[part 1 of 3: package /STELLANTIS/EPT/ASWCs]
AUTOSAR XML (schema 4-2-2)
package /STELLANTIS/EPT/ASWCs
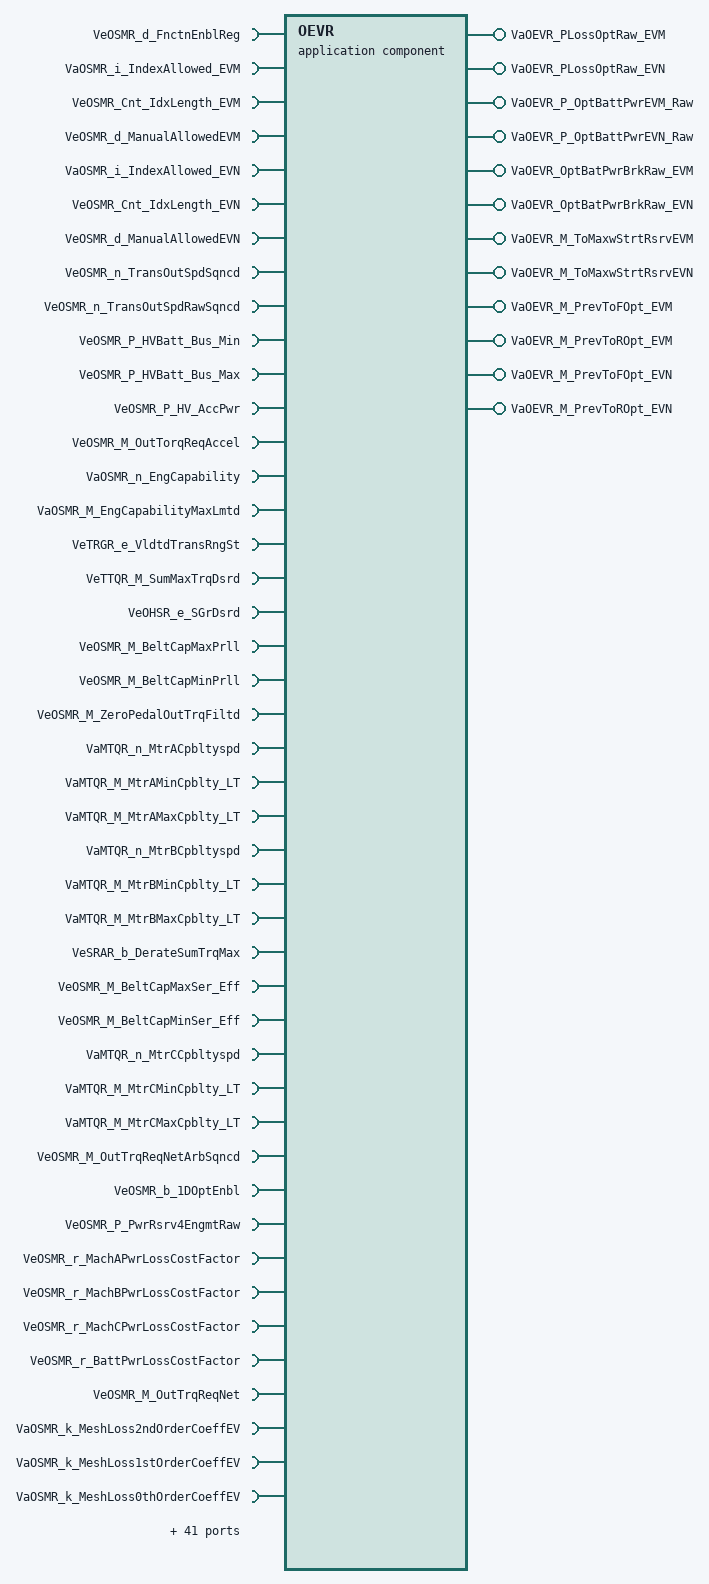
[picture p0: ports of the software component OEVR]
  application sw component type OEVR
    57 x require port:
      VeOSMR_d_FnctnEnblReg: variation-point={short-label=vpVeOSMR_d_FnctnEnblReg, sw-syscond=1}, nonqueued-receiver-com-spec{data-element=Value, init-value=0}, required-interface=VeOSMR_d_FnctnEnblReg
      VaOSMR_i_IndexAllowed_EVM: variation-point={short-label=vpVaOSMR_i_IndexAllowed_EVM, sw-syscond=1}, nonqueued-receiver-com-spec{data-element=Value, init-value=9 x 0}, required-interface=VaOSMR_i_IndexAllowed_EVM
      VeOSMR_Cnt_IdxLength_EVM: variation-point={short-label=vpVeOSMR_Cnt_IdxLength_EVM, sw-syscond=1}, nonqueued-receiver-com-spec{data-element=Value, init-value=0}, required-interface=VeOSMR_Cnt_IdxLength_EVM
      VeOSMR_d_ManualAllowedEVM: variation-point={short-label=vpVeOSMR_d_ManualAllowedEVM, sw-syscond=1}, nonqueued-receiver-com-spec{data-element=Value, init-value=0}, required-interface=VeOSMR_d_ManualAllowedEVM
      VaOSMR_i_IndexAllowed_EVN: variation-point={short-label=vpVaOSMR_i_IndexAllowed_EVN, sw-syscond=1}, nonqueued-receiver-com-spec{data-element=Value, init-value=9 x 0}, required-interface=VaOSMR_i_IndexAllowed_EVN
      VeOSMR_Cnt_IdxLength_EVN: variation-point={short-label=vpVeOSMR_Cnt_IdxLength_EVN, sw-syscond=1}, nonqueued-receiver-com-spec{data-element=Value, init-value=0}, required-interface=VeOSMR_Cnt_IdxLength_EVN
      VeOSMR_d_ManualAllowedEVN: variation-point={short-label=vpVeOSMR_d_ManualAllowedEVN, sw-syscond=1}, nonqueued-receiver-com-spec{data-element=Value, init-value=0}, required-interface=VeOSMR_d_ManualAllowedEVN
      VeOSMR_n_TransOutSpdSqncd: variation-point={short-label=vpVeOSMR_n_TransOutSpdSqncd, sw-syscond=1}, nonqueued-receiver-com-spec{data-element=Value, init-value=0}, required-interface=VeOSMR_n_TransOutSpdSqncd
      VeOSMR_n_TransOutSpdRawSqncd: nonqueued-receiver-com-spec{data-element=Value, init-value=0}, required-interface=VeOSMR_n_TransOutSpdRawSqncd
      VeOSMR_P_HVBatt_Bus_Min: variation-point={short-label=vpVeOSMR_P_HVBatt_Bus_Min, sw-syscond=1}, nonqueued-receiver-com-spec{data-element=Value, init-value=0}, required-interface=VeOSMR_P_HVBatt_Bus_Min
      VeOSMR_P_HVBatt_Bus_Max: variation-point={short-label=vpVeOSMR_P_HVBatt_Bus_Max, sw-syscond=1}, nonqueued-receiver-com-spec{data-element=Value, init-value=0}, required-interface=VeOSMR_P_HVBatt_Bus_Max
      VeOSMR_P_HV_AccPwr: variation-point={short-label=vpVeOSMR_P_HV_AccPwr, sw-syscond=1}, nonqueued-receiver-com-spec{data-element=Value, init-value=0}, required-interface=VeOSMR_P_HV_AccPwr
      VeOSMR_M_OutTorqReqAccel: variation-point={short-label=vpVeOSMR_M_OutTorqReqAccel, sw-syscond=1}, nonqueued-receiver-com-spec{data-element=Value, init-value=0}, required-interface=VeOSMR_M_OutTorqReqAccel
      VaOSMR_n_EngCapability: nonqueued-receiver-com-spec{data-element=Value, init-value=16 x 0}, required-interface=VaOSMR_n_EngCapability
      VaOSMR_M_EngCapabilityMaxLmtd: nonqueued-receiver-com-spec{data-element=Value, init-value=16 x 0}, required-interface=VaOSMR_M_EngCapabilityMaxLmtd
      VeTRGR_e_VldtdTransRngSt: variation-point={short-label=vpVeTRGR_e_VldtdTransRngSt, sw-syscond=1}, nonqueued-receiver-com-spec{data-element=Value, init-value=CeTRGR_e_NoSelectionAvailable}, required-interface=VeTRGR_e_VldtdTransRngSt
      VeTTQR_M_SumMaxTrqDsrd: variation-point={short-label=vpVeTTQR_M_SumMaxTrqDsrd, sw-syscond=1}, nonqueued-receiver-com-spec{data-element=Value, init-value=0}, required-interface=VeTTQR_M_SumMaxTrqDsrd
      VeOHSR_e_SGrDsrd: nonqueued-receiver-com-spec{data-element=Value, init-value=CeOHSR_e_SG_Reverse}, required-interface=VeOHSR_e_SGrDsrd
      VeOSMR_M_BeltCapMaxPrll: variation-point={short-label=vpVeOSMR_M_BeltCapMaxPrll, sw-syscond=1}, nonqueued-receiver-com-spec{data-element=Value, init-value=0}, required-interface=VeOSMR_M_BeltCapMaxPrll
      VeOSMR_M_BeltCapMinPrll: variation-point={short-label=vpVeOSMR_M_BeltCapMinPrll, sw-syscond=1}, nonqueued-receiver-com-spec{data-element=Value, init-value=0}, required-interface=VeOSMR_M_BeltCapMinPrll
      VeOSMR_M_ZeroPedalOutTrqFiltd: variation-point={short-label=vpVeOSMR_M_ZeroPedalOutTrqFiltd, sw-syscond=1}, nonqueued-receiver-com-spec{data-element=Value, init-value=0}, required-interface=VeOSMR_M_ZeroPedalOutTrqFiltd
      VaMTQR_n_MtrACpbltyspd: variation-point={short-label=vpVaMTQR_n_MtrACpbltyspd, sw-syscond=1}, nonqueued-receiver-com-spec{data-element=Value, init-value=16 x 0}, required-interface=VaMTQR_n_MtrACpbltyspd
      VaMTQR_M_MtrAMinCpblty_LT: variation-point={short-label=vpVaMTQR_M_MtrAMinCpblty_LT, sw-syscond=1}, nonqueued-receiver-com-spec{data-element=Value, init-value=16 x 0}, required-interface=VaMTQR_M_MtrAMinCpblty_LT
      VaMTQR_M_MtrAMaxCpblty_LT: variation-point={short-label=vpVaMTQR_M_MtrAMaxCpblty_LT, sw-syscond=1}, nonqueued-receiver-com-spec{data-element=Value, init-value=16 x 0}, required-interface=VaMTQR_M_MtrAMaxCpblty_LT
      VaMTQR_n_MtrBCpbltyspd: variation-point={short-label=vpVaMTQR_n_MtrBCpbltyspd, sw-syscond=1}, nonqueued-receiver-com-spec{data-element=Value, init-value=16 x 0}, required-interface=VaMTQR_n_MtrBCpbltyspd
      VaMTQR_M_MtrBMinCpblty_LT: variation-point={short-label=vpVaMTQR_M_MtrBMinCpblty_LT, sw-syscond=1}, nonqueued-receiver-com-spec{data-element=Value, init-value=16 x 0}, required-interface=VaMTQR_M_MtrBMinCpblty_LT
      VaMTQR_M_MtrBMaxCpblty_LT: variation-point={short-label=vpVaMTQR_M_MtrBMaxCpblty_LT, sw-syscond=1}, nonqueued-receiver-com-spec{data-element=Value, init-value=16 x 0}, required-interface=VaMTQR_M_MtrBMaxCpblty_LT
      VeSRAR_b_DerateSumTrqMax: variation-point={short-label=vpVeSRAR_b_DerateSumTrqMax, sw-syscond=1}, nonqueued-receiver-com-spec{data-element=Value, init-value=0}, required-interface=VeSRAR_b_DerateSumTrqMax
      VeOSMR_M_BeltCapMaxSer_Eff: variation-point={short-label=vpVeOSMR_M_BeltCapMaxSer_Eff, sw-syscond=1}, nonqueued-receiver-com-spec{data-element=Value, init-value=0}, required-interface=VeOSMR_M_BeltCapMaxSer_Eff
      VeOSMR_M_BeltCapMinSer_Eff: variation-point={short-label=vpVeOSMR_M_BeltCapMinSer_Eff, sw-syscond=1}, nonqueued-receiver-com-spec{data-element=Value, init-value=0}, required-interface=VeOSMR_M_BeltCapMinSer_Eff
      VaMTQR_n_MtrCCpbltyspd: variation-point={short-label=vpVaMTQR_n_MtrCCpbltyspd, sw-syscond=1}, nonqueued-receiver-com-spec{data-element=Value, init-value=16 x 0}, required-interface=VaMTQR_n_MtrCCpbltyspd
      VaMTQR_M_MtrCMinCpblty_LT: variation-point={short-label=vpVaMTQR_M_MtrCMinCpblty_LT, sw-syscond=1}, nonqueued-receiver-com-spec{data-element=Value, init-value=16 x 0}, required-interface=VaMTQR_M_MtrCMinCpblty_LT
      VaMTQR_M_MtrCMaxCpblty_LT: variation-point={short-label=vpVaMTQR_M_MtrCMaxCpblty_LT, sw-syscond=1}, nonqueued-receiver-com-spec{data-element=Value, init-value=16 x 0}, required-interface=VaMTQR_M_MtrCMaxCpblty_LT
      VeOSMR_M_OutTrqReqNetArbSqncd: variation-point={short-label=vpVeOSMR_M_OutTrqReqNetArbSqncd, sw-syscond=1}, nonqueued-receiver-com-spec{data-element=Value, init-value=0}, required-interface=VeOSMR_M_OutTrqReqNetArbSqncd
      VeOSMR_b_1DOptEnbl: variation-point={short-label=vpVeOSMR_b_1DOptEnbl, sw-syscond=1}, nonqueued-receiver-com-spec{data-element=Value, init-value=0}, required-interface=VeOSMR_b_1DOptEnbl
      VeOSMR_P_PwrRsrv4EngmtRaw: variation-point={short-label=vpVeOSMR_P_PwrRsrv4EngmtRaw, sw-syscond=1}, nonqueued-receiver-com-spec{data-element=Value, init-value=0}, required-interface=VeOSMR_P_PwrRsrv4EngmtRaw
      VeOSMR_r_MachAPwrLossCostFactor: variation-point={short-label=vpVeOSMR_r_MachAPwrLossCostFactor, sw-syscond=1}, nonqueued-receiver-com-spec{data-element=Value, init-value=0}, required-interface=VeOSMR_r_MachAPwrLossCostFactor
      VeOSMR_r_MachBPwrLossCostFactor: variation-point={short-label=vpVeOSMR_r_MachBPwrLossCostFactor, sw-syscond=1}, nonqueued-receiver-com-spec{data-element=Value, init-value=0}, required-interface=VeOSMR_r_MachBPwrLossCostFactor
      VeOSMR_r_MachCPwrLossCostFactor: variation-point={short-label=vpVeOSMR_r_MachCPwrLossCostFactor, sw-syscond=1}, nonqueued-receiver-com-spec{data-element=Value, init-value=0}, required-interface=VeOSMR_r_MachCPwrLossCostFactor
      VeOSMR_r_BattPwrLossCostFactor: variation-point={short-label=vpVeOSMR_r_BattPwrLossCostFactor, sw-syscond=1}, nonqueued-receiver-com-spec{data-element=Value, init-value=0}, required-interface=VeOSMR_r_BattPwrLossCostFactor
      VeOSMR_M_OutTrqReqNet: variation-point={short-label=vpVeOSMR_M_OutTrqReqNet, sw-syscond=1}, nonqueued-receiver-com-spec{data-element=Value, init-value=0}, required-interface=VeOSMR_M_OutTrqReqNet
      VaOSMR_k_MeshLoss2ndOrderCoeffEV: variation-point={short-label=vpVaOSMR_k_MeshLoss2ndOrderCoeffEV, sw-syscond=1}, nonqueued-receiver-com-spec{data-element=Value, init-value=9 x 0}, required-interface=VaOSMR_k_MeshLoss2ndOrderCoeffEV
      VaOSMR_k_MeshLoss1stOrderCoeffEV: variation-point={short-label=vpVaOSMR_k_MeshLoss1stOrderCoeffEV, sw-syscond=1}, nonqueued-receiver-com-spec{data-element=Value, init-value=9 x 0}, required-interface=VaOSMR_k_MeshLoss1stOrderCoeffEV
      VaOSMR_k_MeshLoss0thOrderCoeffEV: variation-point={short-label=vpVaOSMR_k_MeshLoss0thOrderCoeffEV, sw-syscond=1}, nonqueued-receiver-com-spec{data-element=Value, init-value=9 x 0}, required-interface=VaOSMR_k_MeshLoss0thOrderCoeffEV
      VeOSMR_M_ToFront4x4_Max: variation-point={short-label=vpVeOSMR_M_ToFront4x4_Max, sw-syscond=1}, nonqueued-receiver-com-spec{data-element=Value, init-value=0}, required-interface=VeOSMR_M_ToFront4x4_Max
      VeOSMR_M_ToFront4x4_Min: variation-point={short-label=vpVeOSMR_M_ToFront4x4_Min, sw-syscond=1}, nonqueued-receiver-com-spec{data-element=Value, init-value=0}, required-interface=VeOSMR_M_ToFront4x4_Min
      VeOSMR_M_ToRear4x4_Max: variation-point={short-label=vpVeOSMR_M_ToRear4x4_Max, sw-syscond=1}, nonqueued-receiver-com-spec{data-element=Value, init-value=0}, required-interface=VeOSMR_M_ToRear4x4_Max
      VeOSMR_M_ToRear4x4_Min: variation-point={short-label=vpVeOSMR_M_ToRear4x4_Min, sw-syscond=1}, nonqueued-receiver-com-spec{data-element=Value, init-value=0}, required-interface=VeOSMR_M_ToRear4x4_Min
      VeOSMR_b_StgcRIPEnblOutTorqAccel: variation-point={short-label=vpVeOSMR_b_StgcRIPEnblOutTorqAccel, sw-syscond=1}, nonqueued-receiver-com-spec{data-element=Value, init-value=0}, required-interface=VeOSMR_b_StgcRIPEnblOutTorqAccel
      VeOSMR_b_StgcRIPEnblOutTorqNet: variation-point={short-label=vpVeOSMR_b_StgcRIPEnblOutTorqNet, sw-syscond=1}, nonqueued-receiver-com-spec{data-element=Value, init-value=0}, required-interface=VeOSMR_b_StgcRIPEnblOutTorqNet
      VeOSMR_r_StgcRIPratioOutTorqAccel: variation-point={short-label=vpVeOSMR_r_StgcRIPratioOutTorqAccel, sw-syscond=1}, nonqueued-receiver-com-spec{data-element=Value, init-value=0}, required-interface=VeOSMR_r_StgcRIPratioOutTorqAccel
      VeOSMR_r_StgcRIPratioOutTorqNet: variation-point={short-label=vpVeOSMR_r_StgcRIPratioOutTorqNet, sw-syscond=1}, nonqueued-receiver-com-spec{data-element=Value, init-value=0}, required-interface=VeOSMR_r_StgcRIPratioOutTorqNet
      VaOSMR_M_ToFToRLimOL: variation-point={short-label=vpVaOSMR_M_ToFToRLimOL, sw-syscond=1}, nonqueued-receiver-com-spec{data-element=Value, init-value=[0, 0, 0, 0]}, required-interface=VaOSMR_M_ToFToRLimOL
      VaOSMR_n_NC1Max_EVN: variation-point={short-label=vpVaOSMR_n_NC1Max_EVN, sw-syscond=1}, nonqueued-receiver-com-spec{data-element=Value, init-value=9 x 0}, required-interface=VaOSMR_n_NC1Max_EVN
      VaOSMR_n_NC1Min_EVN: variation-point={short-label=vpVaOSMR_n_NC1Min_EVN, sw-syscond=1}, nonqueued-receiver-com-spec{data-element=Value, init-value=9 x 0}, required-interface=VaOSMR_n_NC1Min_EVN
      VaOSMR_n_NC2Max_EVN: variation-point={short-label=vpVaOSMR_n_NC2Max_EVN, sw-syscond=1}, nonqueued-receiver-com-spec{data-element=Value, init-value=9 x 0}, required-interface=VaOSMR_n_NC2Max_EVN
      VaOSMR_n_NC2Min_EVN: variation-point={short-label=vpVaOSMR_n_NC2Min_EVN, sw-syscond=1}, nonqueued-receiver-com-spec{data-element=Value, init-value=9 x 0}, required-interface=VaOSMR_n_NC2Min_EVN
    12 x provide port, all with nonqueued-sender-com-spec{data-element=Value, init-value=9 x 0}:
      VaOEVR_PLossOptRaw_EVM: provided-interface=VaOEVR_PLossOptRaw_EVM
      VaOEVR_PLossOptRaw_EVN: provided-interface=VaOEVR_PLossOptRaw_EVN
      VaOEVR_P_OptBattPwrEVM_Raw: provided-interface=VaOEVR_P_OptBattPwrEVM_Raw
      VaOEVR_P_OptBattPwrEVN_Raw: provided-interface=VaOEVR_P_OptBattPwrEVN_Raw
      VaOEVR_OptBatPwrBrkRaw_EVM: provided-interface=VaOEVR_OptBatPwrBrkRaw_EVM
      VaOEVR_OptBatPwrBrkRaw_EVN: provided-interface=VaOEVR_OptBatPwrBrkRaw_EVN
      VaOEVR_M_ToMaxwStrtRsrvEVM: provided-interface=VaOEVR_M_ToMaxwStrtRsrvEVM
      VaOEVR_M_ToMaxwStrtRsrvEVN: provided-interface=VaOEVR_M_ToMaxwStrtRsrvEVN
      VaOEVR_M_PrevToFOpt_EVM: provided-interface=VaOEVR_M_PrevToFOpt_EVM
      VaOEVR_M_PrevToROpt_EVM: provided-interface=VaOEVR_M_PrevToROpt_EVM
      VaOEVR_M_PrevToFOpt_EVN: provided-interface=VaOEVR_M_PrevToFOpt_EVN
      VaOEVR_M_PrevToROpt_EVN: provided-interface=VaOEVR_M_PrevToROpt_EVN
    129 x require port:
      CaOPTR_r_TimpMaxArray: parameter-require-com-spec{init-value=CaOPTR_r_TimpMaxArray_CaOPTR_r_TimpMaxArray:[CaOPTR_r_TimpMaxArray_CaOPTR_r_TimpMaxArray_rt_Array_Float_16_1:100000, CaOPTR_r_TimpMaxArray_CaOPTR_r_TimpMaxArray_rt_Array_Float_16_2:100000, CaOPTR_r_TimpMaxArray_CaOPTR_r_TimpMaxArray_rt_Array_Float_16_3:100000, CaOPTR_r_TimpMaxArray_CaOPTR_r_TimpMaxArray_rt_Array_Float_16_4:100000, CaOPTR_r_TimpMaxArray_CaOPTR_r_TimpMaxArray_rt_Array_Float_16_5:100000, CaOPTR_r_TimpMaxArray_CaOPTR_r_TimpMaxArray_rt_Array_Float_16_6:100000, CaOPTR_r_TimpMaxArray_CaOPTR_r_TimpMaxArray_rt_Array_Float_16_7:100000, CaOPTR_r_TimpMaxArray_CaOPTR_r_TimpMaxArray_rt_Array_Float_16_8:100000, CaOPTR_r_TimpMaxArray_CaOPTR_r_TimpMaxArray_rt_Array_Float_16_9:100000, CaOPTR_r_TimpMaxArray_CaOPTR_r_TimpMaxArray_rt_Array_Float_16_10:100000, CaOPTR_r_TimpMaxArray_CaOPTR_r_TimpMaxArray_rt_Array_Float_16_11:100000, CaOPTR_r_TimpMaxArray_CaOPTR_r_TimpMaxArray_rt_Array_Float_16_12:100000, CaOPTR_r_TimpMaxArray_CaOPTR_r_TimpMaxArray_rt_Array_Float_16_13:100000, CaOPTR_r_TimpMaxArray_CaOPTR_r_TimpMaxArray_rt_Array_Float_16_14:100000, CaOPTR_r_TimpMaxArray_CaOPTR_r_TimpMaxArray_rt_Array_Float_16_15:100000, CaOPTR_r_TimpMaxArray_CaOPTR_r_TimpMaxArray_rt_Array_Float_16_16:100000], parameter=CaOPTR_r_TimpMaxArray}, required-interface=CaOPTR_r_TimpMaxArray
      CaOPTR_r_ZeroArray: parameter-require-com-spec{init-value=CaOPTR_r_ZeroArray_CaOPTR_r_ZeroArray:[CaOPTR_r_ZeroArray_CaOPTR_r_ZeroArray_rt_Array_Float_9_1:0, CaOPTR_r_ZeroArray_CaOPTR_r_ZeroArray_rt_Array_Float_9_2:0, CaOPTR_r_ZeroArray_CaOPTR_r_ZeroArray_rt_Array_Float_9_3:0, CaOPTR_r_ZeroArray_CaOPTR_r_ZeroArray_rt_Array_Float_9_4:0, CaOPTR_r_ZeroArray_CaOPTR_r_ZeroArray_rt_Array_Float_9_5:0, CaOPTR_r_ZeroArray_CaOPTR_r_ZeroArray_rt_Array_Float_9_6:0, CaOPTR_r_ZeroArray_CaOPTR_r_ZeroArray_rt_Array_Float_9_7:0, CaOPTR_r_ZeroArray_CaOPTR_r_ZeroArray_rt_Array_Float_9_8:0, CaOPTR_r_ZeroArray_CaOPTR_r_ZeroArray_rt_Array_Float_9_9:0], parameter=CaOPTR_r_ZeroArray}, required-interface=CaOPTR_r_ZeroArray
      HaOPTR_r_NimpCalcEqnMtrx: parameter-require-com-spec{init-value=HaOPTR_r_NimpCalcEqnMtrx_HaOPTR_r_NimpCalcEqnMtrx:[HaOPTR_r_NimpCalcEqnMtrx_HaOPTR_r_NimpCalcEqnMtrx_rt_Array_Float_3_1:0, HaOPTR_r_NimpCalcEqnMtrx_HaOPTR_r_NimpCalcEqnMtrx_rt_Array_Float_3_2:0, HaOPTR_r_NimpCalcEqnMtrx_HaOPTR_r_NimpCalcEqnMtrx_rt_Array_Float_3_3:0], parameter=HaOPTR_r_NimpCalcEqnMtrx}, required-interface=HaOPTR_r_NimpCalcEqnMtrx
      HaOPTR_r_NturbCalcEqnMtrx: parameter-require-com-spec{init-value=HaOPTR_r_NturbCalcEqnMtrx_HaOPTR_r_NturbCalcEqnMtrx:[HaOPTR_r_NturbCalcEqnMtrx_HaOPTR_r_NturbCalcEqnMtrx_rt_Array_Float_3_1:0, HaOPTR_r_NturbCalcEqnMtrx_HaOPTR_r_NturbCalcEqnMtrx_rt_Array_Float_3_2:0, HaOPTR_r_NturbCalcEqnMtrx_HaOPTR_r_NturbCalcEqnMtrx_rt_Array_Float_3_3:0], parameter=HaOPTR_r_NturbCalcEqnMtrx}, required-interface=HaOPTR_r_NturbCalcEqnMtrx
      KaHSCR_k_Donut_Space_Coefs_A1: parameter-require-com-spec{init-value=KaHSCR_k_Donut_Space_Coefs_A1_KaHSCR_k_Donut_Space_Coefs_A1:[KaHSCR_k_Donut_Space_Coefs_A1_KaHSCR_k_Donut_Space_Coefs_A1_rt_Array_Float_34_1:0.0258900001645088, KaHSCR_k_Donut_Space_Coefs_A1_KaHSCR_k_Donut_Space_Coefs_A1_rt_Array_Float_34_2:0.0258900001645088, KaHSCR_k_Donut_Space_Coefs_A1_KaHSCR_k_Donut_Space_Coefs_A1_rt_Array_Float_34_3:0.0351000018417835, KaHSCR_k_Donut_Space_Coefs_A1_KaHSCR_k_Donut_Space_Coefs_A1_rt_Array_Float_34_4:0.0372599996626377, KaHSCR_k_Donut_Space_Coefs_A1_KaHSCR_k_Donut_Space_Coefs_A1_rt_Array_Float_34_5:0.0378299988806248, KaHSCR_k_Donut_Space_Coefs_A1_KaHSCR_k_Donut_Space_Coefs_A1_rt_Array_Float_34_6:0.0382400006055832, KaHSCR_k_Donut_Space_Coefs_A1_KaHSCR_k_Donut_Space_Coefs_A1_rt_Array_Float_34_7:0.0386399887502193, KaHSCR_k_Donut_Space_Coefs_A1_KaHSCR_k_Donut_Space_Coefs_A1_rt_Array_Float_34_8:0.0405225306749344, KaHSCR_k_Donut_Space_Coefs_A1_KaHSCR_k_Donut_Space_Coefs_A1_rt_Array_Float_34_9:0.0411508604884148, KaHSCR_k_Donut_Space_Coefs_A1_KaHSCR_k_Donut_Space_Coefs_A1_rt_Array_Float_34_10:0.0418944396078587, KaHSCR_k_Donut_Space_Coefs_A1_KaHSCR_k_Donut_Space_Coefs_A1_rt_Array_Float_34_11:0.0425894781947136, KaHSCR_k_Donut_Space_Coefs_A1_KaHSCR_k_Donut_Space_Coefs_A1_rt_Array_Float_34_12:0.0431920886039734, KaHSCR_k_Donut_Space_Coefs_A1_KaHSCR_k_Donut_Space_Coefs_A1_rt_Array_Float_34_13:0.0436835289001465, KaHSCR_k_Donut_Space_Coefs_A1_KaHSCR_k_Donut_Space_Coefs_A1_rt_Array_Float_34_14:0.0443845391273499, KaHSCR_k_Donut_Space_Coefs_A1_KaHSCR_k_Donut_Space_Coefs_A1_rt_Array_Float_34_15:0.0450701601803303, KaHSCR_k_Donut_Space_Coefs_A1_KaHSCR_k_Donut_Space_Coefs_A1_rt_Array_Float_34_16:0.0456303507089615, KaHSCR_k_Donut_Space_Coefs_A1_KaHSCR_k_Donut_Space_Coefs_A1_rt_Array_Float_34_17:0.0466340184211731, KaHSCR_k_Donut_Space_Coefs_A1_KaHSCR_k_Donut_Space_Coefs_A1_rt_Array_Float_34_18:0.0474497117102146, KaHSCR_k_Donut_Space_Coefs_A1_KaHSCR_k_Donut_Space_Coefs_A1_rt_Array_Float_34_19:0.0479614101350307, KaHSCR_k_Donut_Space_Coefs_A1_KaHSCR_k_Donut_Space_Coefs_A1_rt_Array_Float_34_20:0.0484260395169258, KaHSCR_k_Donut_Space_Coefs_A1_KaHSCR_k_Donut_Space_Coefs_A1_rt_Array_Float_34_21:0.0488490909337997, KaHSCR_k_Donut_Space_Coefs_A1_KaHSCR_k_Donut_Space_Coefs_A1_rt_Array_Float_34_22:0.0494564808905125, KaHSCR_k_Donut_Space_Coefs_A1_KaHSCR_k_Donut_Space_Coefs_A1_rt_Array_Float_34_23:0.050324771553278, KaHSCR_k_Donut_Space_Coefs_A1_KaHSCR_k_Donut_Space_Coefs_A1_rt_Array_Float_34_24:0.0511159785091877, KaHSCR_k_Donut_Space_Coefs_A1_KaHSCR_k_Donut_Space_Coefs_A1_rt_Array_Float_34_25:0.0516291595995426, KaHSCR_k_Donut_Space_Coefs_A1_KaHSCR_k_Donut_Space_Coefs_A1_rt_Array_Float_34_26:0.051756490021944, KaHSCR_k_Donut_Space_Coefs_A1_KaHSCR_k_Donut_Space_Coefs_A1_rt_Array_Float_34_27:0.0519887804985046, KaHSCR_k_Donut_Space_Coefs_A1_KaHSCR_k_Donut_Space_Coefs_A1_rt_Array_Float_34_28:0.0530802011489868, KaHSCR_k_Donut_Space_Coefs_A1_KaHSCR_k_Donut_Space_Coefs_A1_rt_Array_Float_34_29:0.0536961182951927, KaHSCR_k_Donut_Space_Coefs_A1_KaHSCR_k_Donut_Space_Coefs_A1_rt_Array_Float_34_30:0.054239921271801, KaHSCR_k_Donut_Space_Coefs_A1_KaHSCR_k_Donut_Space_Coefs_A1_rt_Array_Float_34_31:0.0550949200987816, KaHSCR_k_Donut_Space_Coefs_A1_KaHSCR_k_Donut_Space_Coefs_A1_rt_Array_Float_34_32:0.0563113614916801, KaHSCR_k_Donut_Space_Coefs_A1_KaHSCR_k_Donut_Space_Coefs_A1_rt_Array_Float_34_33:0.0575419701635838, KaHSCR_k_Donut_Space_Coefs_A1_KaHSCR_k_Donut_Space_Coefs_A1_rt_Array_Float_34_34:0.0587838590145111], parameter=KaHSCR_k_Donut_Space_Coefs_A1}, required-interface=KaHSCR_k_Donut_Space_Coefs_A1
      KaHSCR_k_Donut_Space_Coefs_A2: parameter-require-com-spec{init-value=KaHSCR_k_Donut_Space_Coefs_A2_KaHSCR_k_Donut_Space_Coefs_A2:[KaHSCR_k_Donut_Space_Coefs_A2_KaHSCR_k_Donut_Space_Coefs_A2_rt_Array_Float_34_1:-5.04978709276475E-18, KaHSCR_k_Donut_Space_Coefs_A2_KaHSCR_k_Donut_Space_Coefs_A2_rt_Array_Float_34_2:-5.04978709276475E-18, KaHSCR_k_Donut_Space_Coefs_A2_KaHSCR_k_Donut_Space_Coefs_A2_rt_Array_Float_34_3:0.639999985694885, KaHSCR_k_Donut_Space_Coefs_A2_KaHSCR_k_Donut_Space_Coefs_A2_rt_Array_Float_34_4:1.19000005722046, KaHSCR_k_Donut_Space_Coefs_A2_KaHSCR_k_Donut_Space_Coefs_A2_rt_Array_Float_34_5:1.75999999046326, KaHSCR_k_Donut_Space_Coefs_A2_KaHSCR_k_Donut_Space_Coefs_A2_rt_Array_Float_34_6:2.30999994277954, KaHSCR_k_Donut_Space_Coefs_A2_KaHSCR_k_Donut_Space_Coefs_A2_rt_Array_Float_34_7:2.85999989509583, KaHSCR_k_Donut_Space_Coefs_A2_KaHSCR_k_Donut_Space_Coefs_A2_rt_Array_Float_34_8:3.33561706542969, KaHSCR_k_Donut_Space_Coefs_A2_KaHSCR_k_Donut_Space_Coefs_A2_rt_Array_Float_34_9:3.81586289405823, KaHSCR_k_Donut_Space_Coefs_A2_KaHSCR_k_Donut_Space_Coefs_A2_rt_Array_Float_34_10:4.27816390991211, KaHSCR_k_Donut_Space_Coefs_A2_KaHSCR_k_Donut_Space_Coefs_A2_rt_Array_Float_34_11:4.72691488265991, KaHSCR_k_Donut_Space_Coefs_A2_KaHSCR_k_Donut_Space_Coefs_A2_rt_Array_Float_34_12:5.16561794281006, KaHSCR_k_Donut_Space_Coefs_A2_KaHSCR_k_Donut_Space_Coefs_A2_rt_Array_Float_34_13:5.61427307128906, KaHSCR_k_Donut_Space_Coefs_A2_KaHSCR_k_Donut_Space_Coefs_A2_rt_Array_Float_34_14:6.01499605178833, KaHSCR_k_Donut_Space_Coefs_A2_KaHSCR_k_Donut_Space_Coefs_A2_rt_Array_Float_34_15:6.42061996459961, KaHSCR_k_Donut_Space_Coefs_A2_KaHSCR_k_Donut_Space_Coefs_A2_rt_Array_Float_34_16:6.81864976882935, KaHSCR_k_Donut_Space_Coefs_A2_KaHSCR_k_Donut_Space_Coefs_A2_rt_Array_Float_34_17:7.15260887145996, KaHSCR_k_Donut_Space_Coefs_A2_KaHSCR_k_Donut_Space_Coefs_A2_rt_Array_Float_34_18:7.50815296173096, KaHSCR_k_Donut_Space_Coefs_A2_KaHSCR_k_Donut_Space_Coefs_A2_rt_Array_Float_34_19:7.88588094711304, KaHSCR_k_Donut_Space_Coefs_A2_KaHSCR_k_Donut_Space_Coefs_A2_rt_Array_Float_34_20:8.26707172393799, KaHSCR_k_Donut_Space_Coefs_A2_KaHSCR_k_Donut_Space_Coefs_A2_rt_Array_Float_34_21:8.64353656768799, KaHSCR_k_Donut_Space_Coefs_A2_KaHSCR_k_Donut_Space_Coefs_A2_rt_Array_Float_34_22:8.99045372009277, KaHSCR_k_Donut_Space_Coefs_A2_KaHSCR_k_Donut_Space_Coefs_A2_rt_Array_Float_34_23:9.27973079681396, KaHSCR_k_Donut_Space_Coefs_A2_KaHSCR_k_Donut_Space_Coefs_A2_rt_Array_Float_34_24:9.56464672088623, KaHSCR_k_Donut_Space_Coefs_A2_KaHSCR_k_Donut_Space_Coefs_A2_rt_Array_Float_34_25:9.88457489013672, KaHSCR_k_Donut_Space_Coefs_A2_KaHSCR_k_Donut_Space_Coefs_A2_rt_Array_Float_34_26:10.2705402374268, KaHSCR_k_Donut_Space_Coefs_A2_KaHSCR_k_Donut_Space_Coefs_A2_rt_Array_Float_34_27:10.658860206604, KaHSCR_k_Donut_Space_Coefs_A2_KaHSCR_k_Donut_Space_Coefs_A2_rt_Array_Float_34_28:10.8600997924805, KaHSCR_k_Donut_Space_Coefs_A2_KaHSCR_k_Donut_Space_Coefs_A2_rt_Array_Float_34_29:11.1487503051758, KaHSCR_k_Donut_Space_Coefs_A2_KaHSCR_k_Donut_Space_Coefs_A2_rt_Array_Float_34_30:11.4441699981689, KaHSCR_k_Donut_Space_Coefs_A2_KaHSCR_k_Donut_Space_Coefs_A2_rt_Array_Float_34_31:11.6732902526855, KaHSCR_k_Donut_Space_Coefs_A2_KaHSCR_k_Donut_Space_Coefs_A2_rt_Array_Float_34_32:11.8130502700806, KaHSCR_k_Donut_Space_Coefs_A2_KaHSCR_k_Donut_Space_Coefs_A2_rt_Array_Float_34_33:11.9453201293945, KaHSCR_k_Donut_Space_Coefs_A2_KaHSCR_k_Donut_Space_Coefs_A2_rt_Array_Float_34_34:12.0616703033447], parameter=KaHSCR_k_Donut_Space_Coefs_A2}, required-interface=KaHSCR_k_Donut_Space_Coefs_A2
      KaHSCR_k_Donut_Space_Coefs_B1: parameter-require-com-spec{init-value=KaHSCR_k_Donut_Space_Coefs_B1_KaHSCR_k_Donut_Space_Coefs_B1:[KaHSCR_k_Donut_Space_Coefs_B1_KaHSCR_k_Donut_Space_Coefs_B1_rt_Array_Float_34_1:0.0258900001645088, KaHSCR_k_Donut_Space_Coefs_B1_KaHSCR_k_Donut_Space_Coefs_B1_rt_Array_Float_34_2:0.0258900001645088, KaHSCR_k_Donut_Space_Coefs_B1_KaHSCR_k_Donut_Space_Coefs_B1_rt_Array_Float_34_3:0.0351000018417835, KaHSCR_k_Donut_Space_Coefs_B1_KaHSCR_k_Donut_Space_Coefs_B1_rt_Array_Float_34_4:0.0372599996626377, KaHSCR_k_Donut_Space_Coefs_B1_KaHSCR_k_Donut_Space_Coefs_B1_rt_Array_Float_34_5:0.0378299988806248, KaHSCR_k_Donut_Space_Coefs_B1_KaHSCR_k_Donut_Space_Coefs_B1_rt_Array_Float_34_6:0.0382400006055832, KaHSCR_k_Donut_Space_Coefs_B1_KaHSCR_k_Donut_Space_Coefs_B1_rt_Array_Float_34_7:0.0386399887502193, KaHSCR_k_Donut_Space_Coefs_B1_KaHSCR_k_Donut_Space_Coefs_B1_rt_Array_Float_34_8:0.0405225306749344, KaHSCR_k_Donut_Space_Coefs_B1_KaHSCR_k_Donut_Space_Coefs_B1_rt_Array_Float_34_9:0.0411508604884148, KaHSCR_k_Donut_Space_Coefs_B1_KaHSCR_k_Donut_Space_Coefs_B1_rt_Array_Float_34_10:0.0418944396078587, KaHSCR_k_Donut_Space_Coefs_B1_KaHSCR_k_Donut_Space_Coefs_B1_rt_Array_Float_34_11:0.0425894781947136, KaHSCR_k_Donut_Space_Coefs_B1_KaHSCR_k_Donut_Space_Coefs_B1_rt_Array_Float_34_12:0.0431920886039734, KaHSCR_k_Donut_Space_Coefs_B1_KaHSCR_k_Donut_Space_Coefs_B1_rt_Array_Float_34_13:0.0436835289001465, KaHSCR_k_Donut_Space_Coefs_B1_KaHSCR_k_Donut_Space_Coefs_B1_rt_Array_Float_34_14:0.0443845391273499, KaHSCR_k_Donut_Space_Coefs_B1_KaHSCR_k_Donut_Space_Coefs_B1_rt_Array_Float_34_15:0.0450701601803303, KaHSCR_k_Donut_Space_Coefs_B1_KaHSCR_k_Donut_Space_Coefs_B1_rt_Array_Float_34_16:0.0456303507089615, KaHSCR_k_Donut_Space_Coefs_B1_KaHSCR_k_Donut_Space_Coefs_B1_rt_Array_Float_34_17:0.0466340184211731, KaHSCR_k_Donut_Space_Coefs_B1_KaHSCR_k_Donut_Space_Coefs_B1_rt_Array_Float_34_18:0.0474497117102146, KaHSCR_k_Donut_Space_Coefs_B1_KaHSCR_k_Donut_Space_Coefs_B1_rt_Array_Float_34_19:0.0479614101350307, KaHSCR_k_Donut_Space_Coefs_B1_KaHSCR_k_Donut_Space_Coefs_B1_rt_Array_Float_34_20:0.0484260395169258, KaHSCR_k_Donut_Space_Coefs_B1_KaHSCR_k_Donut_Space_Coefs_B1_rt_Array_Float_34_21:0.0488490909337997, KaHSCR_k_Donut_Space_Coefs_B1_KaHSCR_k_Donut_Space_Coefs_B1_rt_Array_Float_34_22:0.0494564808905125, KaHSCR_k_Donut_Space_Coefs_B1_KaHSCR_k_Donut_Space_Coefs_B1_rt_Array_Float_34_23:0.050324771553278, KaHSCR_k_Donut_Space_Coefs_B1_KaHSCR_k_Donut_Space_Coefs_B1_rt_Array_Float_34_24:0.0511159785091877, KaHSCR_k_Donut_Space_Coefs_B1_KaHSCR_k_Donut_Space_Coefs_B1_rt_Array_Float_34_25:0.0516291595995426, KaHSCR_k_Donut_Space_Coefs_B1_KaHSCR_k_Donut_Space_Coefs_B1_rt_Array_Float_34_26:0.051756490021944, KaHSCR_k_Donut_Space_Coefs_B1_KaHSCR_k_Donut_Space_Coefs_B1_rt_Array_Float_34_27:0.0519887804985046, KaHSCR_k_Donut_Space_Coefs_B1_KaHSCR_k_Donut_Space_Coefs_B1_rt_Array_Float_34_28:0.0530802011489868, KaHSCR_k_Donut_Space_Coefs_B1_KaHSCR_k_Donut_Space_Coefs_B1_rt_Array_Float_34_29:0.0536961182951927, KaHSCR_k_Donut_Space_Coefs_B1_KaHSCR_k_Donut_Space_Coefs_B1_rt_Array_Float_34_30:0.054239921271801, KaHSCR_k_Donut_Space_Coefs_B1_KaHSCR_k_Donut_Space_Coefs_B1_rt_Array_Float_34_31:0.0550949200987816, KaHSCR_k_Donut_Space_Coefs_B1_KaHSCR_k_Donut_Space_Coefs_B1_rt_Array_Float_34_32:0.0563113614916801, KaHSCR_k_Donut_Space_Coefs_B1_KaHSCR_k_Donut_Space_Coefs_B1_rt_Array_Float_34_33:0.0575419701635838, KaHSCR_k_Donut_Space_Coefs_B1_KaHSCR_k_Donut_Space_Coefs_B1_rt_Array_Float_34_34:0.0587838590145111], parameter=KaHSCR_k_Donut_Space_Coefs_B1}, required-interface=KaHSCR_k_Donut_Space_Coefs_B1
      KaHSCR_k_Donut_Space_Coefs_B2: parameter-require-com-spec{init-value=KaHSCR_k_Donut_Space_Coefs_B2_KaHSCR_k_Donut_Space_Coefs_B2:[KaHSCR_k_Donut_Space_Coefs_B2_KaHSCR_k_Donut_Space_Coefs_B2_rt_Array_Float_34_1:-5.04978709276475E-18, KaHSCR_k_Donut_Space_Coefs_B2_KaHSCR_k_Donut_Space_Coefs_B2_rt_Array_Float_34_2:-5.04978709276475E-18, KaHSCR_k_Donut_Space_Coefs_B2_KaHSCR_k_Donut_Space_Coefs_B2_rt_Array_Float_34_3:0.639999985694885, KaHSCR_k_Donut_Space_Coefs_B2_KaHSCR_k_Donut_Space_Coefs_B2_rt_Array_Float_34_4:1.19000005722046, KaHSCR_k_Donut_Space_Coefs_B2_KaHSCR_k_Donut_Space_Coefs_B2_rt_Array_Float_34_5:1.75999999046326, KaHSCR_k_Donut_Space_Coefs_B2_KaHSCR_k_Donut_Space_Coefs_B2_rt_Array_Float_34_6:2.30999994277954, KaHSCR_k_Donut_Space_Coefs_B2_KaHSCR_k_Donut_Space_Coefs_B2_rt_Array_Float_34_7:2.85999989509583, KaHSCR_k_Donut_Space_Coefs_B2_KaHSCR_k_Donut_Space_Coefs_B2_rt_Array_Float_34_8:3.33561706542969, KaHSCR_k_Donut_Space_Coefs_B2_KaHSCR_k_Donut_Space_Coefs_B2_rt_Array_Float_34_9:3.81586289405823, KaHSCR_k_Donut_Space_Coefs_B2_KaHSCR_k_Donut_Space_Coefs_B2_rt_Array_Float_34_10:4.27816390991211, KaHSCR_k_Donut_Space_Coefs_B2_KaHSCR_k_Donut_Space_Coefs_B2_rt_Array_Float_34_11:4.72691488265991, KaHSCR_k_Donut_Space_Coefs_B2_KaHSCR_k_Donut_Space_Coefs_B2_rt_Array_Float_34_12:5.16561794281006, KaHSCR_k_Donut_Space_Coefs_B2_KaHSCR_k_Donut_Space_Coefs_B2_rt_Array_Float_34_13:5.61427307128906, KaHSCR_k_Donut_Space_Coefs_B2_KaHSCR_k_Donut_Space_Coefs_B2_rt_Array_Float_34_14:6.01499605178833, KaHSCR_k_Donut_Space_Coefs_B2_KaHSCR_k_Donut_Space_Coefs_B2_rt_Array_Float_34_15:6.42061996459961, KaHSCR_k_Donut_Space_Coefs_B2_KaHSCR_k_Donut_Space_Coefs_B2_rt_Array_Float_34_16:6.81864976882935, KaHSCR_k_Donut_Space_Coefs_B2_KaHSCR_k_Donut_Space_Coefs_B2_rt_Array_Float_34_17:7.15260887145996, KaHSCR_k_Donut_Space_Coefs_B2_KaHSCR_k_Donut_Space_Coefs_B2_rt_Array_Float_34_18:7.50815296173096, KaHSCR_k_Donut_Space_Coefs_B2_KaHSCR_k_Donut_Space_Coefs_B2_rt_Array_Float_34_19:7.88588094711304, KaHSCR_k_Donut_Space_Coefs_B2_KaHSCR_k_Donut_Space_Coefs_B2_rt_Array_Float_34_20:8.26707172393799, KaHSCR_k_Donut_Space_Coefs_B2_KaHSCR_k_Donut_Space_Coefs_B2_rt_Array_Float_34_21:8.64353656768799, KaHSCR_k_Donut_Space_Coefs_B2_KaHSCR_k_Donut_Space_Coefs_B2_rt_Array_Float_34_22:8.99045372009277, KaHSCR_k_Donut_Space_Coefs_B2_KaHSCR_k_Donut_Space_Coefs_B2_rt_Array_Float_34_23:9.27973079681396, KaHSCR_k_Donut_Space_Coefs_B2_KaHSCR_k_Donut_Space_Coefs_B2_rt_Array_Float_34_24:9.56464672088623, KaHSCR_k_Donut_Space_Coefs_B2_KaHSCR_k_Donut_Space_Coefs_B2_rt_Array_Float_34_25:9.88457489013672, KaHSCR_k_Donut_Space_Coefs_B2_KaHSCR_k_Donut_Space_Coefs_B2_rt_Array_Float_34_26:10.2705402374268, KaHSCR_k_Donut_Space_Coefs_B2_KaHSCR_k_Donut_Space_Coefs_B2_rt_Array_Float_34_27:10.658860206604, KaHSCR_k_Donut_Space_Coefs_B2_KaHSCR_k_Donut_Space_Coefs_B2_rt_Array_Float_34_28:10.8600997924805, KaHSCR_k_Donut_Space_Coefs_B2_KaHSCR_k_Donut_Space_Coefs_B2_rt_Array_Float_34_29:11.1487503051758, KaHSCR_k_Donut_Space_Coefs_B2_KaHSCR_k_Donut_Space_Coefs_B2_rt_Array_Float_34_30:11.4441699981689, KaHSCR_k_Donut_Space_Coefs_B2_KaHSCR_k_Donut_Space_Coefs_B2_rt_Array_Float_34_31:11.6732902526855, KaHSCR_k_Donut_Space_Coefs_B2_KaHSCR_k_Donut_Space_Coefs_B2_rt_Array_Float_34_32:11.8130502700806, KaHSCR_k_Donut_Space_Coefs_B2_KaHSCR_k_Donut_Space_Coefs_B2_rt_Array_Float_34_33:11.9453201293945, KaHSCR_k_Donut_Space_Coefs_B2_KaHSCR_k_Donut_Space_Coefs_B2_rt_Array_Float_34_34:12.0616703033447], parameter=KaHSCR_k_Donut_Space_Coefs_B2}, required-interface=KaHSCR_k_Donut_Space_Coefs_B2
      KaHSCR_k_Donut_Space_Coefs_C: parameter-require-com-spec{init-value=KaHSCR_k_Donut_Space_Coefs_C_KaHSCR_k_Donut_Space_Coefs_C:[KaHSCR_k_Donut_Space_Coefs_C_KaHSCR_k_Donut_Space_Coefs_C_rt_Array_Float_34_1:0.103308998048306, KaHSCR_k_Donut_Space_Coefs_C_KaHSCR_k_Donut_Space_Coefs_C_rt_Array_Float_34_2:0.103308998048306, KaHSCR_k_Donut_Space_Coefs_C_KaHSCR_k_Donut_Space_Coefs_C_rt_Array_Float_34_3:-0.211907997727394, KaHSCR_k_Donut_Space_Coefs_C_KaHSCR_k_Donut_Space_Coefs_C_rt_Array_Float_34_4:-1.20062398910522, KaHSCR_k_Donut_Space_Coefs_C_KaHSCR_k_Donut_Space_Coefs_C_rt_Array_Float_34_5:-2.85137605667114, KaHSCR_k_Donut_Space_Coefs_C_KaHSCR_k_Donut_Space_Coefs_C_rt_Array_Float_34_6:-5.10159778594971, KaHSCR_k_Donut_Space_Coefs_C_KaHSCR_k_Donut_Space_Coefs_C_rt_Array_Float_34_7:-7.90723323822021, KaHSCR_k_Donut_Space_Coefs_C_KaHSCR_k_Donut_Space_Coefs_C_rt_Array_Float_34_8:-10.5811996459961, KaHSCR_k_Donut_Space_Coefs_C_KaHSCR_k_Donut_Space_Coefs_C_rt_Array_Float_34_9:-14.0026197433472, KaHSCR_k_Donut_Space_Coefs_C_KaHSCR_k_Donut_Space_Coefs_C_rt_Array_Float_34_10:-17.6751308441162, KaHSCR_k_Donut_Space_Coefs_C_KaHSCR_k_Donut_Space_Coefs_C_rt_Array_Float_34_11:-21.6737899780273, KaHSCR_k_Donut_Space_Coefs_C_KaHSCR_k_Donut_Space_Coefs_C_rt_Array_Float_34_12:-26.0248203277588, KaHSCR_k_Donut_Space_Coefs_C_KaHSCR_k_Donut_Space_Coefs_C_rt_Array_Float_34_13:-30.7496299743652, KaHSCR_k_Donut_Space_Coefs_C_KaHSCR_k_Donut_Space_Coefs_C_rt_Array_Float_34_14:-35.452018737793, KaHSCR_k_Donut_Space_Coefs_C_KaHSCR_k_Donut_Space_Coefs_C_rt_Array_Float_34_15:-40.3361701965332, KaHSCR_k_Donut_Space_Coefs_C_KaHSCR_k_Donut_Space_Coefs_C_rt_Array_Float_34_16:-45.6424903869629, KaHSCR_k_Donut_Space_Coefs_C_KaHSCR_k_Donut_Space_Coefs_C_rt_Array_Float_34_17:-50.2698593139648, KaHSCR_k_Donut_Space_Coefs_C_KaHSCR_k_Donut_Space_Coefs_C_rt_Array_Float_34_18:-55.375659942627, KaHSCR_k_Donut_Space_Coefs_C_KaHSCR_k_Donut_Space_Coefs_C_rt_Array_Float_34_19:-61.2313995361328, KaHSCR_k_Donut_Space_Coefs_C_KaHSCR_k_Donut_Space_Coefs_C_rt_Array_Float_34_20:-67.2626876831055, KaHSCR_k_Donut_Space_Coefs_C_KaHSCR_k_Donut_Space_Coefs_C_rt_Array_Float_34_21:-73.5646362304688, KaHSCR_k_Donut_Space_Coefs_C_KaHSCR_k_Donut_Space_Coefs_C_rt_Array_Float_34_22:-79.621467590332, KaHSCR_k_Donut_Space_Coefs_C_KaHSCR_k_Donut_Space_Coefs_C_rt_Array_Float_34_23:-84.9908294677734, KaHSCR_k_Donut_Space_Coefs_C_KaHSCR_k_Donut_Space_Coefs_C_rt_Array_Float_34_24:-90.269172668457, KaHSCR_k_Donut_Space_Coefs_C_KaHSCR_k_Donut_Space_Coefs_C_rt_Array_Float_34_25:-96.3239364624023, KaHSCR_k_Donut_Space_Coefs_C_KaHSCR_k_Donut_Space_Coefs_C_rt_Array_Float_34_26:-104.145500183105, KaHSCR_k_Donut_Space_Coefs_C_KaHSCR_k_Donut_Space_Coefs_C_rt_Array_Float_34_27:-112.130699157715, KaHSCR_k_Donut_Space_Coefs_C_KaHSCR_k_Donut_Space_Coefs_C_rt_Array_Float_34_28:-116.38639831543, KaHSCR_k_Donut_Space_Coefs_C_KaHSCR_k_Donut_Space_Coefs_C_rt_Array_Float_34_29:-122.710998535156, KaHSCR_k_Donut_Space_Coefs_C_KaHSCR_k_Donut_Space_Coefs_C_rt_Array_Float_34_30:-129.441192626953, KaHSCR_k_Donut_Space_Coefs_C_KaHSCR_k_Donut_Space_Coefs_C_rt_Array_Float_34_31:-134.5126953125, KaHSCR_k_Donut_Space_Coefs_C_KaHSCR_k_Donut_Space_Coefs_C_rt_Array_Float_34_32:-137.768402099609, KaHSCR_k_Donut_Space_Coefs_C_KaHSCR_k_Donut_Space_Coefs_C_rt_Array_Float_34_33:-140.760498046875, KaHSCR_k_Donut_Space_Coefs_C_KaHSCR_k_Donut_Space_Coefs_C_rt_Array_Float_34_34:-143.608093261719], parameter=KaHSCR_k_Donut_Space_Coefs_C}, required-interface=KaHSCR_k_Donut_Space_Coefs_C
      KaHSCR_k_Donut_Space_Coefs_C1: parameter-require-com-spec{init-value=KaHSCR_k_Donut_Space_Coefs_C1_KaHSCR_k_Donut_Space_Coefs_C1:[KaHSCR_k_Donut_Space_Coefs_C1_KaHSCR_k_Donut_Space_Coefs_C1_rt_Array_Float_34_1:0.0258900001645088, KaHSCR_k_Donut_Space_Coefs_C1_KaHSCR_k_Donut_Space_Coefs_C1_rt_Array_Float_34_2:0.0258900001645088, KaHSCR_k_Donut_Space_Coefs_C1_KaHSCR_k_Donut_Space_Coefs_C1_rt_Array_Float_34_3:0.0351000018417835, KaHSCR_k_Donut_Space_Coefs_C1_KaHSCR_k_Donut_Space_Coefs_C1_rt_Array_Float_34_4:0.0372599996626377, KaHSCR_k_Donut_Space_Coefs_C1_KaHSCR_k_Donut_Space_Coefs_C1_rt_Array_Float_34_5:0.0378299988806248, KaHSCR_k_Donut_Space_Coefs_C1_KaHSCR_k_Donut_Space_Coefs_C1_rt_Array_Float_34_6:0.0382400006055832, KaHSCR_k_Donut_Space_Coefs_C1_KaHSCR_k_Donut_Space_Coefs_C1_rt_Array_Float_34_7:0.0386399887502193, KaHSCR_k_Donut_Space_Coefs_C1_KaHSCR_k_Donut_Space_Coefs_C1_rt_Array_Float_34_8:0.0405225306749344, KaHSCR_k_Donut_Space_Coefs_C1_KaHSCR_k_Donut_Space_Coefs_C1_rt_Array_Float_34_9:0.0411508604884148, KaHSCR_k_Donut_Space_Coefs_C1_KaHSCR_k_Donut_Space_Coefs_C1_rt_Array_Float_34_10:0.0418944396078587, KaHSCR_k_Donut_Space_Coefs_C1_KaHSCR_k_Donut_Space_Coefs_C1_rt_Array_Float_34_11:0.0425894781947136, KaHSCR_k_Donut_Space_Coefs_C1_KaHSCR_k_Donut_Space_Coefs_C1_rt_Array_Float_34_12:0.0431920886039734, KaHSCR_k_Donut_Space_Coefs_C1_KaHSCR_k_Donut_Space_Coefs_C1_rt_Array_Float_34_13:0.0436835289001465, KaHSCR_k_Donut_Space_Coefs_C1_KaHSCR_k_Donut_Space_Coefs_C1_rt_Array_Float_34_14:0.0443845391273499, KaHSCR_k_Donut_Space_Coefs_C1_KaHSCR_k_Donut_Space_Coefs_C1_rt_Array_Float_34_15:0.0450701601803303, KaHSCR_k_Donut_Space_Coefs_C1_KaHSCR_k_Donut_Space_Coefs_C1_rt_Array_Float_34_16:0.0456303507089615, KaHSCR_k_Donut_Space_Coefs_C1_KaHSCR_k_Donut_Space_Coefs_C1_rt_Array_Float_34_17:0.0466340184211731, KaHSCR_k_Donut_Space_Coefs_C1_KaHSCR_k_Donut_Space_Coefs_C1_rt_Array_Float_34_18:0.0474497117102146, KaHSCR_k_Donut_Space_Coefs_C1_KaHSCR_k_Donut_Space_Coefs_C1_rt_Array_Float_34_19:0.0479614101350307, KaHSCR_k_Donut_Space_Coefs_C1_KaHSCR_k_Donut_Space_Coefs_C1_rt_Array_Float_34_20:0.0484260395169258, KaHSCR_k_Donut_Space_Coefs_C1_KaHSCR_k_Donut_Space_Coefs_C1_rt_Array_Float_34_21:0.0488490909337997, KaHSCR_k_Donut_Space_Coefs_C1_KaHSCR_k_Donut_Space_Coefs_C1_rt_Array_Float_34_22:0.0494564808905125, KaHSCR_k_Donut_Space_Coefs_C1_KaHSCR_k_Donut_Space_Coefs_C1_rt_Array_Float_34_23:0.050324771553278, KaHSCR_k_Donut_Space_Coefs_C1_KaHSCR_k_Donut_Space_Coefs_C1_rt_Array_Float_34_24:0.0511159785091877, KaHSCR_k_Donut_Space_Coefs_C1_KaHSCR_k_Donut_Space_Coefs_C1_rt_Array_Float_34_25:0.0516291595995426, KaHSCR_k_Donut_Space_Coefs_C1_KaHSCR_k_Donut_Space_Coefs_C1_rt_Array_Float_34_26:0.051756490021944, KaHSCR_k_Donut_Space_Coefs_C1_KaHSCR_k_Donut_Space_Coefs_C1_rt_Array_Float_34_27:0.0519887804985046, KaHSCR_k_Donut_Space_Coefs_C1_KaHSCR_k_Donut_Space_Coefs_C1_rt_Array_Float_34_28:0.0530802011489868, KaHSCR_k_Donut_Space_Coefs_C1_KaHSCR_k_Donut_Space_Coefs_C1_rt_Array_Float_34_29:0.0536961182951927, KaHSCR_k_Donut_Space_Coefs_C1_KaHSCR_k_Donut_Space_Coefs_C1_rt_Array_Float_34_30:0.054239921271801, KaHSCR_k_Donut_Space_Coefs_C1_KaHSCR_k_Donut_Space_Coefs_C1_rt_Array_Float_34_31:0.0550949200987816, KaHSCR_k_Donut_Space_Coefs_C1_KaHSCR_k_Donut_Space_Coefs_C1_rt_Array_Float_34_32:0.0563113614916801, KaHSCR_k_Donut_Space_Coefs_C1_KaHSCR_k_Donut_Space_Coefs_C1_rt_Array_Float_34_33:0.0575419701635838, KaHSCR_k_Donut_Space_Coefs_C1_KaHSCR_k_Donut_Space_Coefs_C1_rt_Array_Float_34_34:0.0587838590145111], parameter=KaHSCR_k_Donut_Space_Coefs_C1}, required-interface=KaHSCR_k_Donut_Space_Coefs_C1
      KaHSCR_k_Donut_Space_Coefs_C2: parameter-require-com-spec{init-value=KaHSCR_k_Donut_Space_Coefs_C2_KaHSCR_k_Donut_Space_Coefs_C2:[KaHSCR_k_Donut_Space_Coefs_C2_KaHSCR_k_Donut_Space_Coefs_C2_rt_Array_Float_34_1:-5.04978709276475E-18, KaHSCR_k_Donut_Space_Coefs_C2_KaHSCR_k_Donut_Space_Coefs_C2_rt_Array_Float_34_2:-5.04978709276475E-18, KaHSCR_k_Donut_Space_Coefs_C2_KaHSCR_k_Donut_Space_Coefs_C2_rt_Array_Float_34_3:0.639999985694885, KaHSCR_k_Donut_Space_Coefs_C2_KaHSCR_k_Donut_Space_Coefs_C2_rt_Array_Float_34_4:1.19000005722046, KaHSCR_k_Donut_Space_Coefs_C2_KaHSCR_k_Donut_Space_Coefs_C2_rt_Array_Float_34_5:1.75999999046326, KaHSCR_k_Donut_Space_Coefs_C2_KaHSCR_k_Donut_Space_Coefs_C2_rt_Array_Float_34_6:2.30999994277954, KaHSCR_k_Donut_Space_Coefs_C2_KaHSCR_k_Donut_Space_Coefs_C2_rt_Array_Float_34_7:2.85999989509583, KaHSCR_k_Donut_Space_Coefs_C2_KaHSCR_k_Donut_Space_Coefs_C2_rt_Array_Float_34_8:3.33561706542969, KaHSCR_k_Donut_Space_Coefs_C2_KaHSCR_k_Donut_Space_Coefs_C2_rt_Array_Float_34_9:3.81586289405823, KaHSCR_k_Donut_Space_Coefs_C2_KaHSCR_k_Donut_Space_Coefs_C2_rt_Array_Float_34_10:4.27816390991211, KaHSCR_k_Donut_Space_Coefs_C2_KaHSCR_k_Donut_Space_Coefs_C2_rt_Array_Float_34_11:4.72691488265991, KaHSCR_k_Donut_Space_Coefs_C2_KaHSCR_k_Donut_Space_Coefs_C2_rt_Array_Float_34_12:5.16561794281006, KaHSCR_k_Donut_Space_Coefs_C2_KaHSCR_k_Donut_Space_Coefs_C2_rt_Array_Float_34_13:5.61427307128906, KaHSCR_k_Donut_Space_Coefs_C2_KaHSCR_k_Donut_Space_Coefs_C2_rt_Array_Float_34_14:6.01499605178833, KaHSCR_k_Donut_Space_Coefs_C2_KaHSCR_k_Donut_Space_Coefs_C2_rt_Array_Float_34_15:6.42061996459961, KaHSCR_k_Donut_Space_Coefs_C2_KaHSCR_k_Donut_Space_Coefs_C2_rt_Array_Float_34_16:6.81864976882935, KaHSCR_k_Donut_Space_Coefs_C2_KaHSCR_k_Donut_Space_Coefs_C2_rt_Array_Float_34_17:7.15260887145996, KaHSCR_k_Donut_Space_Coefs_C2_KaHSCR_k_Donut_Space_Coefs_C2_rt_Array_Float_34_18:7.50815296173096, KaHSCR_k_Donut_Space_Coefs_C2_KaHSCR_k_Donut_Space_Coefs_C2_rt_Array_Float_34_19:7.88588094711304, KaHSCR_k_Donut_Space_Coefs_C2_KaHSCR_k_Donut_Space_Coefs_C2_rt_Array_Float_34_20:8.26707172393799, KaHSCR_k_Donut_Space_Coefs_C2_KaHSCR_k_Donut_Space_Coefs_C2_rt_Array_Float_34_21:8.64353656768799, KaHSCR_k_Donut_Space_Coefs_C2_KaHSCR_k_Donut_Space_Coefs_C2_rt_Array_Float_34_22:8.99045372009277, KaHSCR_k_Donut_Space_Coefs_C2_KaHSCR_k_Donut_Space_Coefs_C2_rt_Array_Float_34_23:9.27973079681396, KaHSCR_k_Donut_Space_Coefs_C2_KaHSCR_k_Donut_Space_Coefs_C2_rt_Array_Float_34_24:9.56464672088623, KaHSCR_k_Donut_Space_Coefs_C2_KaHSCR_k_Donut_Space_Coefs_C2_rt_Array_Float_34_25:9.88457489013672, KaHSCR_k_Donut_Space_Coefs_C2_KaHSCR_k_Donut_Space_Coefs_C2_rt_Array_Float_34_26:10.2705402374268, KaHSCR_k_Donut_Space_Coefs_C2_KaHSCR_k_Donut_Space_Coefs_C2_rt_Array_Float_34_27:10.658860206604, KaHSCR_k_Donut_Space_Coefs_C2_KaHSCR_k_Donut_Space_Coefs_C2_rt_Array_Float_34_28:10.8600997924805, KaHSCR_k_Donut_Space_Coefs_C2_KaHSCR_k_Donut_Space_Coefs_C2_rt_Array_Float_34_29:11.1487503051758, KaHSCR_k_Donut_Space_Coefs_C2_KaHSCR_k_Donut_Space_Coefs_C2_rt_Array_Float_34_30:11.4441699981689, KaHSCR_k_Donut_Space_Coefs_C2_KaHSCR_k_Donut_Space_Coefs_C2_rt_Array_Float_34_31:11.6732902526855, KaHSCR_k_Donut_Space_Coefs_C2_KaHSCR_k_Donut_Space_Coefs_C2_rt_Array_Float_34_32:11.8130502700806, KaHSCR_k_Donut_Space_Coefs_C2_KaHSCR_k_Donut_Space_Coefs_C2_rt_Array_Float_34_33:11.9453201293945, KaHSCR_k_Donut_Space_Coefs_C2_KaHSCR_k_Donut_Space_Coefs_C2_rt_Array_Float_34_34:12.0616703033447], parameter=KaHSCR_k_Donut_Space_Coefs_C2}, required-interface=KaHSCR_k_Donut_Space_Coefs_C2
      KaHSCR_k_Donut_Space_Coefs_D: parameter-require-com-spec{init-value=KaHSCR_k_Donut_Space_Coefs_D_KaHSCR_k_Donut_Space_Coefs_D:[KaHSCR_k_Donut_Space_Coefs_D_KaHSCR_k_Donut_Space_Coefs_D_rt_Array_Float_34_1:0.103308998048306, KaHSCR_k_Donut_Space_Coefs_D_KaHSCR_k_Donut_Space_Coefs_D_rt_Array_Float_34_2:0.103308998048306, KaHSCR_k_Donut_Space_Coefs_D_KaHSCR_k_Donut_Space_Coefs_D_rt_Array_Float_34_3:-0.211907997727394, KaHSCR_k_Donut_Space_Coefs_D_KaHSCR_k_Donut_Space_Coefs_D_rt_Array_Float_34_4:-1.20062398910522, KaHSCR_k_Donut_Space_Coefs_D_KaHSCR_k_Donut_Space_Coefs_D_rt_Array_Float_34_5:-2.85137605667114, KaHSCR_k_Donut_Space_Coefs_D_KaHSCR_k_Donut_Space_Coefs_D_rt_Array_Float_34_6:-5.10159778594971, KaHSCR_k_Donut_Space_Coefs_D_KaHSCR_k_Donut_Space_Coefs_D_rt_Array_Float_34_7:-7.90723323822021, KaHSCR_k_Donut_Space_Coefs_D_KaHSCR_k_Donut_Space_Coefs_D_rt_Array_Float_34_8:-10.5811996459961, KaHSCR_k_Donut_Space_Coefs_D_KaHSCR_k_Donut_Space_Coefs_D_rt_Array_Float_34_9:-14.0026197433472, KaHSCR_k_Donut_Space_Coefs_D_KaHSCR_k_Donut_Space_Coefs_D_rt_Array_Float_34_10:-17.6751308441162, KaHSCR_k_Donut_Space_Coefs_D_KaHSCR_k_Donut_Space_Coefs_D_rt_Array_Float_34_11:-21.6737899780273, KaHSCR_k_Donut_Space_Coefs_D_KaHSCR_k_Donut_Space_Coefs_D_rt_Array_Float_34_12:-26.0248203277588, KaHSCR_k_Donut_Space_Coefs_D_KaHSCR_k_Donut_Space_Coefs_D_rt_Array_Float_34_13:-30.7496299743652, KaHSCR_k_Donut_Space_Coefs_D_KaHSCR_k_Donut_Space_Coefs_D_rt_Array_Float_34_14:-35.452018737793, KaHSCR_k_Donut_Space_Coefs_D_KaHSCR_k_Donut_Space_Coefs_D_rt_Array_Float_34_15:-40.3361701965332, KaHSCR_k_Donut_Space_Coefs_D_KaHSCR_k_Donut_Space_Coefs_D_rt_Array_Float_34_16:-45.6424903869629, KaHSCR_k_Donut_Space_Coefs_D_KaHSCR_k_Donut_Space_Coefs_D_rt_Array_Float_34_17:-50.2698593139648, KaHSCR_k_Donut_Space_Coefs_D_KaHSCR_k_Donut_Space_Coefs_D_rt_Array_Float_34_18:-55.375659942627, KaHSCR_k_Donut_Space_Coefs_D_KaHSCR_k_Donut_Space_Coefs_D_rt_Array_Float_34_19:-61.2313995361328, KaHSCR_k_Donut_Space_Coefs_D_KaHSCR_k_Donut_Space_Coefs_D_rt_Array_Float_34_20:-67.2626876831055, KaHSCR_k_Donut_Space_Coefs_D_KaHSCR_k_Donut_Space_Coefs_D_rt_Array_Float_34_21:-73.5646362304688, KaHSCR_k_Donut_Space_Coefs_D_KaHSCR_k_Donut_Space_Coefs_D_rt_Array_Float_34_22:-79.621467590332, KaHSCR_k_Donut_Space_Coefs_D_KaHSCR_k_Donut_Space_Coefs_D_rt_Array_Float_34_23:-84.9908294677734, KaHSCR_k_Donut_Space_Coefs_D_KaHSCR_k_Donut_Space_Coefs_D_rt_Array_Float_34_24:-90.269172668457, KaHSCR_k_Donut_Space_Coefs_D_KaHSCR_k_Donut_Space_Coefs_D_rt_Array_Float_34_25:-96.3239364624023, KaHSCR_k_Donut_Space_Coefs_D_KaHSCR_k_Donut_Space_Coefs_D_rt_Array_Float_34_26:-104.145500183105, KaHSCR_k_Donut_Space_Coefs_D_KaHSCR_k_Donut_Space_Coefs_D_rt_Array_Float_34_27:-112.130699157715, KaHSCR_k_Donut_Space_Coefs_D_KaHSCR_k_Donut_Space_Coefs_D_rt_Array_Float_34_28:-116.38639831543, KaHSCR_k_Donut_Space_Coefs_D_KaHSCR_k_Donut_Space_Coefs_D_rt_Array_Float_34_29:-122.710998535156, KaHSCR_k_Donut_Space_Coefs_D_KaHSCR_k_Donut_Space_Coefs_D_rt_Array_Float_34_30:-129.441192626953, KaHSCR_k_Donut_Space_Coefs_D_KaHSCR_k_Donut_Space_Coefs_D_rt_Array_Float_34_31:-134.5126953125, KaHSCR_k_Donut_Space_Coefs_D_KaHSCR_k_Donut_Space_Coefs_D_rt_Array_Float_34_32:-137.768402099609, KaHSCR_k_Donut_Space_Coefs_D_KaHSCR_k_Donut_Space_Coefs_D_rt_Array_Float_34_33:-140.760498046875, KaHSCR_k_Donut_Space_Coefs_D_KaHSCR_k_Donut_Space_Coefs_D_rt_Array_Float_34_34:-143.608093261719], parameter=KaHSCR_k_Donut_Space_Coefs_D}, required-interface=KaHSCR_k_Donut_Space_Coefs_D
      KaHSCR_k_Donut_Space_Coefs_E: parameter-require-com-spec{init-value=KaHSCR_k_Donut_Space_Coefs_E_KaHSCR_k_Donut_Space_Coefs_E:[KaHSCR_k_Donut_Space_Coefs_E_KaHSCR_k_Donut_Space_Coefs_E_rt_Array_Float_34_1:0.103308998048306, KaHSCR_k_Donut_Space_Coefs_E_KaHSCR_k_Donut_Space_Coefs_E_rt_Array_Float_34_2:0.103308998048306, KaHSCR_k_Donut_Space_Coefs_E_KaHSCR_k_Donut_Space_Coefs_E_rt_Array_Float_34_3:-0.211907997727394, KaHSCR_k_Donut_Space_Coefs_E_KaHSCR_k_Donut_Space_Coefs_E_rt_Array_Float_34_4:-1.20062398910522, KaHSCR_k_Donut_Space_Coefs_E_KaHSCR_k_Donut_Space_Coefs_E_rt_Array_Float_34_5:-2.85137605667114, KaHSCR_k_Donut_Space_Coefs_E_KaHSCR_k_Donut_Space_Coefs_E_rt_Array_Float_34_6:-5.10159778594971, KaHSCR_k_Donut_Space_Coefs_E_KaHSCR_k_Donut_Space_Coefs_E_rt_Array_Float_34_7:-7.90723323822021, KaHSCR_k_Donut_Space_Coefs_E_KaHSCR_k_Donut_Space_Coefs_E_rt_Array_Float_34_8:-10.5811996459961, KaHSCR_k_Donut_Space_Coefs_E_KaHSCR_k_Donut_Space_Coefs_E_rt_Array_Float_34_9:-14.0026197433472, KaHSCR_k_Donut_Space_Coefs_E_KaHSCR_k_Donut_Space_Coefs_E_rt_Array_Float_34_10:-17.6751308441162, KaHSCR_k_Donut_Space_Coefs_E_KaHSCR_k_Donut_Space_Coefs_E_rt_Array_Float_34_11:-21.6737899780273, KaHSCR_k_Donut_Space_Coefs_E_KaHSCR_k_Donut_Space_Coefs_E_rt_Array_Float_34_12:-26.0248203277588, KaHSCR_k_Donut_Space_Coefs_E_KaHSCR_k_Donut_Space_Coefs_E_rt_Array_Float_34_13:-30.7496299743652, KaHSCR_k_Donut_Space_Coefs_E_KaHSCR_k_Donut_Space_Coefs_E_rt_Array_Float_34_14:-35.452018737793, KaHSCR_k_Donut_Space_Coefs_E_KaHSCR_k_Donut_Space_Coefs_E_rt_Array_Float_34_15:-40.3361701965332, KaHSCR_k_Donut_Space_Coefs_E_KaHSCR_k_Donut_Space_Coefs_E_rt_Array_Float_34_16:-45.6424903869629, KaHSCR_k_Donut_Space_Coefs_E_KaHSCR_k_Donut_Space_Coefs_E_rt_Array_Float_34_17:-50.2698593139648, KaHSCR_k_Donut_Space_Coefs_E_KaHSCR_k_Donut_Space_Coefs_E_rt_Array_Float_34_18:-55.375659942627, KaHSCR_k_Donut_Space_Coefs_E_KaHSCR_k_Donut_Space_Coefs_E_rt_Array_Float_34_19:-61.2313995361328, KaHSCR_k_Donut_Space_Coefs_E_KaHSCR_k_Donut_Space_Coefs_E_rt_Array_Float_34_20:-67.2626876831055, KaHSCR_k_Donut_Space_Coefs_E_KaHSCR_k_Donut_Space_Coefs_E_rt_Array_Float_34_21:-73.5646362304688, KaHSCR_k_Donut_Space_Coefs_E_KaHSCR_k_Donut_Space_Coefs_E_rt_Array_Float_34_22:-79.621467590332, KaHSCR_k_Donut_Space_Coefs_E_KaHSCR_k_Donut_Space_Coefs_E_rt_Array_Float_34_23:-84.9908294677734, KaHSCR_k_Donut_Space_Coefs_E_KaHSCR_k_Donut_Space_Coefs_E_rt_Array_Float_34_24:-90.269172668457, KaHSCR_k_Donut_Space_Coefs_E_KaHSCR_k_Donut_Space_Coefs_E_rt_Array_Float_34_25:-96.3239364624023, KaHSCR_k_Donut_Space_Coefs_E_KaHSCR_k_Donut_Space_Coefs_E_rt_Array_Float_34_26:-104.145500183105, KaHSCR_k_Donut_Space_Coefs_E_KaHSCR_k_Donut_Space_Coefs_E_rt_Array_Float_34_27:-112.130699157715, KaHSCR_k_Donut_Space_Coefs_E_KaHSCR_k_Donut_Space_Coefs_E_rt_Array_Float_34_28:-116.38639831543, KaHSCR_k_Donut_Space_Coefs_E_KaHSCR_k_Donut_Space_Coefs_E_rt_Array_Float_34_29:-122.710998535156, KaHSCR_k_Donut_Space_Coefs_E_KaHSCR_k_Donut_Space_Coefs_E_rt_Array_Float_34_30:-129.441192626953, KaHSCR_k_Donut_Space_Coefs_E_KaHSCR_k_Donut_Space_Coefs_E_rt_Array_Float_34_31:-134.5126953125, KaHSCR_k_Donut_Space_Coefs_E_KaHSCR_k_Donut_Space_Coefs_E_rt_Array_Float_34_32:-137.768402099609, KaHSCR_k_Donut_Space_Coefs_E_KaHSCR_k_Donut_Space_Coefs_E_rt_Array_Float_34_33:-140.760498046875, KaHSCR_k_Donut_Space_Coefs_E_KaHSCR_k_Donut_Space_Coefs_E_rt_Array_Float_34_34:-143.608093261719], parameter=KaHSCR_k_Donut_Space_Coefs_E}, required-interface=KaHSCR_k_Donut_Space_Coefs_E
      KaHSCR_n_DonutSpaceCoeffs_AxisA: parameter-require-com-spec{init-value=KaHSCR_n_DonutSpaceCoeffs_AxisA_KaHSCR_n_DonutSpaceCoeffs_AxisA:[KaHSCR_n_DonutSpaceCoeffs_AxisA_KaHSCR_n_DonutSpaceCoeffs_AxisA_rt_Array_Float_34_1:0.00100000004749745, KaHSCR_n_DonutSpaceCoeffs_AxisA_KaHSCR_n_DonutSpaceCoeffs_AxisA_rt_Array_Float_34_2:100, KaHSCR_n_DonutSpaceCoeffs_AxisA_KaHSCR_n_DonutSpaceCoeffs_AxisA_rt_Array_Float_34_3:250, KaHSCR_n_DonutSpaceCoeffs_AxisA_KaHSCR_n_DonutSpaceCoeffs_AxisA_rt_Array_Float_34_4:500, KaHSCR_n_DonutSpaceCoeffs_AxisA_KaHSCR_n_DonutSpaceCoeffs_AxisA_rt_Array_Float_34_5:750, KaHSCR_n_DonutSpaceCoeffs_AxisA_KaHSCR_n_DonutSpaceCoeffs_AxisA_rt_Array_Float_34_6:1000, KaHSCR_n_DonutSpaceCoeffs_AxisA_KaHSCR_n_DonutSpaceCoeffs_AxisA_rt_Array_Float_34_7:1250, KaHSCR_n_DonutSpaceCoeffs_AxisA_KaHSCR_n_DonutSpaceCoeffs_AxisA_rt_Array_Float_34_8:1500, KaHSCR_n_DonutSpaceCoeffs_AxisA_KaHSCR_n_DonutSpaceCoeffs_AxisA_rt_Array_Float_34_9:1750, KaHSCR_n_DonutSpaceCoeffs_AxisA_KaHSCR_n_DonutSpaceCoeffs_AxisA_rt_Array_Float_34_10:2000, KaHSCR_n_DonutSpaceCoeffs_AxisA_KaHSCR_n_DonutSpaceCoeffs_AxisA_rt_Array_Float_34_11:2250, KaHSCR_n_DonutSpaceCoeffs_AxisA_KaHSCR_n_DonutSpaceCoeffs_AxisA_rt_Array_Float_34_12:2500, KaHSCR_n_DonutSpaceCoeffs_AxisA_KaHSCR_n_DonutSpaceCoeffs_AxisA_rt_Array_Float_34_13:2750, KaHSCR_n_DonutSpaceCoeffs_AxisA_KaHSCR_n_DonutSpaceCoeffs_AxisA_rt_Array_Float_34_14:3000, KaHSCR_n_DonutSpaceCoeffs_AxisA_KaHSCR_n_DonutSpaceCoeffs_AxisA_rt_Array_Float_34_15:3250, KaHSCR_n_DonutSpaceCoeffs_AxisA_KaHSCR_n_DonutSpaceCoeffs_AxisA_rt_Array_Float_34_16:3500, KaHSCR_n_DonutSpaceCoeffs_AxisA_KaHSCR_n_DonutSpaceCoeffs_AxisA_rt_Array_Float_34_17:3750, KaHSCR_n_DonutSpaceCoeffs_AxisA_KaHSCR_n_DonutSpaceCoeffs_AxisA_rt_Array_Float_34_18:4000, KaHSCR_n_DonutSpaceCoeffs_AxisA_KaHSCR_n_DonutSpaceCoeffs_AxisA_rt_Array_Float_34_19:4250, KaHSCR_n_DonutSpaceCoeffs_AxisA_KaHSCR_n_DonutSpaceCoeffs_AxisA_rt_Array_Float_34_20:4500, KaHSCR_n_DonutSpaceCoeffs_AxisA_KaHSCR_n_DonutSpaceCoeffs_AxisA_rt_Array_Float_34_21:4750, KaHSCR_n_DonutSpaceCoeffs_AxisA_KaHSCR_n_DonutSpaceCoeffs_AxisA_rt_Array_Float_34_22:5000, KaHSCR_n_DonutSpaceCoeffs_AxisA_KaHSCR_n_DonutSpaceCoeffs_AxisA_rt_Array_Float_34_23:5250, KaHSCR_n_DonutSpaceCoeffs_AxisA_KaHSCR_n_DonutSpaceCoeffs_AxisA_rt_Array_Float_34_24:5500, KaHSCR_n_DonutSpaceCoeffs_AxisA_KaHSCR_n_DonutSpaceCoeffs_AxisA_rt_Array_Float_34_25:5750, KaHSCR_n_DonutSpaceCoeffs_AxisA_KaHSCR_n_DonutSpaceCoeffs_AxisA_rt_Array_Float_34_26:6000, KaHSCR_n_DonutSpaceCoeffs_AxisA_KaHSCR_n_DonutSpaceCoeffs_AxisA_rt_Array_Float_34_27:6250, KaHSCR_n_DonutSpaceCoeffs_AxisA_KaHSCR_n_DonutSpaceCoeffs_AxisA_rt_Array_Float_34_28:6500, KaHSCR_n_DonutSpaceCoeffs_AxisA_KaHSCR_n_DonutSpaceCoeffs_AxisA_rt_Array_Float_34_29:7000, KaHSCR_n_DonutSpaceCoeffs_AxisA_KaHSCR_n_DonutSpaceCoeffs_AxisA_rt_Array_Float_34_30:7500, KaHSCR_n_DonutSpaceCoeffs_AxisA_KaHSCR_n_DonutSpaceCoeffs_AxisA_rt_Array_Float_34_31:8000, KaHSCR_n_DonutSpaceCoeffs_AxisA_KaHSCR_n_DonutSpaceCoeffs_AxisA_rt_Array_Float_34_32:8500, KaHSCR_n_DonutSpaceCoeffs_AxisA_KaHSCR_n_DonutSpaceCoeffs_AxisA_rt_Array_Float_34_33:9000, KaHSCR_n_DonutSpaceCoeffs_AxisA_KaHSCR_n_DonutSpaceCoeffs_AxisA_rt_Array_Float_34_34:10500], parameter=KaHSCR_n_DonutSpaceCoeffs_AxisA}, required-interface=KaHSCR_n_DonutSpaceCoeffs_AxisA
      KaHSCR_n_DonutSpaceCoeffs_AxisB: parameter-require-com-spec{init-value=KaHSCR_n_DonutSpaceCoeffs_AxisB_KaHSCR_n_DonutSpaceCoeffs_AxisB:[KaHSCR_n_DonutSpaceCoeffs_AxisB_KaHSCR_n_DonutSpaceCoeffs_AxisB_rt_Array_Float_34_1:0.00100000004749745, KaHSCR_n_DonutSpaceCoeffs_AxisB_KaHSCR_n_DonutSpaceCoeffs_AxisB_rt_Array_Float_34_2:100, KaHSCR_n_DonutSpaceCoeffs_AxisB_KaHSCR_n_DonutSpaceCoeffs_AxisB_rt_Array_Float_34_3:250, KaHSCR_n_DonutSpaceCoeffs_AxisB_KaHSCR_n_DonutSpaceCoeffs_AxisB_rt_Array_Float_34_4:500, KaHSCR_n_DonutSpaceCoeffs_AxisB_KaHSCR_n_DonutSpaceCoeffs_AxisB_rt_Array_Float_34_5:750, KaHSCR_n_DonutSpaceCoeffs_AxisB_KaHSCR_n_DonutSpaceCoeffs_AxisB_rt_Array_Float_34_6:1000, KaHSCR_n_DonutSpaceCoeffs_AxisB_KaHSCR_n_DonutSpaceCoeffs_AxisB_rt_Array_Float_34_7:1250, KaHSCR_n_DonutSpaceCoeffs_AxisB_KaHSCR_n_DonutSpaceCoeffs_AxisB_rt_Array_Float_34_8:1500, KaHSCR_n_DonutSpaceCoeffs_AxisB_KaHSCR_n_DonutSpaceCoeffs_AxisB_rt_Array_Float_34_9:1750, KaHSCR_n_DonutSpaceCoeffs_AxisB_KaHSCR_n_DonutSpaceCoeffs_AxisB_rt_Array_Float_34_10:2000, KaHSCR_n_DonutSpaceCoeffs_AxisB_KaHSCR_n_DonutSpaceCoeffs_AxisB_rt_Array_Float_34_11:2250, KaHSCR_n_DonutSpaceCoeffs_AxisB_KaHSCR_n_DonutSpaceCoeffs_AxisB_rt_Array_Float_34_12:2500, KaHSCR_n_DonutSpaceCoeffs_AxisB_KaHSCR_n_DonutSpaceCoeffs_AxisB_rt_Array_Float_34_13:2750, KaHSCR_n_DonutSpaceCoeffs_AxisB_KaHSCR_n_DonutSpaceCoeffs_AxisB_rt_Array_Float_34_14:3000, KaHSCR_n_DonutSpaceCoeffs_AxisB_KaHSCR_n_DonutSpaceCoeffs_AxisB_rt_Array_Float_34_15:3250, KaHSCR_n_DonutSpaceCoeffs_AxisB_KaHSCR_n_DonutSpaceCoeffs_AxisB_rt_Array_Float_34_16:3500, KaHSCR_n_DonutSpaceCoeffs_AxisB_KaHSCR_n_DonutSpaceCoeffs_AxisB_rt_Array_Float_34_17:3750, KaHSCR_n_DonutSpaceCoeffs_AxisB_KaHSCR_n_DonutSpaceCoeffs_AxisB_rt_Array_Float_34_18:4000, KaHSCR_n_DonutSpaceCoeffs_AxisB_KaHSCR_n_DonutSpaceCoeffs_AxisB_rt_Array_Float_34_19:4250, KaHSCR_n_DonutSpaceCoeffs_AxisB_KaHSCR_n_DonutSpaceCoeffs_AxisB_rt_Array_Float_34_20:4500, KaHSCR_n_DonutSpaceCoeffs_AxisB_KaHSCR_n_DonutSpaceCoeffs_AxisB_rt_Array_Float_34_21:4750, KaHSCR_n_DonutSpaceCoeffs_AxisB_KaHSCR_n_DonutSpaceCoeffs_AxisB_rt_Array_Float_34_22:5000, KaHSCR_n_DonutSpaceCoeffs_AxisB_KaHSCR_n_DonutSpaceCoeffs_AxisB_rt_Array_Float_34_23:5250, KaHSCR_n_DonutSpaceCoeffs_AxisB_KaHSCR_n_DonutSpaceCoeffs_AxisB_rt_Array_Float_34_24:5500, KaHSCR_n_DonutSpaceCoeffs_AxisB_KaHSCR_n_DonutSpaceCoeffs_AxisB_rt_Array_Float_34_25:5750, KaHSCR_n_DonutSpaceCoeffs_AxisB_KaHSCR_n_DonutSpaceCoeffs_AxisB_rt_Array_Float_34_26:6000, KaHSCR_n_DonutSpaceCoeffs_AxisB_KaHSCR_n_DonutSpaceCoeffs_AxisB_rt_Array_Float_34_27:6250, KaHSCR_n_DonutSpaceCoeffs_AxisB_KaHSCR_n_DonutSpaceCoeffs_AxisB_rt_Array_Float_34_28:6500, KaHSCR_n_DonutSpaceCoeffs_AxisB_KaHSCR_n_DonutSpaceCoeffs_AxisB_rt_Array_Float_34_29:7000, KaHSCR_n_DonutSpaceCoeffs_AxisB_KaHSCR_n_DonutSpaceCoeffs_AxisB_rt_Array_Float_34_30:7500, KaHSCR_n_DonutSpaceCoeffs_AxisB_KaHSCR_n_DonutSpaceCoeffs_AxisB_rt_Array_Float_34_31:8000, KaHSCR_n_DonutSpaceCoeffs_AxisB_KaHSCR_n_DonutSpaceCoeffs_AxisB_rt_Array_Float_34_32:8500, KaHSCR_n_DonutSpaceCoeffs_AxisB_KaHSCR_n_DonutSpaceCoeffs_AxisB_rt_Array_Float_34_33:9000, KaHSCR_n_DonutSpaceCoeffs_AxisB_KaHSCR_n_DonutSpaceCoeffs_AxisB_rt_Array_Float_34_34:10500], parameter=KaHSCR_n_DonutSpaceCoeffs_AxisB}, required-interface=KaHSCR_n_DonutSpaceCoeffs_AxisB
      KaHSCR_n_DonutSpaceCoeffs_AxisC: parameter-require-com-spec{init-value=KaHSCR_n_DonutSpaceCoeffs_AxisC_KaHSCR_n_DonutSpaceCoeffs_AxisC:[KaHSCR_n_DonutSpaceCoeffs_AxisC_KaHSCR_n_DonutSpaceCoeffs_AxisC_rt_Array_Float_34_1:0.00100000004749745, KaHSCR_n_DonutSpaceCoeffs_AxisC_KaHSCR_n_DonutSpaceCoeffs_AxisC_rt_Array_Float_34_2:100, KaHSCR_n_DonutSpaceCoeffs_AxisC_KaHSCR_n_DonutSpaceCoeffs_AxisC_rt_Array_Float_34_3:250, KaHSCR_n_DonutSpaceCoeffs_AxisC_KaHSCR_n_DonutSpaceCoeffs_AxisC_rt_Array_Float_34_4:500, KaHSCR_n_DonutSpaceCoeffs_AxisC_KaHSCR_n_DonutSpaceCoeffs_AxisC_rt_Array_Float_34_5:750, KaHSCR_n_DonutSpaceCoeffs_AxisC_KaHSCR_n_DonutSpaceCoeffs_AxisC_rt_Array_Float_34_6:1000, KaHSCR_n_DonutSpaceCoeffs_AxisC_KaHSCR_n_DonutSpaceCoeffs_AxisC_rt_Array_Float_34_7:1250, KaHSCR_n_DonutSpaceCoeffs_AxisC_KaHSCR_n_DonutSpaceCoeffs_AxisC_rt_Array_Float_34_8:1500, KaHSCR_n_DonutSpaceCoeffs_AxisC_KaHSCR_n_DonutSpaceCoeffs_AxisC_rt_Array_Float_34_9:1750, KaHSCR_n_DonutSpaceCoeffs_AxisC_KaHSCR_n_DonutSpaceCoeffs_AxisC_rt_Array_Float_34_10:2000, KaHSCR_n_DonutSpaceCoeffs_AxisC_KaHSCR_n_DonutSpaceCoeffs_AxisC_rt_Array_Float_34_11:2250, KaHSCR_n_DonutSpaceCoeffs_AxisC_KaHSCR_n_DonutSpaceCoeffs_AxisC_rt_Array_Float_34_12:2500, KaHSCR_n_DonutSpaceCoeffs_AxisC_KaHSCR_n_DonutSpaceCoeffs_AxisC_rt_Array_Float_34_13:2750, KaHSCR_n_DonutSpaceCoeffs_AxisC_KaHSCR_n_DonutSpaceCoeffs_AxisC_rt_Array_Float_34_14:3000, KaHSCR_n_DonutSpaceCoeffs_AxisC_KaHSCR_n_DonutSpaceCoeffs_AxisC_rt_Array_Float_34_15:3250, KaHSCR_n_DonutSpaceCoeffs_AxisC_KaHSCR_n_DonutSpaceCoeffs_AxisC_rt_Array_Float_34_16:3500, KaHSCR_n_DonutSpaceCoeffs_AxisC_KaHSCR_n_DonutSpaceCoeffs_AxisC_rt_Array_Float_34_17:3750, KaHSCR_n_DonutSpaceCoeffs_AxisC_KaHSCR_n_DonutSpaceCoeffs_AxisC_rt_Array_Float_34_18:4000, KaHSCR_n_DonutSpaceCoeffs_AxisC_KaHSCR_n_DonutSpaceCoeffs_AxisC_rt_Array_Float_34_19:4250, KaHSCR_n_DonutSpaceCoeffs_AxisC_KaHSCR_n_DonutSpaceCoeffs_AxisC_rt_Array_Float_34_20:4500, KaHSCR_n_DonutSpaceCoeffs_AxisC_KaHSCR_n_DonutSpaceCoeffs_AxisC_rt_Array_Float_34_21:4750, KaHSCR_n_DonutSpaceCoeffs_AxisC_KaHSCR_n_DonutSpaceCoeffs_AxisC_rt_Array_Float_34_22:5000, KaHSCR_n_DonutSpaceCoeffs_AxisC_KaHSCR_n_DonutSpaceCoeffs_AxisC_rt_Array_Float_34_23:5250, KaHSCR_n_DonutSpaceCoeffs_AxisC_KaHSCR_n_DonutSpaceCoeffs_AxisC_rt_Array_Float_34_24:5500, KaHSCR_n_DonutSpaceCoeffs_AxisC_KaHSCR_n_DonutSpaceCoeffs_AxisC_rt_Array_Float_34_25:5750, KaHSCR_n_DonutSpaceCoeffs_AxisC_KaHSCR_n_DonutSpaceCoeffs_AxisC_rt_Array_Float_34_26:6000, KaHSCR_n_DonutSpaceCoeffs_AxisC_KaHSCR_n_DonutSpaceCoeffs_AxisC_rt_Array_Float_34_27:6250, KaHSCR_n_DonutSpaceCoeffs_AxisC_KaHSCR_n_DonutSpaceCoeffs_AxisC_rt_Array_Float_34_28:6500, KaHSCR_n_DonutSpaceCoeffs_AxisC_KaHSCR_n_DonutSpaceCoeffs_AxisC_rt_Array_Float_34_29:7000, KaHSCR_n_DonutSpaceCoeffs_AxisC_KaHSCR_n_DonutSpaceCoeffs_AxisC_rt_Array_Float_34_30:7500, KaHSCR_n_DonutSpaceCoeffs_AxisC_KaHSCR_n_DonutSpaceCoeffs_AxisC_rt_Array_Float_34_31:8000, KaHSCR_n_DonutSpaceCoeffs_AxisC_KaHSCR_n_DonutSpaceCoeffs_AxisC_rt_Array_Float_34_32:8500, KaHSCR_n_DonutSpaceCoeffs_AxisC_KaHSCR_n_DonutSpaceCoeffs_AxisC_rt_Array_Float_34_33:9000, KaHSCR_n_DonutSpaceCoeffs_AxisC_KaHSCR_n_DonutSpaceCoeffs_AxisC_rt_Array_Float_34_34:10500], parameter=KaHSCR_n_DonutSpaceCoeffs_AxisC}, required-interface=KaHSCR_n_DonutSpaceCoeffs_AxisC
      KaTSXR_r_EVM_CalcStrtgcTlfEqn: parameter-require-com-spec{init-value=KaTSXR_r_EVM_CalcStrtgcTlfEqn_KaTSXR_r_EVM_CalcStrtgcTlfEqn:[KaTSXR_r_EVM_CalcStrtgcTlfEqn_KaTSXR_r_EVM_CalcStrtgcTlfEqn_rt_Array_Float_126_1:0, KaTSXR_r_EVM_CalcStrtgcTlfEqn_KaTSXR_r_EVM_CalcStrtgcTlfEqn_rt_Array_Float_126_2:0, KaTSXR_r_EVM_CalcStrtgcTlfEqn_KaTSXR_r_EVM_CalcStrtgcTlfEqn_rt_Array_Float_126_3:0, KaTSXR_r_EVM_CalcStrtgcTlfEqn_KaTSXR_r_EVM_CalcStrtgcTlfEqn_rt_Array_Float_126_4:0, KaTSXR_r_EVM_CalcStrtgcTlfEqn_KaTSXR_r_EVM_CalcStrtgcTlfEqn_rt_Array_Float_126_5:0, KaTSXR_r_EVM_CalcStrtgcTlfEqn_KaTSXR_r_EVM_CalcStrtgcTlfEqn_rt_Array_Float_126_6:0, KaTSXR_r_EVM_CalcStrtgcTlfEqn_KaTSXR_r_EVM_CalcStrtgcTlfEqn_rt_Array_Float_126_7:0, KaTSXR_r_EVM_CalcStrtgcTlfEqn_KaTSXR_r_EVM_CalcStrtgcTlfEqn_rt_Array_Float_126_8:0, KaTSXR_r_EVM_CalcStrtgcTlfEqn_KaTSXR_r_EVM_CalcStrtgcTlfEqn_rt_Array_Float_126_9:0, KaTSXR_r_EVM_CalcStrtgcTlfEqn_KaTSXR_r_EVM_CalcStrtgcTlfEqn_rt_Array_Float_126_10:0, KaTSXR_r_EVM_CalcStrtgcTlfEqn_KaTSXR_r_EVM_CalcStrtgcTlfEqn_rt_Array_Float_126_11:0, KaTSXR_r_EVM_CalcStrtgcTlfEqn_KaTSXR_r_EVM_CalcStrtgcTlfEqn_rt_Array_Float_126_12:0, KaTSXR_r_EVM_CalcStrtgcTlfEqn_KaTSXR_r_EVM_CalcStrtgcTlfEqn_rt_Array_Float_126_13:0, KaTSXR_r_EVM_CalcStrtgcTlfEqn_KaTSXR_r_EVM_CalcStrtgcTlfEqn_rt_Array_Float_126_14:0, KaTSXR_r_EVM_CalcStrtgcTlfEqn_KaTSXR_r_EVM_CalcStrtgcTlfEqn_rt_Array_Float_126_15:0, KaTSXR_r_EVM_CalcStrtgcTlfEqn_KaTSXR_r_EVM_CalcStrtgcTlfEqn_rt_Array_Float_126_16:0, KaTSXR_r_EVM_CalcStrtgcTlfEqn_KaTSXR_r_EVM_CalcStrtgcTlfEqn_rt_Array_Float_126_17:0, KaTSXR_r_EVM_CalcStrtgcTlfEqn_KaTSXR_r_EVM_CalcStrtgcTlfEqn_rt_Array_Float_126_18:0, KaTSXR_r_EVM_CalcStrtgcTlfEqn_KaTSXR_r_EVM_CalcStrtgcTlfEqn_rt_Array_Float_126_19:0, KaTSXR_r_EVM_CalcStrtgcTlfEqn_KaTSXR_r_EVM_CalcStrtgcTlfEqn_rt_Array_Float_126_20:0, KaTSXR_r_EVM_CalcStrtgcTlfEqn_KaTSXR_r_EVM_CalcStrtgcTlfEqn_rt_Array_Float_126_21:0, KaTSXR_r_EVM_CalcStrtgcTlfEqn_KaTSXR_r_EVM_CalcStrtgcTlfEqn_rt_Array_Float_126_22:0, KaTSXR_r_EVM_CalcStrtgcTlfEqn_KaTSXR_r_EVM_CalcStrtgcTlfEqn_rt_Array_Float_126_23:0, KaTSXR_r_EVM_CalcStrtgcTlfEqn_KaTSXR_r_EVM_CalcStrtgcTlfEqn_rt_Array_Float_126_24:0, KaTSXR_r_EVM_CalcStrtgcTlfEqn_KaTSXR_r_EVM_CalcStrtgcTlfEqn_rt_Array_Float_126_25:0, KaTSXR_r_EVM_CalcStrtgcTlfEqn_KaTSXR_r_EVM_CalcStrtgcTlfEqn_rt_Array_Float_126_26:0, KaTSXR_r_EVM_CalcStrtgcTlfEqn_KaTSXR_r_EVM_CalcStrtgcTlfEqn_rt_Array_Float_126_27:0, KaTSXR_r_EVM_CalcStrtgcTlfEqn_KaTSXR_r_EVM_CalcStrtgcTlfEqn_rt_Array_Float_126_28:0, KaTSXR_r_EVM_CalcStrtgcTlfEqn_KaTSXR_r_EVM_CalcStrtgcTlfEqn_rt_Array_Float_126_29:0, KaTSXR_r_EVM_CalcStrtgcTlfEqn_KaTSXR_r_EVM_CalcStrtgcTlfEqn_rt_Array_Float_126_30:0, KaTSXR_r_EVM_CalcStrtgcTlfEqn_KaTSXR_r_EVM_CalcStrtgcTlfEqn_rt_Array_Float_126_31:0, KaTSXR_r_EVM_CalcStrtgcTlfEqn_KaTSXR_r_EVM_CalcStrtgcTlfEqn_rt_Array_Float_126_32:0, KaTSXR_r_EVM_CalcStrtgcTlfEqn_KaTSXR_r_EVM_CalcStrtgcTlfEqn_rt_Array_Float_126_33:0, KaTSXR_r_EVM_CalcStrtgcTlfEqn_KaTSXR_r_EVM_CalcStrtgcTlfEqn_rt_Array_Float_126_34:0, KaTSXR_r_EVM_CalcStrtgcTlfEqn_KaTSXR_r_EVM_CalcStrtgcTlfEqn_rt_Array_Float_126_35:0, KaTSXR_r_EVM_CalcStrtgcTlfEqn_KaTSXR_r_EVM_CalcStrtgcTlfEqn_rt_Array_Float_126_36:0, KaTSXR_r_EVM_CalcStrtgcTlfEqn_KaTSXR_r_EVM_CalcStrtgcTlfEqn_rt_Array_Float_126_37:0, KaTSXR_r_EVM_CalcStrtgcTlfEqn_KaTSXR_r_EVM_CalcStrtgcTlfEqn_rt_Array_Float_126_38:0, KaTSXR_r_EVM_CalcStrtgcTlfEqn_KaTSXR_r_EVM_CalcStrtgcTlfEqn_rt_Array_Float_126_39:0, KaTSXR_r_EVM_CalcStrtgcTlfEqn_KaTSXR_r_EVM_CalcStrtgcTlfEqn_rt_Array_Float_126_40:0, KaTSXR_r_EVM_CalcStrtgcTlfEqn_KaTSXR_r_EVM_CalcStrtgcTlfEqn_rt_Array_Float_126_41:0, KaTSXR_r_EVM_CalcStrtgcTlfEqn_KaTSXR_r_EVM_CalcStrtgcTlfEqn_rt_Array_Float_126_42:0, KaTSXR_r_EVM_CalcStrtgcTlfEqn_KaTSXR_r_EVM_CalcStrtgcTlfEqn_rt_Array_Float_126_43:0, KaTSXR_r_EVM_CalcStrtgcTlfEqn_KaTSXR_r_EVM_CalcStrtgcTlfEqn_rt_Array_Float_126_44:0, KaTSXR_r_EVM_CalcStrtgcTlfEqn_KaTSXR_r_EVM_CalcStrtgcTlfEqn_rt_Array_Float_126_45:0, KaTSXR_r_EVM_CalcStrtgcTlfEqn_KaTSXR_r_EVM_CalcStrtgcTlfEqn_rt_Array_Float_126_46:0, KaTSXR_r_EVM_CalcStrtgcTlfEqn_KaTSXR_r_EVM_CalcStrtgcTlfEqn_rt_Array_Float_126_47:0, KaTSXR_r_EVM_CalcStrtgcTlfEqn_KaTSXR_r_EVM_CalcStrtgcTlfEqn_rt_Array_Float_126_48:0, KaTSXR_r_EVM_CalcStrtgcTlfEqn_KaTSXR_r_EVM_CalcStrtgcTlfEqn_rt_Array_Float_126_49:0, KaTSXR_r_EVM_CalcStrtgcTlfEqn_KaTSXR_r_EVM_CalcStrtgcTlfEqn_rt_Array_Float_126_50:0, KaTSXR_r_EVM_CalcStrtgcTlfEqn_KaTSXR_r_EVM_CalcStrtgcTlfEqn_rt_Array_Float_126_51:0, KaTSXR_r_EVM_CalcStrtgcTlfEqn_KaTSXR_r_EVM_CalcStrtgcTlfEqn_rt_Array_Float_126_52:0, KaTSXR_r_EVM_CalcStrtgcTlfEqn_KaTSXR_r_EVM_CalcStrtgcTlfEqn_rt_Array_Float_126_53:0, KaTSXR_r_EVM_CalcStrtgcTlfEqn_KaTSXR_r_EVM_CalcStrtgcTlfEqn_rt_Array_Float_126_54:0, KaTSXR_r_EVM_CalcStrtgcTlfEqn_KaTSXR_r_EVM_CalcStrtgcTlfEqn_rt_Array_Float_126_55:0, KaTSXR_r_EVM_CalcStrtgcTlfEqn_KaTSXR_r_EVM_CalcStrtgcTlfEqn_rt_Array_Float_126_56:0, KaTSXR_r_EVM_CalcStrtgcTlfEqn_KaTSXR_r_EVM_CalcStrtgcTlfEqn_rt_Array_Float_126_57:0, KaTSXR_r_EVM_CalcStrtgcTlfEqn_KaTSXR_r_EVM_CalcStrtgcTlfEqn_rt_Array_Float_126_58:0, KaTSXR_r_EVM_CalcStrtgcTlfEqn_KaTSXR_r_EVM_CalcStrtgcTlfEqn_rt_Array_Float_126_59:0, KaTSXR_r_EVM_CalcStrtgcTlfEqn_KaTSXR_r_EVM_CalcStrtgcTlfEqn_rt_Array_Float_126_60:0, KaTSXR_r_EVM_CalcStrtgcTlfEqn_KaTSXR_r_EVM_CalcStrtgcTlfEqn_rt_Array_Float_126_61:0, KaTSXR_r_EVM_CalcStrtgcTlfEqn_KaTSXR_r_EVM_CalcStrtgcTlfEqn_rt_Array_Float_126_62:0, KaTSXR_r_EVM_CalcStrtgcTlfEqn_KaTSXR_r_EVM_CalcStrtgcTlfEqn_rt_Array_Float_126_63:0, KaTSXR_r_EVM_CalcStrtgcTlfEqn_KaTSXR_r_EVM_CalcStrtgcTlfEqn_rt_Array_Float_126_64:0, KaTSXR_r_EVM_CalcStrtgcTlfEqn_KaTSXR_r_EVM_CalcStrtgcTlfEqn_rt_Array_Float_126_65:0, KaTSXR_r_EVM_CalcStrtgcTlfEqn_KaTSXR_r_EVM_CalcStrtgcTlfEqn_rt_Array_Float_126_66:0, KaTSXR_r_EVM_CalcStrtgcTlfEqn_KaTSXR_r_EVM_CalcStrtgcTlfEqn_rt_Array_Float_126_67:0, KaTSXR_r_EVM_CalcStrtgcTlfEqn_KaTSXR_r_EVM_CalcStrtgcTlfEqn_rt_Array_Float_126_68:0, KaTSXR_r_EVM_CalcStrtgcTlfEqn_KaTSXR_r_EVM_CalcStrtgcTlfEqn_rt_Array_Float_126_69:0, KaTSXR_r_EVM_CalcStrtgcTlfEqn_KaTSXR_r_EVM_CalcStrtgcTlfEqn_rt_Array_Float_126_70:0, KaTSXR_r_EVM_CalcStrtgcTlfEqn_KaTSXR_r_EVM_CalcStrtgcTlfEqn_rt_Array_Float_126_71:0, KaTSXR_r_EVM_CalcStrtgcTlfEqn_KaTSXR_r_EVM_CalcStrtgcTlfEqn_rt_Array_Float_126_72:0, KaTSXR_r_EVM_CalcStrtgcTlfEqn_KaTSXR_r_EVM_CalcStrtgcTlfEqn_rt_Array_Float_126_73:0, KaTSXR_r_EVM_CalcStrtgcTlfEqn_KaTSXR_r_EVM_CalcStrtgcTlfEqn_rt_Array_Float_126_74:0, KaTSXR_r_EVM_CalcStrtgcTlfEqn_KaTSXR_r_EVM_CalcStrtgcTlfEqn_rt_Array_Float_126_75:0, KaTSXR_r_EVM_CalcStrtgcTlfEqn_KaTSXR_r_EVM_CalcStrtgcTlfEqn_rt_Array_Float_126_76:0, KaTSXR_r_EVM_CalcStrtgcTlfEqn_KaTSXR_r_EVM_CalcStrtgcTlfEqn_rt_Array_Float_126_77:0, KaTSXR_r_EVM_CalcStrtgcTlfEqn_KaTSXR_r_EVM_CalcStrtgcTlfEqn_rt_Array_Float_126_78:0, KaTSXR_r_EVM_CalcStrtgcTlfEqn_KaTSXR_r_EVM_CalcStrtgcTlfEqn_rt_Array_Float_126_79:0, KaTSXR_r_EVM_CalcStrtgcTlfEqn_KaTSXR_r_EVM_CalcStrtgcTlfEqn_rt_Array_Float_126_80:0, KaTSXR_r_EVM_CalcStrtgcTlfEqn_KaTSXR_r_EVM_CalcStrtgcTlfEqn_rt_Array_Float_126_81:0, KaTSXR_r_EVM_CalcStrtgcTlfEqn_KaTSXR_r_EVM_CalcStrtgcTlfEqn_rt_Array_Float_126_82:0, KaTSXR_r_EVM_CalcStrtgcTlfEqn_KaTSXR_r_EVM_CalcStrtgcTlfEqn_rt_Array_Float_126_83:0, KaTSXR_r_EVM_CalcStrtgcTlfEqn_KaTSXR_r_EVM_CalcStrtgcTlfEqn_rt_Array_Float_126_84:0, KaTSXR_r_EVM_CalcStrtgcTlfEqn_KaTSXR_r_EVM_CalcStrtgcTlfEqn_rt_Array_Float_126_85:0, KaTSXR_r_EVM_CalcStrtgcTlfEqn_KaTSXR_r_EVM_CalcStrtgcTlfEqn_rt_Array_Float_126_86:0, KaTSXR_r_EVM_CalcStrtgcTlfEqn_KaTSXR_r_EVM_CalcStrtgcTlfEqn_rt_Array_Float_126_87:0, KaTSXR_r_EVM_CalcStrtgcTlfEqn_KaTSXR_r_EVM_CalcStrtgcTlfEqn_rt_Array_Float_126_88:0, KaTSXR_r_EVM_CalcStrtgcTlfEqn_KaTSXR_r_EVM_CalcStrtgcTlfEqn_rt_Array_Float_126_89:0, KaTSXR_r_EVM_CalcStrtgcTlfEqn_KaTSXR_r_EVM_CalcStrtgcTlfEqn_rt_Array_Float_126_90:0, KaTSXR_r_EVM_CalcStrtgcTlfEqn_KaTSXR_r_EVM_CalcStrtgcTlfEqn_rt_Array_Float_126_91:0, KaTSXR_r_EVM_CalcStrtgcTlfEqn_KaTSXR_r_EVM_CalcStrtgcTlfEqn_rt_Array_Float_126_92:0, KaTSXR_r_EVM_CalcStrtgcTlfEqn_KaTSXR_r_EVM_CalcStrtgcTlfEqn_rt_Array_Float_126_93:0, KaTSXR_r_EVM_CalcStrtgcTlfEqn_KaTSXR_r_EVM_CalcStrtgcTlfEqn_rt_Array_Float_126_94:0, KaTSXR_r_EVM_CalcStrtgcTlfEqn_KaTSXR_r_EVM_CalcStrtgcTlfEqn_rt_Array_Float_126_95:0, KaTSXR_r_EVM_CalcStrtgcTlfEqn_KaTSXR_r_EVM_CalcStrtgcTlfEqn_rt_Array_Float_126_96:0, KaTSXR_r_EVM_CalcStrtgcTlfEqn_KaTSXR_r_EVM_CalcStrtgcTlfEqn_rt_Array_Float_126_97:0, KaTSXR_r_EVM_CalcStrtgcTlfEqn_KaTSXR_r_EVM_CalcStrtgcTlfEqn_rt_Array_Float_126_98:0, KaTSXR_r_EVM_CalcStrtgcTlfEqn_KaTSXR_r_EVM_CalcStrtgcTlfEqn_rt_Array_Float_126_99:0, KaTSXR_r_EVM_CalcStrtgcTlfEqn_KaTSXR_r_EVM_CalcStrtgcTlfEqn_rt_Array_Float_126_100:0, KaTSXR_r_EVM_CalcStrtgcTlfEqn_KaTSXR_r_EVM_CalcStrtgcTlfEqn_rt_Array_Float_126_101:0, KaTSXR_r_EVM_CalcStrtgcTlfEqn_KaTSXR_r_EVM_CalcStrtgcTlfEqn_rt_Array_Float_126_102:0, KaTSXR_r_EVM_CalcStrtgcTlfEqn_KaTSXR_r_EVM_CalcStrtgcTlfEqn_rt_Array_Float_126_103:0, KaTSXR_r_EVM_CalcStrtgcTlfEqn_KaTSXR_r_EVM_CalcStrtgcTlfEqn_rt_Array_Float_126_104:0, KaTSXR_r_EVM_CalcStrtgcTlfEqn_KaTSXR_r_EVM_CalcStrtgcTlfEqn_rt_Array_Float_126_105:0, KaTSXR_r_EVM_CalcStrtgcTlfEqn_KaTSXR_r_EVM_CalcStrtgcTlfEqn_rt_Array_Float_126_106:0, KaTSXR_r_EVM_CalcStrtgcTlfEqn_KaTSXR_r_EVM_CalcStrtgcTlfEqn_rt_Array_Float_126_107:0, KaTSXR_r_EVM_CalcStrtgcTlfEqn_KaTSXR_r_EVM_CalcStrtgcTlfEqn_rt_Array_Float_126_108:0, KaTSXR_r_EVM_CalcStrtgcTlfEqn_KaTSXR_r_EVM_CalcStrtgcTlfEqn_rt_Array_Float_126_109:0, KaTSXR_r_EVM_CalcStrtgcTlfEqn_KaTSXR_r_EVM_CalcStrtgcTlfEqn_rt_Array_Float_126_110:0, KaTSXR_r_EVM_CalcStrtgcTlfEqn_KaTSXR_r_EVM_CalcStrtgcTlfEqn_rt_Array_Float_126_111:0, KaTSXR_r_EVM_CalcStrtgcTlfEqn_KaTSXR_r_EVM_CalcStrtgcTlfEqn_rt_Array_Float_126_112:0, KaTSXR_r_EVM_CalcStrtgcTlfEqn_KaTSXR_r_EVM_CalcStrtgcTlfEqn_rt_Array_Float_126_113:0, KaTSXR_r_EVM_CalcStrtgcTlfEqn_KaTSXR_r_EVM_CalcStrtgcTlfEqn_rt_Array_Float_126_114:0, KaTSXR_r_EVM_CalcStrtgcTlfEqn_KaTSXR_r_EVM_CalcStrtgcTlfEqn_rt_Array_Float_126_115:0, KaTSXR_r_EVM_CalcStrtgcTlfEqn_KaTSXR_r_EVM_CalcStrtgcTlfEqn_rt_Array_Float_126_116:0, KaTSXR_r_EVM_CalcStrtgcTlfEqn_KaTSXR_r_EVM_CalcStrtgcTlfEqn_rt_Array_Float_126_117:0, KaTSXR_r_EVM_CalcStrtgcTlfEqn_KaTSXR_r_EVM_CalcStrtgcTlfEqn_rt_Array_Float_126_118:0, KaTSXR_r_EVM_CalcStrtgcTlfEqn_KaTSXR_r_EVM_CalcStrtgcTlfEqn_rt_Array_Float_126_119:0, KaTSXR_r_EVM_CalcStrtgcTlfEqn_KaTSXR_r_EVM_CalcStrtgcTlfEqn_rt_Array_Float_126_120:0, KaTSXR_r_EVM_CalcStrtgcTlfEqn_KaTSXR_r_EVM_CalcStrtgcTlfEqn_rt_Array_Float_126_121:0, KaTSXR_r_EVM_CalcStrtgcTlfEqn_KaTSXR_r_EVM_CalcStrtgcTlfEqn_rt_Array_Float_126_122:0, KaTSXR_r_EVM_CalcStrtgcTlfEqn_KaTSXR_r_EVM_CalcStrtgcTlfEqn_rt_Array_Float_126_123:0, KaTSXR_r_EVM_CalcStrtgcTlfEqn_KaTSXR_r_EVM_CalcStrtgcTlfEqn_rt_Array_Float_126_124:0, KaTSXR_r_EVM_CalcStrtgcTlfEqn_KaTSXR_r_EVM_CalcStrtgcTlfEqn_rt_Array_Float_126_125:0, KaTSXR_r_EVM_CalcStrtgcTlfEqn_KaTSXR_r_EVM_CalcStrtgcTlfEqn_rt_Array_Float_126_126:0], parameter=KaTSXR_r_EVM_CalcStrtgcTlfEqn}, required-interface=KaTSXR_r_EVM_CalcStrtgcTlfEqn
      KaTSXR_r_EVM_CalcTc{1..4}Eqn: parameter-require-com-spec{init-value=KaTSXR_r_EVM_CalcTc{1..4}Eqn_KaTSXR_r_EVM_CalcTc{1..4}Eqn:[KaTSXR_r_EVM_CalcTc{1..4}Eqn_KaTSXR_r_EVM_CalcTc{1..4}Eqn_rt_Array_Float_126_1:0, KaTSXR_r_EVM_CalcTc{1..4}Eqn_KaTSXR_r_EVM_CalcTc{1..4}Eqn_rt_Array_Float_126_2:0, KaTSXR_r_EVM_CalcTc{1..4}Eqn_KaTSXR_r_EVM_CalcTc{1..4}Eqn_rt_Array_Float_126_3:0, KaTSXR_r_EVM_CalcTc{1..4}Eqn_KaTSXR_r_EVM_CalcTc{1..4}Eqn_rt_Array_Float_126_4:0, KaTSXR_r_EVM_CalcTc{1..4}Eqn_KaTSXR_r_EVM_CalcTc{1..4}Eqn_rt_Array_Float_126_5:0, KaTSXR_r_EVM_CalcTc{1..4}Eqn_KaTSXR_r_EVM_CalcTc{1..4}Eqn_rt_Array_Float_126_6:0, KaTSXR_r_EVM_CalcTc{1..4}Eqn_KaTSXR_r_EVM_CalcTc{1..4}Eqn_rt_Array_Float_126_7:0, KaTSXR_r_EVM_CalcTc{1..4}Eqn_KaTSXR_r_EVM_CalcTc{1..4}Eqn_rt_Array_Float_126_8:0, KaTSXR_r_EVM_CalcTc{1..4}Eqn_KaTSXR_r_EVM_CalcTc{1..4}Eqn_rt_Array_Float_126_9:0, KaTSXR_r_EVM_CalcTc{1..4}Eqn_KaTSXR_r_EVM_CalcTc{1..4}Eqn_rt_Array_Float_126_10:0, KaTSXR_r_EVM_CalcTc{1..4}Eqn_KaTSXR_r_EVM_CalcTc{1..4}Eqn_rt_Array_Float_126_11:0, KaTSXR_r_EVM_CalcTc{1..4}Eqn_KaTSXR_r_EVM_CalcTc{1..4}Eqn_rt_Array_Float_126_12:0, KaTSXR_r_EVM_CalcTc{1..4}Eqn_KaTSXR_r_EVM_CalcTc{1..4}Eqn_rt_Array_Float_126_13:0, KaTSXR_r_EVM_CalcTc{1..4}Eqn_KaTSXR_r_EVM_CalcTc{1..4}Eqn_rt_Array_Float_126_14:0, KaTSXR_r_EVM_CalcTc{1..4}Eqn_KaTSXR_r_EVM_CalcTc{1..4}Eqn_rt_Array_Float_126_15:0, KaTSXR_r_EVM_CalcTc{1..4}Eqn_KaTSXR_r_EVM_CalcTc{1..4}Eqn_rt_Array_Float_126_16:0, KaTSXR_r_EVM_CalcTc{1..4}Eqn_KaTSXR_r_EVM_CalcTc{1..4}Eqn_rt_Array_Float_126_17:0, KaTSXR_r_EVM_CalcTc{1..4}Eqn_KaTSXR_r_EVM_CalcTc{1..4}Eqn_rt_Array_Float_126_18:0, KaTSXR_r_EVM_CalcTc{1..4}Eqn_KaTSXR_r_EVM_CalcTc{1..4}Eqn_rt_Array_Float_126_19:0, KaTSXR_r_EVM_CalcTc{1..4}Eqn_KaTSXR_r_EVM_CalcTc{1..4}Eqn_rt_Array_Float_126_20:0, KaTSXR_r_EVM_CalcTc{1..4}Eqn_KaTSXR_r_EVM_CalcTc{1..4}Eqn_rt_Array_Float_126_21:0, KaTSXR_r_EVM_CalcTc{1..4}Eqn_KaTSXR_r_EVM_CalcTc{1..4}Eqn_rt_Array_Float_126_22:0, KaTSXR_r_EVM_CalcTc{1..4}Eqn_KaTSXR_r_EVM_CalcTc{1..4}Eqn_rt_Array_Float_126_23:0, KaTSXR_r_EVM_CalcTc{1..4}Eqn_KaTSXR_r_EVM_CalcTc{1..4}Eqn_rt_Array_Float_126_24:0, KaTSXR_r_EVM_CalcTc{1..4}Eqn_KaTSXR_r_EVM_CalcTc{1..4}Eqn_rt_Array_Float_126_25:0, KaTSXR_r_EVM_CalcTc{1..4}Eqn_KaTSXR_r_EVM_CalcTc{1..4}Eqn_rt_Array_Float_126_26:0, KaTSXR_r_EVM_CalcTc{1..4}Eqn_KaTSXR_r_EVM_CalcTc{1..4}Eqn_rt_Array_Float_126_27:0, KaTSXR_r_EVM_CalcTc{1..4}Eqn_KaTSXR_r_EVM_CalcTc{1..4}Eqn_rt_Array_Float_126_28:0, KaTSXR_r_EVM_CalcTc{1..4}Eqn_KaTSXR_r_EVM_CalcTc{1..4}Eqn_rt_Array_Float_126_29:0, KaTSXR_r_EVM_CalcTc{1..4}Eqn_KaTSXR_r_EVM_CalcTc{1..4}Eqn_rt_Array_Float_126_30:0, KaTSXR_r_EVM_CalcTc{1..4}Eqn_KaTSXR_r_EVM_CalcTc{1..4}Eqn_rt_Array_Float_126_31:0, KaTSXR_r_EVM_CalcTc{1..4}Eqn_KaTSXR_r_EVM_CalcTc{1..4}Eqn_rt_Array_Float_126_32:0, KaTSXR_r_EVM_CalcTc{1..4}Eqn_KaTSXR_r_EVM_CalcTc{1..4}Eqn_rt_Array_Float_126_33:0, KaTSXR_r_EVM_CalcTc{1..4}Eqn_KaTSXR_r_EVM_CalcTc{1..4}Eqn_rt_Array_Float_126_34:0, KaTSXR_r_EVM_CalcTc{1..4}Eqn_KaTSXR_r_EVM_CalcTc{1..4}Eqn_rt_Array_Float_126_35:0, KaTSXR_r_EVM_CalcTc{1..4}Eqn_KaTSXR_r_EVM_CalcTc{1..4}Eqn_rt_Array_Float_126_36:0, KaTSXR_r_EVM_CalcTc{1..4}Eqn_KaTSXR_r_EVM_CalcTc{1..4}Eqn_rt_Array_Float_126_37:0, KaTSXR_r_EVM_CalcTc{1..4}Eqn_KaTSXR_r_EVM_CalcTc{1..4}Eqn_rt_Array_Float_126_38:0, KaTSXR_r_EVM_CalcTc{1..4}Eqn_KaTSXR_r_EVM_CalcTc{1..4}Eqn_rt_Array_Float_126_39:0, KaTSXR_r_EVM_CalcTc{1..4}Eqn_KaTSXR_r_EVM_CalcTc{1..4}Eqn_rt_Array_Float_126_40:0, KaTSXR_r_EVM_CalcTc{1..4}Eqn_KaTSXR_r_EVM_CalcTc{1..4}Eqn_rt_Array_Float_126_41:0, KaTSXR_r_EVM_CalcTc{1..4}Eqn_KaTSXR_r_EVM_CalcTc{1..4}Eqn_rt_Array_Float_126_42:0, KaTSXR_r_EVM_CalcTc{1..4}Eqn_KaTSXR_r_EVM_CalcTc{1..4}Eqn_rt_Array_Float_126_43:0, KaTSXR_r_EVM_CalcTc{1..4}Eqn_KaTSXR_r_EVM_CalcTc{1..4}Eqn_rt_Array_Float_126_44:0, KaTSXR_r_EVM_CalcTc{1..4}Eqn_KaTSXR_r_EVM_CalcTc{1..4}Eqn_rt_Array_Float_126_45:0, KaTSXR_r_EVM_CalcTc{1..4}Eqn_KaTSXR_r_EVM_CalcTc{1..4}Eqn_rt_Array_Float_126_46:0, KaTSXR_r_EVM_CalcTc{1..4}Eqn_KaTSXR_r_EVM_CalcTc{1..4}Eqn_rt_Array_Float_126_47:0, KaTSXR_r_EVM_CalcTc{1..4}Eqn_KaTSXR_r_EVM_CalcTc{1..4}Eqn_rt_Array_Float_126_48:0, KaTSXR_r_EVM_CalcTc{1..4}Eqn_KaTSXR_r_EVM_CalcTc{1..4}Eqn_rt_Array_Float_126_49:0, KaTSXR_r_EVM_CalcTc{1..4}Eqn_KaTSXR_r_EVM_CalcTc{1..4}Eqn_rt_Array_Float_126_50:0, KaTSXR_r_EVM_CalcTc{1..4}Eqn_KaTSXR_r_EVM_CalcTc{1..4}Eqn_rt_Array_Float_126_51:0, KaTSXR_r_EVM_CalcTc{1..4}Eqn_KaTSXR_r_EVM_CalcTc{1..4}Eqn_rt_Array_Float_126_52:0, KaTSXR_r_EVM_CalcTc{1..4}Eqn_KaTSXR_r_EVM_CalcTc{1..4}Eqn_rt_Array_Float_126_53:0, KaTSXR_r_EVM_CalcTc{1..4}Eqn_KaTSXR_r_EVM_CalcTc{1..4}Eqn_rt_Array_Float_126_54:0, KaTSXR_r_EVM_CalcTc{1..4}Eqn_KaTSXR_r_EVM_CalcTc{1..4}Eqn_rt_Array_Float_126_55:0, KaTSXR_r_EVM_CalcTc{1..4}Eqn_KaTSXR_r_EVM_CalcTc{1..4}Eqn_rt_Array_Float_126_56:0, KaTSXR_r_EVM_CalcTc{1..4}Eqn_KaTSXR_r_EVM_CalcTc{1..4}Eqn_rt_Array_Float_126_57:0, KaTSXR_r_EVM_CalcTc{1..4}Eqn_KaTSXR_r_EVM_CalcTc{1..4}Eqn_rt_Array_Float_126_58:0, KaTSXR_r_EVM_CalcTc{1..4}Eqn_KaTSXR_r_EVM_CalcTc{1..4}Eqn_rt_Array_Float_126_59:0, KaTSXR_r_EVM_CalcTc{1..4}Eqn_KaTSXR_r_EVM_CalcTc{1..4}Eqn_rt_Array_Float_126_60:0, KaTSXR_r_EVM_CalcTc{1..4}Eqn_KaTSXR_r_EVM_CalcTc{1..4}Eqn_rt_Array_Float_126_61:0, KaTSXR_r_EVM_CalcTc{1..4}Eqn_KaTSXR_r_EVM_CalcTc{1..4}Eqn_rt_Array_Float_126_62:0, KaTSXR_r_EVM_CalcTc{1..4}Eqn_KaTSXR_r_EVM_CalcTc{1..4}Eqn_rt_Array_Float_126_63:0, KaTSXR_r_EVM_CalcTc{1..4}Eqn_KaTSXR_r_EVM_CalcTc{1..4}Eqn_rt_Array_Float_126_64:0, KaTSXR_r_EVM_CalcTc{1..4}Eqn_KaTSXR_r_EVM_CalcTc{1..4}Eqn_rt_Array_Float_126_65:0, KaTSXR_r_EVM_CalcTc{1..4}Eqn_KaTSXR_r_EVM_CalcTc{1..4}Eqn_rt_Array_Float_126_66:0, KaTSXR_r_EVM_CalcTc{1..4}Eqn_KaTSXR_r_EVM_CalcTc{1..4}Eqn_rt_Array_Float_126_67:0, KaTSXR_r_EVM_CalcTc{1..4}Eqn_KaTSXR_r_EVM_CalcTc{1..4}Eqn_rt_Array_Float_126_68:0, KaTSXR_r_EVM_CalcTc{1..4}Eqn_KaTSXR_r_EVM_CalcTc{1..4}Eqn_rt_Array_Float_126_69:0, KaTSXR_r_EVM_CalcTc{1..4}Eqn_KaTSXR_r_EVM_CalcTc{1..4}Eqn_rt_Array_Float_126_70:0, KaTSXR_r_EVM_CalcTc{1..4}Eqn_KaTSXR_r_EVM_CalcTc{1..4}Eqn_rt_Array_Float_126_71:0, KaTSXR_r_EVM_CalcTc{1..4}Eqn_KaTSXR_r_EVM_CalcTc{1..4}Eqn_rt_Array_Float_126_72:0, KaTSXR_r_EVM_CalcTc{1..4}Eqn_KaTSXR_r_EVM_CalcTc{1..4}Eqn_rt_Array_Float_126_73:0, KaTSXR_r_EVM_CalcTc{1..4}Eqn_KaTSXR_r_EVM_CalcTc{1..4}Eqn_rt_Array_Float_126_74:0, KaTSXR_r_EVM_CalcTc{1..4}Eqn_KaTSXR_r_EVM_CalcTc{1..4}Eqn_rt_Array_Float_126_75:0, KaTSXR_r_EVM_CalcTc{1..4}Eqn_KaTSXR_r_EVM_CalcTc{1..4}Eqn_rt_Array_Float_126_76:0, KaTSXR_r_EVM_CalcTc{1..4}Eqn_KaTSXR_r_EVM_CalcTc{1..4}Eqn_rt_Array_Float_126_77:0, KaTSXR_r_EVM_CalcTc{1..4}Eqn_KaTSXR_r_EVM_CalcTc{1..4}Eqn_rt_Array_Float_126_78:0, KaTSXR_r_EVM_CalcTc{1..4}Eqn_KaTSXR_r_EVM_CalcTc{1..4}Eqn_rt_Array_Float_126_79:0, KaTSXR_r_EVM_CalcTc{1..4}Eqn_KaTSXR_r_EVM_CalcTc{1..4}Eqn_rt_Array_Float_126_80:0, KaTSXR_r_EVM_CalcTc{1..4}Eqn_KaTSXR_r_EVM_CalcTc{1..4}Eqn_rt_Array_Float_126_81:0, KaTSXR_r_EVM_CalcTc{1..4}Eqn_KaTSXR_r_EVM_CalcTc{1..4}Eqn_rt_Array_Float_126_82:0, KaTSXR_r_EVM_CalcTc{1..4}Eqn_KaTSXR_r_EVM_CalcTc{1..4}Eqn_rt_Array_Float_126_83:0, KaTSXR_r_EVM_CalcTc{1..4}Eqn_KaTSXR_r_EVM_CalcTc{1..4}Eqn_rt_Array_Float_126_84:0, KaTSXR_r_EVM_CalcTc{1..4}Eqn_KaTSXR_r_EVM_CalcTc{1..4}Eqn_rt_Array_Float_126_85:0, KaTSXR_r_EVM_CalcTc{1..4}Eqn_KaTSXR_r_EVM_CalcTc{1..4}Eqn_rt_Array_Float_126_86:0, KaTSXR_r_EVM_CalcTc{1..4}Eqn_KaTSXR_r_EVM_CalcTc{1..4}Eqn_rt_Array_Float_126_87:0, KaTSXR_r_EVM_CalcTc{1..4}Eqn_KaTSXR_r_EVM_CalcTc{1..4}Eqn_rt_Array_Float_126_88:0, KaTSXR_r_EVM_CalcTc{1..4}Eqn_KaTSXR_r_EVM_CalcTc{1..4}Eqn_rt_Array_Float_126_89:0, KaTSXR_r_EVM_CalcTc{1..4}Eqn_KaTSXR_r_EVM_CalcTc{1..4}Eqn_rt_Array_Float_126_90:0, KaTSXR_r_EVM_CalcTc{1..4}Eqn_KaTSXR_r_EVM_CalcTc{1..4}Eqn_rt_Array_Float_126_91:0, KaTSXR_r_EVM_CalcTc{1..4}Eqn_KaTSXR_r_EVM_CalcTc{1..4}Eqn_rt_Array_Float_126_92:0, KaTSXR_r_EVM_CalcTc{1..4}Eqn_KaTSXR_r_EVM_CalcTc{1..4}Eqn_rt_Array_Float_126_93:0, KaTSXR_r_EVM_CalcTc{1..4}Eqn_KaTSXR_r_EVM_CalcTc{1..4}Eqn_rt_Array_Float_126_94:0, KaTSXR_r_EVM_CalcTc{1..4}Eqn_KaTSXR_r_EVM_CalcTc{1..4}Eqn_rt_Array_Float_126_95:0, KaTSXR_r_EVM_CalcTc{1..4}Eqn_KaTSXR_r_EVM_CalcTc{1..4}Eqn_rt_Array_Float_126_96:0, KaTSXR_r_EVM_CalcTc{1..4}Eqn_KaTSXR_r_EVM_CalcTc{1..4}Eqn_rt_Array_Float_126_97:0, KaTSXR_r_EVM_CalcTc{1..4}Eqn_KaTSXR_r_EVM_CalcTc{1..4}Eqn_rt_Array_Float_126_98:0, KaTSXR_r_EVM_CalcTc{1..4}Eqn_KaTSXR_r_EVM_CalcTc{1..4}Eqn_rt_Array_Float_126_99:0, KaTSXR_r_EVM_CalcTc{1..4}Eqn_KaTSXR_r_EVM_CalcTc{1..4}Eqn_rt_Array_Float_126_100:0, KaTSXR_r_EVM_CalcTc{1..4}Eqn_KaTSXR_r_EVM_CalcTc{1..4}Eqn_rt_Array_Float_126_101:0, KaTSXR_r_EVM_CalcTc{1..4}Eqn_KaTSXR_r_EVM_CalcTc{1..4}Eqn_rt_Array_Float_126_102:0, KaTSXR_r_EVM_CalcTc{1..4}Eqn_KaTSXR_r_EVM_CalcTc{1..4}Eqn_rt_Array_Float_126_103:0, KaTSXR_r_EVM_CalcTc{1..4}Eqn_KaTSXR_r_EVM_CalcTc{1..4}Eqn_rt_Array_Float_126_104:0, KaTSXR_r_EVM_CalcTc{1..4}Eqn_KaTSXR_r_EVM_CalcTc{1..4}Eqn_rt_Array_Float_126_105:0, KaTSXR_r_EVM_CalcTc{1..4}Eqn_KaTSXR_r_EVM_CalcTc{1..4}Eqn_rt_Array_Float_126_106:0, KaTSXR_r_EVM_CalcTc{1..4}Eqn_KaTSXR_r_EVM_CalcTc{1..4}Eqn_rt_Array_Float_126_107:0, KaTSXR_r_EVM_CalcTc{1..4}Eqn_KaTSXR_r_EVM_CalcTc{1..4}Eqn_rt_Array_Float_126_108:0, KaTSXR_r_EVM_CalcTc{1..4}Eqn_KaTSXR_r_EVM_CalcTc{1..4}Eqn_rt_Array_Float_126_109:0, KaTSXR_r_EVM_CalcTc{1..4}Eqn_KaTSXR_r_EVM_CalcTc{1..4}Eqn_rt_Array_Float_126_110:0, KaTSXR_r_EVM_CalcTc{1..4}Eqn_KaTSXR_r_EVM_CalcTc{1..4}Eqn_rt_Array_Float_126_111:0, KaTSXR_r_EVM_CalcTc{1..4}Eqn_KaTSXR_r_EVM_CalcTc{1..4}Eqn_rt_Array_Float_126_112:0, KaTSXR_r_EVM_CalcTc{1..4}Eqn_KaTSXR_r_EVM_CalcTc{1..4}Eqn_rt_Array_Float_126_113:0, KaTSXR_r_EVM_CalcTc{1..4}Eqn_KaTSXR_r_EVM_CalcTc{1..4}Eqn_rt_Array_Float_126_114:0, KaTSXR_r_EVM_CalcTc{1..4}Eqn_KaTSXR_r_EVM_CalcTc{1..4}Eqn_rt_Array_Float_126_115:0, KaTSXR_r_EVM_CalcTc{1..4}Eqn_KaTSXR_r_EVM_CalcTc{1..4}Eqn_rt_Array_Float_126_116:0, KaTSXR_r_EVM_CalcTc{1..4}Eqn_KaTSXR_r_EVM_CalcTc{1..4}Eqn_rt_Array_Float_126_117:0, KaTSXR_r_EVM_CalcTc{1..4}Eqn_KaTSXR_r_EVM_CalcTc{1..4}Eqn_rt_Array_Float_126_118:0, KaTSXR_r_EVM_CalcTc{1..4}Eqn_KaTSXR_r_EVM_CalcTc{1..4}Eqn_rt_Array_Float_126_119:0, KaTSXR_r_EVM_CalcTc{1..4}Eqn_KaTSXR_r_EVM_CalcTc{1..4}Eqn_rt_Array_Float_126_120:0, KaTSXR_r_EVM_CalcTc{1..4}Eqn_KaTSXR_r_EVM_CalcTc{1..4}Eqn_rt_Array_Float_126_121:0, KaTSXR_r_EVM_CalcTc{1..4}Eqn_KaTSXR_r_EVM_CalcTc{1..4}Eqn_rt_Array_Float_126_122:0, KaTSXR_r_EVM_CalcTc{1..4}Eqn_KaTSXR_r_EVM_CalcTc{1..4}Eqn_rt_Array_Float_126_123:0, KaTSXR_r_EVM_CalcTc{1..4}Eqn_KaTSXR_r_EVM_CalcTc{1..4}Eqn_rt_Array_Float_126_124:0, KaTSXR_r_EVM_CalcTc{1..4}Eqn_KaTSXR_r_EVM_CalcTc{1..4}Eqn_rt_Array_Float_126_125:0, KaTSXR_r_EVM_CalcTc{1..4}Eqn_KaTSXR_r_EVM_CalcTc{1..4}Eqn_rt_Array_Float_126_126:0], parameter=KaTSXR_r_EVM_CalcTc{1..4}Eqn}, required-interface=KaTSXR_r_EVM_CalcTc{1..4}Eqn
      KaTSXR_r_EVM_CalcTofEqn: parameter-require-com-spec{init-value=KaTSXR_r_EVM_CalcTofEqn_KaTSXR_r_EVM_CalcTofEqn:[KaTSXR_r_EVM_CalcTofEqn_KaTSXR_r_EVM_CalcTofEqn_rt_Array_Float_126_1:0, KaTSXR_r_EVM_CalcTofEqn_KaTSXR_r_EVM_CalcTofEqn_rt_Array_Float_126_2:0, KaTSXR_r_EVM_CalcTofEqn_KaTSXR_r_EVM_CalcTofEqn_rt_Array_Float_126_3:0, KaTSXR_r_EVM_CalcTofEqn_KaTSXR_r_EVM_CalcTofEqn_rt_Array_Float_126_4:0, KaTSXR_r_EVM_CalcTofEqn_KaTSXR_r_EVM_CalcTofEqn_rt_Array_Float_126_5:0, KaTSXR_r_EVM_CalcTofEqn_KaTSXR_r_EVM_CalcTofEqn_rt_Array_Float_126_6:0, KaTSXR_r_EVM_CalcTofEqn_KaTSXR_r_EVM_CalcTofEqn_rt_Array_Float_126_7:0, KaTSXR_r_EVM_CalcTofEqn_KaTSXR_r_EVM_CalcTofEqn_rt_Array_Float_126_8:0, KaTSXR_r_EVM_CalcTofEqn_KaTSXR_r_EVM_CalcTofEqn_rt_Array_Float_126_9:0, KaTSXR_r_EVM_CalcTofEqn_KaTSXR_r_EVM_CalcTofEqn_rt_Array_Float_126_10:0, KaTSXR_r_EVM_CalcTofEqn_KaTSXR_r_EVM_CalcTofEqn_rt_Array_Float_126_11:0, KaTSXR_r_EVM_CalcTofEqn_KaTSXR_r_EVM_CalcTofEqn_rt_Array_Float_126_12:0, KaTSXR_r_EVM_CalcTofEqn_KaTSXR_r_EVM_CalcTofEqn_rt_Array_Float_126_13:0, KaTSXR_r_EVM_CalcTofEqn_KaTSXR_r_EVM_CalcTofEqn_rt_Array_Float_126_14:0, KaTSXR_r_EVM_CalcTofEqn_KaTSXR_r_EVM_CalcTofEqn_rt_Array_Float_126_15:0, KaTSXR_r_EVM_CalcTofEqn_KaTSXR_r_EVM_CalcTofEqn_rt_Array_Float_126_16:0, KaTSXR_r_EVM_CalcTofEqn_KaTSXR_r_EVM_CalcTofEqn_rt_Array_Float_126_17:0, KaTSXR_r_EVM_CalcTofEqn_KaTSXR_r_EVM_CalcTofEqn_rt_Array_Float_126_18:0, KaTSXR_r_EVM_CalcTofEqn_KaTSXR_r_EVM_CalcTofEqn_rt_Array_Float_126_19:0, KaTSXR_r_EVM_CalcTofEqn_KaTSXR_r_EVM_CalcTofEqn_rt_Array_Float_126_20:0, KaTSXR_r_EVM_CalcTofEqn_KaTSXR_r_EVM_CalcTofEqn_rt_Array_Float_126_21:0, KaTSXR_r_EVM_CalcTofEqn_KaTSXR_r_EVM_CalcTofEqn_rt_Array_Float_126_22:0, KaTSXR_r_EVM_CalcTofEqn_KaTSXR_r_EVM_CalcTofEqn_rt_Array_Float_126_23:0, KaTSXR_r_EVM_CalcTofEqn_KaTSXR_r_EVM_CalcTofEqn_rt_Array_Float_126_24:0, KaTSXR_r_EVM_CalcTofEqn_KaTSXR_r_EVM_CalcTofEqn_rt_Array_Float_126_25:0, KaTSXR_r_EVM_CalcTofEqn_KaTSXR_r_EVM_CalcTofEqn_rt_Array_Float_126_26:0, KaTSXR_r_EVM_CalcTofEqn_KaTSXR_r_EVM_CalcTofEqn_rt_Array_Float_126_27:0, KaTSXR_r_EVM_CalcTofEqn_KaTSXR_r_EVM_CalcTofEqn_rt_Array_Float_126_28:0, KaTSXR_r_EVM_CalcTofEqn_KaTSXR_r_EVM_CalcTofEqn_rt_Array_Float_126_29:0, KaTSXR_r_EVM_CalcTofEqn_KaTSXR_r_EVM_CalcTofEqn_rt_Array_Float_126_30:0, KaTSXR_r_EVM_CalcTofEqn_KaTSXR_r_EVM_CalcTofEqn_rt_Array_Float_126_31:0, KaTSXR_r_EVM_CalcTofEqn_KaTSXR_r_EVM_CalcTofEqn_rt_Array_Float_126_32:0, KaTSXR_r_EVM_CalcTofEqn_KaTSXR_r_EVM_CalcTofEqn_rt_Array_Float_126_33:0, KaTSXR_r_EVM_CalcTofEqn_KaTSXR_r_EVM_CalcTofEqn_rt_Array_Float_126_34:0, KaTSXR_r_EVM_CalcTofEqn_KaTSXR_r_EVM_CalcTofEqn_rt_Array_Float_126_35:0, KaTSXR_r_EVM_CalcTofEqn_KaTSXR_r_EVM_CalcTofEqn_rt_Array_Float_126_36:0, KaTSXR_r_EVM_CalcTofEqn_KaTSXR_r_EVM_CalcTofEqn_rt_Array_Float_126_37:0, KaTSXR_r_EVM_CalcTofEqn_KaTSXR_r_EVM_CalcTofEqn_rt_Array_Float_126_38:0, KaTSXR_r_EVM_CalcTofEqn_KaTSXR_r_EVM_CalcTofEqn_rt_Array_Float_126_39:0, KaTSXR_r_EVM_CalcTofEqn_KaTSXR_r_EVM_CalcTofEqn_rt_Array_Float_126_40:0, KaTSXR_r_EVM_CalcTofEqn_KaTSXR_r_EVM_CalcTofEqn_rt_Array_Float_126_41:0, KaTSXR_r_EVM_CalcTofEqn_KaTSXR_r_EVM_CalcTofEqn_rt_Array_Float_126_42:0, KaTSXR_r_EVM_CalcTofEqn_KaTSXR_r_EVM_CalcTofEqn_rt_Array_Float_126_43:0, KaTSXR_r_EVM_CalcTofEqn_KaTSXR_r_EVM_CalcTofEqn_rt_Array_Float_126_44:0, KaTSXR_r_EVM_CalcTofEqn_KaTSXR_r_EVM_CalcTofEqn_rt_Array_Float_126_45:0, KaTSXR_r_EVM_CalcTofEqn_KaTSXR_r_EVM_CalcTofEqn_rt_Array_Float_126_46:0, KaTSXR_r_EVM_CalcTofEqn_KaTSXR_r_EVM_CalcTofEqn_rt_Array_Float_126_47:0, KaTSXR_r_EVM_CalcTofEqn_KaTSXR_r_EVM_CalcTofEqn_rt_Array_Float_126_48:0, KaTSXR_r_EVM_CalcTofEqn_KaTSXR_r_EVM_CalcTofEqn_rt_Array_Float_126_49:0, KaTSXR_r_EVM_CalcTofEqn_KaTSXR_r_EVM_CalcTofEqn_rt_Array_Float_126_50:0, KaTSXR_r_EVM_CalcTofEqn_KaTSXR_r_EVM_CalcTofEqn_rt_Array_Float_126_51:0, KaTSXR_r_EVM_CalcTofEqn_KaTSXR_r_EVM_CalcTofEqn_rt_Array_Float_126_52:0, KaTSXR_r_EVM_CalcTofEqn_KaTSXR_r_EVM_CalcTofEqn_rt_Array_Float_126_53:0, KaTSXR_r_EVM_CalcTofEqn_KaTSXR_r_EVM_CalcTofEqn_rt_Array_Float_126_54:0, KaTSXR_r_EVM_CalcTofEqn_KaTSXR_r_EVM_CalcTofEqn_rt_Array_Float_126_55:0, KaTSXR_r_EVM_CalcTofEqn_KaTSXR_r_EVM_CalcTofEqn_rt_Array_Float_126_56:0, KaTSXR_r_EVM_CalcTofEqn_KaTSXR_r_EVM_CalcTofEqn_rt_Array_Float_126_57:0, KaTSXR_r_EVM_CalcTofEqn_KaTSXR_r_EVM_CalcTofEqn_rt_Array_Float_126_58:0, KaTSXR_r_EVM_CalcTofEqn_KaTSXR_r_EVM_CalcTofEqn_rt_Array_Float_126_59:0, KaTSXR_r_EVM_CalcTofEqn_KaTSXR_r_EVM_CalcTofEqn_rt_Array_Float_126_60:0, KaTSXR_r_EVM_CalcTofEqn_KaTSXR_r_EVM_CalcTofEqn_rt_Array_Float_126_61:0, KaTSXR_r_EVM_CalcTofEqn_KaTSXR_r_EVM_CalcTofEqn_rt_Array_Float_126_62:0, KaTSXR_r_EVM_CalcTofEqn_KaTSXR_r_EVM_CalcTofEqn_rt_Array_Float_126_63:0, KaTSXR_r_EVM_CalcTofEqn_KaTSXR_r_EVM_CalcTofEqn_rt_Array_Float_126_64:0, KaTSXR_r_EVM_CalcTofEqn_KaTSXR_r_EVM_CalcTofEqn_rt_Array_Float_126_65:0, KaTSXR_r_EVM_CalcTofEqn_KaTSXR_r_EVM_CalcTofEqn_rt_Array_Float_126_66:0, KaTSXR_r_EVM_CalcTofEqn_KaTSXR_r_EVM_CalcTofEqn_rt_Array_Float_126_67:0, KaTSXR_r_EVM_CalcTofEqn_KaTSXR_r_EVM_CalcTofEqn_rt_Array_Float_126_68:0, KaTSXR_r_EVM_CalcTofEqn_KaTSXR_r_EVM_CalcTofEqn_rt_Array_Float_126_69:0, KaTSXR_r_EVM_CalcTofEqn_KaTSXR_r_EVM_CalcTofEqn_rt_Array_Float_126_70:0, KaTSXR_r_EVM_CalcTofEqn_KaTSXR_r_EVM_CalcTofEqn_rt_Array_Float_126_71:0, KaTSXR_r_EVM_CalcTofEqn_KaTSXR_r_EVM_CalcTofEqn_rt_Array_Float_126_72:0, KaTSXR_r_EVM_CalcTofEqn_KaTSXR_r_EVM_CalcTofEqn_rt_Array_Float_126_73:0, KaTSXR_r_EVM_CalcTofEqn_KaTSXR_r_EVM_CalcTofEqn_rt_Array_Float_126_74:0, KaTSXR_r_EVM_CalcTofEqn_KaTSXR_r_EVM_CalcTofEqn_rt_Array_Float_126_75:0, KaTSXR_r_EVM_CalcTofEqn_KaTSXR_r_EVM_CalcTofEqn_rt_Array_Float_126_76:0, KaTSXR_r_EVM_CalcTofEqn_KaTSXR_r_EVM_CalcTofEqn_rt_Array_Float_126_77:0, KaTSXR_r_EVM_CalcTofEqn_KaTSXR_r_EVM_CalcTofEqn_rt_Array_Float_126_78:0, KaTSXR_r_EVM_CalcTofEqn_KaTSXR_r_EVM_CalcTofEqn_rt_Array_Float_126_79:0, KaTSXR_r_EVM_CalcTofEqn_KaTSXR_r_EVM_CalcTofEqn_rt_Array_Float_126_80:0, KaTSXR_r_EVM_CalcTofEqn_KaTSXR_r_EVM_CalcTofEqn_rt_Array_Float_126_81:0, KaTSXR_r_EVM_CalcTofEqn_KaTSXR_r_EVM_CalcTofEqn_rt_Array_Float_126_82:0, KaTSXR_r_EVM_CalcTofEqn_KaTSXR_r_EVM_CalcTofEqn_rt_Array_Float_126_83:0, KaTSXR_r_EVM_CalcTofEqn_KaTSXR_r_EVM_CalcTofEqn_rt_Array_Float_126_84:0, KaTSXR_r_EVM_CalcTofEqn_KaTSXR_r_EVM_CalcTofEqn_rt_Array_Float_126_85:0, KaTSXR_r_EVM_CalcTofEqn_KaTSXR_r_EVM_CalcTofEqn_rt_Array_Float_126_86:0, KaTSXR_r_EVM_CalcTofEqn_KaTSXR_r_EVM_CalcTofEqn_rt_Array_Float_126_87:0, KaTSXR_r_EVM_CalcTofEqn_KaTSXR_r_EVM_CalcTofEqn_rt_Array_Float_126_88:0, KaTSXR_r_EVM_CalcTofEqn_KaTSXR_r_EVM_CalcTofEqn_rt_Array_Float_126_89:0, KaTSXR_r_EVM_CalcTofEqn_KaTSXR_r_EVM_CalcTofEqn_rt_Array_Float_126_90:0, KaTSXR_r_EVM_CalcTofEqn_KaTSXR_r_EVM_CalcTofEqn_rt_Array_Float_126_91:0, KaTSXR_r_EVM_CalcTofEqn_KaTSXR_r_EVM_CalcTofEqn_rt_Array_Float_126_92:0, KaTSXR_r_EVM_CalcTofEqn_KaTSXR_r_EVM_CalcTofEqn_rt_Array_Float_126_93:0, KaTSXR_r_EVM_CalcTofEqn_KaTSXR_r_EVM_CalcTofEqn_rt_Array_Float_126_94:0, KaTSXR_r_EVM_CalcTofEqn_KaTSXR_r_EVM_CalcTofEqn_rt_Array_Float_126_95:0, KaTSXR_r_EVM_CalcTofEqn_KaTSXR_r_EVM_CalcTofEqn_rt_Array_Float_126_96:0, KaTSXR_r_EVM_CalcTofEqn_KaTSXR_r_EVM_CalcTofEqn_rt_Array_Float_126_97:0, KaTSXR_r_EVM_CalcTofEqn_KaTSXR_r_EVM_CalcTofEqn_rt_Array_Float_126_98:0, KaTSXR_r_EVM_CalcTofEqn_KaTSXR_r_EVM_CalcTofEqn_rt_Array_Float_126_99:0, KaTSXR_r_EVM_CalcTofEqn_KaTSXR_r_EVM_CalcTofEqn_rt_Array_Float_126_100:0, KaTSXR_r_EVM_CalcTofEqn_KaTSXR_r_EVM_CalcTofEqn_rt_Array_Float_126_101:0, KaTSXR_r_EVM_CalcTofEqn_KaTSXR_r_EVM_CalcTofEqn_rt_Array_Float_126_102:0, KaTSXR_r_EVM_CalcTofEqn_KaTSXR_r_EVM_CalcTofEqn_rt_Array_Float_126_103:0, KaTSXR_r_EVM_CalcTofEqn_KaTSXR_r_EVM_CalcTofEqn_rt_Array_Float_126_104:0, KaTSXR_r_EVM_CalcTofEqn_KaTSXR_r_EVM_CalcTofEqn_rt_Array_Float_126_105:0, KaTSXR_r_EVM_CalcTofEqn_KaTSXR_r_EVM_CalcTofEqn_rt_Array_Float_126_106:0, KaTSXR_r_EVM_CalcTofEqn_KaTSXR_r_EVM_CalcTofEqn_rt_Array_Float_126_107:0, KaTSXR_r_EVM_CalcTofEqn_KaTSXR_r_EVM_CalcTofEqn_rt_Array_Float_126_108:0, KaTSXR_r_EVM_CalcTofEqn_KaTSXR_r_EVM_CalcTofEqn_rt_Array_Float_126_109:0, KaTSXR_r_EVM_CalcTofEqn_KaTSXR_r_EVM_CalcTofEqn_rt_Array_Float_126_110:0, KaTSXR_r_EVM_CalcTofEqn_KaTSXR_r_EVM_CalcTofEqn_rt_Array_Float_126_111:0, KaTSXR_r_EVM_CalcTofEqn_KaTSXR_r_EVM_CalcTofEqn_rt_Array_Float_126_112:0, KaTSXR_r_EVM_CalcTofEqn_KaTSXR_r_EVM_CalcTofEqn_rt_Array_Float_126_113:0, KaTSXR_r_EVM_CalcTofEqn_KaTSXR_r_EVM_CalcTofEqn_rt_Array_Float_126_114:0, KaTSXR_r_EVM_CalcTofEqn_KaTSXR_r_EVM_CalcTofEqn_rt_Array_Float_126_115:0, KaTSXR_r_EVM_CalcTofEqn_KaTSXR_r_EVM_CalcTofEqn_rt_Array_Float_126_116:0, KaTSXR_r_EVM_CalcTofEqn_KaTSXR_r_EVM_CalcTofEqn_rt_Array_Float_126_117:0, KaTSXR_r_EVM_CalcTofEqn_KaTSXR_r_EVM_CalcTofEqn_rt_Array_Float_126_118:0, KaTSXR_r_EVM_CalcTofEqn_KaTSXR_r_EVM_CalcTofEqn_rt_Array_Float_126_119:0, KaTSXR_r_EVM_CalcTofEqn_KaTSXR_r_EVM_CalcTofEqn_rt_Array_Float_126_120:0, KaTSXR_r_EVM_CalcTofEqn_KaTSXR_r_EVM_CalcTofEqn_rt_Array_Float_126_121:0, KaTSXR_r_EVM_CalcTofEqn_KaTSXR_r_EVM_CalcTofEqn_rt_Array_Float_126_122:0, KaTSXR_r_EVM_CalcTofEqn_KaTSXR_r_EVM_CalcTofEqn_rt_Array_Float_126_123:0, KaTSXR_r_EVM_CalcTofEqn_KaTSXR_r_EVM_CalcTofEqn_rt_Array_Float_126_124:0, KaTSXR_r_EVM_CalcTofEqn_KaTSXR_r_EVM_CalcTofEqn_rt_Array_Float_126_125:0, KaTSXR_r_EVM_CalcTofEqn_KaTSXR_r_EVM_CalcTofEqn_rt_Array_Float_126_126:0], parameter=KaTSXR_r_EVM_CalcTofEqn}, required-interface=KaTSXR_r_EVM_CalcTofEqn
      KaTSXR_r_EVM_CalcTorEqn: parameter-require-com-spec{init-value=KaTSXR_r_EVM_CalcTorEqn_KaTSXR_r_EVM_CalcTorEqn:[KaTSXR_r_EVM_CalcTorEqn_KaTSXR_r_EVM_CalcTorEqn_rt_Array_Float_126_1:0, KaTSXR_r_EVM_CalcTorEqn_KaTSXR_r_EVM_CalcTorEqn_rt_Array_Float_126_2:0, KaTSXR_r_EVM_CalcTorEqn_KaTSXR_r_EVM_CalcTorEqn_rt_Array_Float_126_3:0, KaTSXR_r_EVM_CalcTorEqn_KaTSXR_r_EVM_CalcTorEqn_rt_Array_Float_126_4:0, KaTSXR_r_EVM_CalcTorEqn_KaTSXR_r_EVM_CalcTorEqn_rt_Array_Float_126_5:0, KaTSXR_r_EVM_CalcTorEqn_KaTSXR_r_EVM_CalcTorEqn_rt_Array_Float_126_6:0, KaTSXR_r_EVM_CalcTorEqn_KaTSXR_r_EVM_CalcTorEqn_rt_Array_Float_126_7:0, KaTSXR_r_EVM_CalcTorEqn_KaTSXR_r_EVM_CalcTorEqn_rt_Array_Float_126_8:0, KaTSXR_r_EVM_CalcTorEqn_KaTSXR_r_EVM_CalcTorEqn_rt_Array_Float_126_9:0, KaTSXR_r_EVM_CalcTorEqn_KaTSXR_r_EVM_CalcTorEqn_rt_Array_Float_126_10:0, KaTSXR_r_EVM_CalcTorEqn_KaTSXR_r_EVM_CalcTorEqn_rt_Array_Float_126_11:0, KaTSXR_r_EVM_CalcTorEqn_KaTSXR_r_EVM_CalcTorEqn_rt_Array_Float_126_12:0, KaTSXR_r_EVM_CalcTorEqn_KaTSXR_r_EVM_CalcTorEqn_rt_Array_Float_126_13:0, KaTSXR_r_EVM_CalcTorEqn_KaTSXR_r_EVM_CalcTorEqn_rt_Array_Float_126_14:0, KaTSXR_r_EVM_CalcTorEqn_KaTSXR_r_EVM_CalcTorEqn_rt_Array_Float_126_15:0, KaTSXR_r_EVM_CalcTorEqn_KaTSXR_r_EVM_CalcTorEqn_rt_Array_Float_126_16:0, KaTSXR_r_EVM_CalcTorEqn_KaTSXR_r_EVM_CalcTorEqn_rt_Array_Float_126_17:0, KaTSXR_r_EVM_CalcTorEqn_KaTSXR_r_EVM_CalcTorEqn_rt_Array_Float_126_18:0, KaTSXR_r_EVM_CalcTorEqn_KaTSXR_r_EVM_CalcTorEqn_rt_Array_Float_126_19:0, KaTSXR_r_EVM_CalcTorEqn_KaTSXR_r_EVM_CalcTorEqn_rt_Array_Float_126_20:0, KaTSXR_r_EVM_CalcTorEqn_KaTSXR_r_EVM_CalcTorEqn_rt_Array_Float_126_21:0, KaTSXR_r_EVM_CalcTorEqn_KaTSXR_r_EVM_CalcTorEqn_rt_Array_Float_126_22:0, KaTSXR_r_EVM_CalcTorEqn_KaTSXR_r_EVM_CalcTorEqn_rt_Array_Float_126_23:0, KaTSXR_r_EVM_CalcTorEqn_KaTSXR_r_EVM_CalcTorEqn_rt_Array_Float_126_24:0, KaTSXR_r_EVM_CalcTorEqn_KaTSXR_r_EVM_CalcTorEqn_rt_Array_Float_126_25:0, KaTSXR_r_EVM_CalcTorEqn_KaTSXR_r_EVM_CalcTorEqn_rt_Array_Float_126_26:0, KaTSXR_r_EVM_CalcTorEqn_KaTSXR_r_EVM_CalcTorEqn_rt_Array_Float_126_27:0, KaTSXR_r_EVM_CalcTorEqn_KaTSXR_r_EVM_CalcTorEqn_rt_Array_Float_126_28:0, KaTSXR_r_EVM_CalcTorEqn_KaTSXR_r_EVM_CalcTorEqn_rt_Array_Float_126_29:0, KaTSXR_r_EVM_CalcTorEqn_KaTSXR_r_EVM_CalcTorEqn_rt_Array_Float_126_30:0, KaTSXR_r_EVM_CalcTorEqn_KaTSXR_r_EVM_CalcTorEqn_rt_Array_Float_126_31:0, KaTSXR_r_EVM_CalcTorEqn_KaTSXR_r_EVM_CalcTorEqn_rt_Array_Float_126_32:0, KaTSXR_r_EVM_CalcTorEqn_KaTSXR_r_EVM_CalcTorEqn_rt_Array_Float_126_33:0, KaTSXR_r_EVM_CalcTorEqn_KaTSXR_r_EVM_CalcTorEqn_rt_Array_Float_126_34:0, KaTSXR_r_EVM_CalcTorEqn_KaTSXR_r_EVM_CalcTorEqn_rt_Array_Float_126_35:0, KaTSXR_r_EVM_CalcTorEqn_KaTSXR_r_EVM_CalcTorEqn_rt_Array_Float_126_36:0, KaTSXR_r_EVM_CalcTorEqn_KaTSXR_r_EVM_CalcTorEqn_rt_Array_Float_126_37:0, KaTSXR_r_EVM_CalcTorEqn_KaTSXR_r_EVM_CalcTorEqn_rt_Array_Float_126_38:0, KaTSXR_r_EVM_CalcTorEqn_KaTSXR_r_EVM_CalcTorEqn_rt_Array_Float_126_39:0, KaTSXR_r_EVM_CalcTorEqn_KaTSXR_r_EVM_CalcTorEqn_rt_Array_Float_126_40:0, KaTSXR_r_EVM_CalcTorEqn_KaTSXR_r_EVM_CalcTorEqn_rt_Array_Float_126_41:0, KaTSXR_r_EVM_CalcTorEqn_KaTSXR_r_EVM_CalcTorEqn_rt_Array_Float_126_42:0, KaTSXR_r_EVM_CalcTorEqn_KaTSXR_r_EVM_CalcTorEqn_rt_Array_Float_126_43:0, KaTSXR_r_EVM_CalcTorEqn_KaTSXR_r_EVM_CalcTorEqn_rt_Array_Float_126_44:0, KaTSXR_r_EVM_CalcTorEqn_KaTSXR_r_EVM_CalcTorEqn_rt_Array_Float_126_45:0, KaTSXR_r_EVM_CalcTorEqn_KaTSXR_r_EVM_CalcTorEqn_rt_Array_Float_126_46:0, KaTSXR_r_EVM_CalcTorEqn_KaTSXR_r_EVM_CalcTorEqn_rt_Array_Float_126_47:0, KaTSXR_r_EVM_CalcTorEqn_KaTSXR_r_EVM_CalcTorEqn_rt_Array_Float_126_48:0, KaTSXR_r_EVM_CalcTorEqn_KaTSXR_r_EVM_CalcTorEqn_rt_Array_Float_126_49:0, KaTSXR_r_EVM_CalcTorEqn_KaTSXR_r_EVM_CalcTorEqn_rt_Array_Float_126_50:0, KaTSXR_r_EVM_CalcTorEqn_KaTSXR_r_EVM_CalcTorEqn_rt_Array_Float_126_51:0, KaTSXR_r_EVM_CalcTorEqn_KaTSXR_r_EVM_CalcTorEqn_rt_Array_Float_126_52:0, KaTSXR_r_EVM_CalcTorEqn_KaTSXR_r_EVM_CalcTorEqn_rt_Array_Float_126_53:0, KaTSXR_r_EVM_CalcTorEqn_KaTSXR_r_EVM_CalcTorEqn_rt_Array_Float_126_54:0, KaTSXR_r_EVM_CalcTorEqn_KaTSXR_r_EVM_CalcTorEqn_rt_Array_Float_126_55:0, KaTSXR_r_EVM_CalcTorEqn_KaTSXR_r_EVM_CalcTorEqn_rt_Array_Float_126_56:0, KaTSXR_r_EVM_CalcTorEqn_KaTSXR_r_EVM_CalcTorEqn_rt_Array_Float_126_57:0, KaTSXR_r_EVM_CalcTorEqn_KaTSXR_r_EVM_CalcTorEqn_rt_Array_Float_126_58:0, KaTSXR_r_EVM_CalcTorEqn_KaTSXR_r_EVM_CalcTorEqn_rt_Array_Float_126_59:0, KaTSXR_r_EVM_CalcTorEqn_KaTSXR_r_EVM_CalcTorEqn_rt_Array_Float_126_60:0, KaTSXR_r_EVM_CalcTorEqn_KaTSXR_r_EVM_CalcTorEqn_rt_Array_Float_126_61:0, KaTSXR_r_EVM_CalcTorEqn_KaTSXR_r_EVM_CalcTorEqn_rt_Array_Float_126_62:0, KaTSXR_r_EVM_CalcTorEqn_KaTSXR_r_EVM_CalcTorEqn_rt_Array_Float_126_63:0, KaTSXR_r_EVM_CalcTorEqn_KaTSXR_r_EVM_CalcTorEqn_rt_Array_Float_126_64:0, KaTSXR_r_EVM_CalcTorEqn_KaTSXR_r_EVM_CalcTorEqn_rt_Array_Float_126_65:0, KaTSXR_r_EVM_CalcTorEqn_KaTSXR_r_EVM_CalcTorEqn_rt_Array_Float_126_66:0, KaTSXR_r_EVM_CalcTorEqn_KaTSXR_r_EVM_CalcTorEqn_rt_Array_Float_126_67:0, KaTSXR_r_EVM_CalcTorEqn_KaTSXR_r_EVM_CalcTorEqn_rt_Array_Float_126_68:0, KaTSXR_r_EVM_CalcTorEqn_KaTSXR_r_EVM_CalcTorEqn_rt_Array_Float_126_69:0, KaTSXR_r_EVM_CalcTorEqn_KaTSXR_r_EVM_CalcTorEqn_rt_Array_Float_126_70:0, KaTSXR_r_EVM_CalcTorEqn_KaTSXR_r_EVM_CalcTorEqn_rt_Array_Float_126_71:0, KaTSXR_r_EVM_CalcTorEqn_KaTSXR_r_EVM_CalcTorEqn_rt_Array_Float_126_72:0, KaTSXR_r_EVM_CalcTorEqn_KaTSXR_r_EVM_CalcTorEqn_rt_Array_Float_126_73:0, KaTSXR_r_EVM_CalcTorEqn_KaTSXR_r_EVM_CalcTorEqn_rt_Array_Float_126_74:0, KaTSXR_r_EVM_CalcTorEqn_KaTSXR_r_EVM_CalcTorEqn_rt_Array_Float_126_75:0, KaTSXR_r_EVM_CalcTorEqn_KaTSXR_r_EVM_CalcTorEqn_rt_Array_Float_126_76:0, KaTSXR_r_EVM_CalcTorEqn_KaTSXR_r_EVM_CalcTorEqn_rt_Array_Float_126_77:0, KaTSXR_r_EVM_CalcTorEqn_KaTSXR_r_EVM_CalcTorEqn_rt_Array_Float_126_78:0, KaTSXR_r_EVM_CalcTorEqn_KaTSXR_r_EVM_CalcTorEqn_rt_Array_Float_126_79:0, KaTSXR_r_EVM_CalcTorEqn_KaTSXR_r_EVM_CalcTorEqn_rt_Array_Float_126_80:0, KaTSXR_r_EVM_CalcTorEqn_KaTSXR_r_EVM_CalcTorEqn_rt_Array_Float_126_81:0, KaTSXR_r_EVM_CalcTorEqn_KaTSXR_r_EVM_CalcTorEqn_rt_Array_Float_126_82:0, KaTSXR_r_EVM_CalcTorEqn_KaTSXR_r_EVM_CalcTorEqn_rt_Array_Float_126_83:0, KaTSXR_r_EVM_CalcTorEqn_KaTSXR_r_EVM_CalcTorEqn_rt_Array_Float_126_84:0, KaTSXR_r_EVM_CalcTorEqn_KaTSXR_r_EVM_CalcTorEqn_rt_Array_Float_126_85:0, KaTSXR_r_EVM_CalcTorEqn_KaTSXR_r_EVM_CalcTorEqn_rt_Array_Float_126_86:0, KaTSXR_r_EVM_CalcTorEqn_KaTSXR_r_EVM_CalcTorEqn_rt_Array_Float_126_87:0, KaTSXR_r_EVM_CalcTorEqn_KaTSXR_r_EVM_CalcTorEqn_rt_Array_Float_126_88:0, KaTSXR_r_EVM_CalcTorEqn_KaTSXR_r_EVM_CalcTorEqn_rt_Array_Float_126_89:0, KaTSXR_r_EVM_CalcTorEqn_KaTSXR_r_EVM_CalcTorEqn_rt_Array_Float_126_90:0, KaTSXR_r_EVM_CalcTorEqn_KaTSXR_r_EVM_CalcTorEqn_rt_Array_Float_126_91:0, KaTSXR_r_EVM_CalcTorEqn_KaTSXR_r_EVM_CalcTorEqn_rt_Array_Float_126_92:0, KaTSXR_r_EVM_CalcTorEqn_KaTSXR_r_EVM_CalcTorEqn_rt_Array_Float_126_93:0, KaTSXR_r_EVM_CalcTorEqn_KaTSXR_r_EVM_CalcTorEqn_rt_Array_Float_126_94:0, KaTSXR_r_EVM_CalcTorEqn_KaTSXR_r_EVM_CalcTorEqn_rt_Array_Float_126_95:0, KaTSXR_r_EVM_CalcTorEqn_KaTSXR_r_EVM_CalcTorEqn_rt_Array_Float_126_96:0, KaTSXR_r_EVM_CalcTorEqn_KaTSXR_r_EVM_CalcTorEqn_rt_Array_Float_126_97:0, KaTSXR_r_EVM_CalcTorEqn_KaTSXR_r_EVM_CalcTorEqn_rt_Array_Float_126_98:0, KaTSXR_r_EVM_CalcTorEqn_KaTSXR_r_EVM_CalcTorEqn_rt_Array_Float_126_99:0, KaTSXR_r_EVM_CalcTorEqn_KaTSXR_r_EVM_CalcTorEqn_rt_Array_Float_126_100:0, KaTSXR_r_EVM_CalcTorEqn_KaTSXR_r_EVM_CalcTorEqn_rt_Array_Float_126_101:0, KaTSXR_r_EVM_CalcTorEqn_KaTSXR_r_EVM_CalcTorEqn_rt_Array_Float_126_102:0, KaTSXR_r_EVM_CalcTorEqn_KaTSXR_r_EVM_CalcTorEqn_rt_Array_Float_126_103:0, KaTSXR_r_EVM_CalcTorEqn_KaTSXR_r_EVM_CalcTorEqn_rt_Array_Float_126_104:0, KaTSXR_r_EVM_CalcTorEqn_KaTSXR_r_EVM_CalcTorEqn_rt_Array_Float_126_105:0, KaTSXR_r_EVM_CalcTorEqn_KaTSXR_r_EVM_CalcTorEqn_rt_Array_Float_126_106:0, KaTSXR_r_EVM_CalcTorEqn_KaTSXR_r_EVM_CalcTorEqn_rt_Array_Float_126_107:0, KaTSXR_r_EVM_CalcTorEqn_KaTSXR_r_EVM_CalcTorEqn_rt_Array_Float_126_108:0, KaTSXR_r_EVM_CalcTorEqn_KaTSXR_r_EVM_CalcTorEqn_rt_Array_Float_126_109:0, KaTSXR_r_EVM_CalcTorEqn_KaTSXR_r_EVM_CalcTorEqn_rt_Array_Float_126_110:0, KaTSXR_r_EVM_CalcTorEqn_KaTSXR_r_EVM_CalcTorEqn_rt_Array_Float_126_111:0, KaTSXR_r_EVM_CalcTorEqn_KaTSXR_r_EVM_CalcTorEqn_rt_Array_Float_126_112:0, KaTSXR_r_EVM_CalcTorEqn_KaTSXR_r_EVM_CalcTorEqn_rt_Array_Float_126_113:0, KaTSXR_r_EVM_CalcTorEqn_KaTSXR_r_EVM_CalcTorEqn_rt_Array_Float_126_114:0, KaTSXR_r_EVM_CalcTorEqn_KaTSXR_r_EVM_CalcTorEqn_rt_Array_Float_126_115:0, KaTSXR_r_EVM_CalcTorEqn_KaTSXR_r_EVM_CalcTorEqn_rt_Array_Float_126_116:0, KaTSXR_r_EVM_CalcTorEqn_KaTSXR_r_EVM_CalcTorEqn_rt_Array_Float_126_117:0, KaTSXR_r_EVM_CalcTorEqn_KaTSXR_r_EVM_CalcTorEqn_rt_Array_Float_126_118:0, KaTSXR_r_EVM_CalcTorEqn_KaTSXR_r_EVM_CalcTorEqn_rt_Array_Float_126_119:0, KaTSXR_r_EVM_CalcTorEqn_KaTSXR_r_EVM_CalcTorEqn_rt_Array_Float_126_120:0, KaTSXR_r_EVM_CalcTorEqn_KaTSXR_r_EVM_CalcTorEqn_rt_Array_Float_126_121:0, KaTSXR_r_EVM_CalcTorEqn_KaTSXR_r_EVM_CalcTorEqn_rt_Array_Float_126_122:0, KaTSXR_r_EVM_CalcTorEqn_KaTSXR_r_EVM_CalcTorEqn_rt_Array_Float_126_123:0, KaTSXR_r_EVM_CalcTorEqn_KaTSXR_r_EVM_CalcTorEqn_rt_Array_Float_126_124:0, KaTSXR_r_EVM_CalcTorEqn_KaTSXR_r_EVM_CalcTorEqn_rt_Array_Float_126_125:0, KaTSXR_r_EVM_CalcTorEqn_KaTSXR_r_EVM_CalcTorEqn_rt_Array_Float_126_126:0], parameter=KaTSXR_r_EVM_CalcTorEqn}, required-interface=KaTSXR_r_EVM_CalcTorEqn
      KaTSXR_r_EVM_NaCalcEqnMtrx: parameter-require-com-spec{init-value=KaTSXR_r_EVM_NaCalcEqnMtrx_KaTSXR_r_EVM_NaCalcEqnMtrx:[KaTSXR_r_EVM_NaCalcEqnMtrx_KaTSXR_r_EVM_NaCalcEqnMtrx_rt_Array_Float_27_1:0, KaTSXR_r_EVM_NaCalcEqnMtrx_KaTSXR_r_EVM_NaCalcEqnMtrx_rt_Array_Float_27_2:0, KaTSXR_r_EVM_NaCalcEqnMtrx_KaTSXR_r_EVM_NaCalcEqnMtrx_rt_Array_Float_27_3:0, KaTSXR_r_EVM_NaCalcEqnMtrx_KaTSXR_r_EVM_NaCalcEqnMtrx_rt_Array_Float_27_4:0, KaTSXR_r_EVM_NaCalcEqnMtrx_KaTSXR_r_EVM_NaCalcEqnMtrx_rt_Array_Float_27_5:0, KaTSXR_r_EVM_NaCalcEqnMtrx_KaTSXR_r_EVM_NaCalcEqnMtrx_rt_Array_Float_27_6:0, KaTSXR_r_EVM_NaCalcEqnMtrx_KaTSXR_r_EVM_NaCalcEqnMtrx_rt_Array_Float_27_7:0, KaTSXR_r_EVM_NaCalcEqnMtrx_KaTSXR_r_EVM_NaCalcEqnMtrx_rt_Array_Float_27_8:0, KaTSXR_r_EVM_NaCalcEqnMtrx_KaTSXR_r_EVM_NaCalcEqnMtrx_rt_Array_Float_27_9:0, KaTSXR_r_EVM_NaCalcEqnMtrx_KaTSXR_r_EVM_NaCalcEqnMtrx_rt_Array_Float_27_10:0, KaTSXR_r_EVM_NaCalcEqnMtrx_KaTSXR_r_EVM_NaCalcEqnMtrx_rt_Array_Float_27_11:0, KaTSXR_r_EVM_NaCalcEqnMtrx_KaTSXR_r_EVM_NaCalcEqnMtrx_rt_Array_Float_27_12:0, KaTSXR_r_EVM_NaCalcEqnMtrx_KaTSXR_r_EVM_NaCalcEqnMtrx_rt_Array_Float_27_13:0, KaTSXR_r_EVM_NaCalcEqnMtrx_KaTSXR_r_EVM_NaCalcEqnMtrx_rt_Array_Float_27_14:0, KaTSXR_r_EVM_NaCalcEqnMtrx_KaTSXR_r_EVM_NaCalcEqnMtrx_rt_Array_Float_27_15:0, KaTSXR_r_EVM_NaCalcEqnMtrx_KaTSXR_r_EVM_NaCalcEqnMtrx_rt_Array_Float_27_16:0, KaTSXR_r_EVM_NaCalcEqnMtrx_KaTSXR_r_EVM_NaCalcEqnMtrx_rt_Array_Float_27_17:0, KaTSXR_r_EVM_NaCalcEqnMtrx_KaTSXR_r_EVM_NaCalcEqnMtrx_rt_Array_Float_27_18:0, KaTSXR_r_EVM_NaCalcEqnMtrx_KaTSXR_r_EVM_NaCalcEqnMtrx_rt_Array_Float_27_19:0, KaTSXR_r_EVM_NaCalcEqnMtrx_KaTSXR_r_EVM_NaCalcEqnMtrx_rt_Array_Float_27_20:0, KaTSXR_r_EVM_NaCalcEqnMtrx_KaTSXR_r_EVM_NaCalcEqnMtrx_rt_Array_Float_27_21:0, KaTSXR_r_EVM_NaCalcEqnMtrx_KaTSXR_r_EVM_NaCalcEqnMtrx_rt_Array_Float_27_22:0, KaTSXR_r_EVM_NaCalcEqnMtrx_KaTSXR_r_EVM_NaCalcEqnMtrx_rt_Array_Float_27_23:0, KaTSXR_r_EVM_NaCalcEqnMtrx_KaTSXR_r_EVM_NaCalcEqnMtrx_rt_Array_Float_27_24:0, KaTSXR_r_EVM_NaCalcEqnMtrx_KaTSXR_r_EVM_NaCalcEqnMtrx_rt_Array_Float_27_25:0, KaTSXR_r_EVM_NaCalcEqnMtrx_KaTSXR_r_EVM_NaCalcEqnMtrx_rt_Array_Float_27_26:0, KaTSXR_r_EVM_NaCalcEqnMtrx_KaTSXR_r_EVM_NaCalcEqnMtrx_rt_Array_Float_27_27:0], parameter=KaTSXR_r_EVM_NaCalcEqnMtrx}, required-interface=KaTSXR_r_EVM_NaCalcEqnMtrx
      KaTSXR_r_EVM_NbCalcEqnMtrx: parameter-require-com-spec{init-value=KaTSXR_r_EVM_NbCalcEqnMtrx_KaTSXR_r_EVM_NbCalcEqnMtrx:[KaTSXR_r_EVM_NbCalcEqnMtrx_KaTSXR_r_EVM_NbCalcEqnMtrx_rt_Array_Float_27_1:0, KaTSXR_r_EVM_NbCalcEqnMtrx_KaTSXR_r_EVM_NbCalcEqnMtrx_rt_Array_Float_27_2:0, KaTSXR_r_EVM_NbCalcEqnMtrx_KaTSXR_r_EVM_NbCalcEqnMtrx_rt_Array_Float_27_3:0, KaTSXR_r_EVM_NbCalcEqnMtrx_KaTSXR_r_EVM_NbCalcEqnMtrx_rt_Array_Float_27_4:0, KaTSXR_r_EVM_NbCalcEqnMtrx_KaTSXR_r_EVM_NbCalcEqnMtrx_rt_Array_Float_27_5:0, KaTSXR_r_EVM_NbCalcEqnMtrx_KaTSXR_r_EVM_NbCalcEqnMtrx_rt_Array_Float_27_6:0, KaTSXR_r_EVM_NbCalcEqnMtrx_KaTSXR_r_EVM_NbCalcEqnMtrx_rt_Array_Float_27_7:0, KaTSXR_r_EVM_NbCalcEqnMtrx_KaTSXR_r_EVM_NbCalcEqnMtrx_rt_Array_Float_27_8:0, KaTSXR_r_EVM_NbCalcEqnMtrx_KaTSXR_r_EVM_NbCalcEqnMtrx_rt_Array_Float_27_9:0, KaTSXR_r_EVM_NbCalcEqnMtrx_KaTSXR_r_EVM_NbCalcEqnMtrx_rt_Array_Float_27_10:0, KaTSXR_r_EVM_NbCalcEqnMtrx_KaTSXR_r_EVM_NbCalcEqnMtrx_rt_Array_Float_27_11:0, KaTSXR_r_EVM_NbCalcEqnMtrx_KaTSXR_r_EVM_NbCalcEqnMtrx_rt_Array_Float_27_12:0, KaTSXR_r_EVM_NbCalcEqnMtrx_KaTSXR_r_EVM_NbCalcEqnMtrx_rt_Array_Float_27_13:0, KaTSXR_r_EVM_NbCalcEqnMtrx_KaTSXR_r_EVM_NbCalcEqnMtrx_rt_Array_Float_27_14:0, KaTSXR_r_EVM_NbCalcEqnMtrx_KaTSXR_r_EVM_NbCalcEqnMtrx_rt_Array_Float_27_15:0, KaTSXR_r_EVM_NbCalcEqnMtrx_KaTSXR_r_EVM_NbCalcEqnMtrx_rt_Array_Float_27_16:0, KaTSXR_r_EVM_NbCalcEqnMtrx_KaTSXR_r_EVM_NbCalcEqnMtrx_rt_Array_Float_27_17:0, KaTSXR_r_EVM_NbCalcEqnMtrx_KaTSXR_r_EVM_NbCalcEqnMtrx_rt_Array_Float_27_18:0, KaTSXR_r_EVM_NbCalcEqnMtrx_KaTSXR_r_EVM_NbCalcEqnMtrx_rt_Array_Float_27_19:0, KaTSXR_r_EVM_NbCalcEqnMtrx_KaTSXR_r_EVM_NbCalcEqnMtrx_rt_Array_Float_27_20:0, KaTSXR_r_EVM_NbCalcEqnMtrx_KaTSXR_r_EVM_NbCalcEqnMtrx_rt_Array_Float_27_21:0, KaTSXR_r_EVM_NbCalcEqnMtrx_KaTSXR_r_EVM_NbCalcEqnMtrx_rt_Array_Float_27_22:0, KaTSXR_r_EVM_NbCalcEqnMtrx_KaTSXR_r_EVM_NbCalcEqnMtrx_rt_Array_Float_27_23:0, KaTSXR_r_EVM_NbCalcEqnMtrx_KaTSXR_r_EVM_NbCalcEqnMtrx_rt_Array_Float_27_24:0, KaTSXR_r_EVM_NbCalcEqnMtrx_KaTSXR_r_EVM_NbCalcEqnMtrx_rt_Array_Float_27_25:0, KaTSXR_r_EVM_NbCalcEqnMtrx_KaTSXR_r_EVM_NbCalcEqnMtrx_rt_Array_Float_27_26:0, KaTSXR_r_EVM_NbCalcEqnMtrx_KaTSXR_r_EVM_NbCalcEqnMtrx_rt_Array_Float_27_27:0], parameter=KaTSXR_r_EVM_NbCalcEqnMtrx}, required-interface=KaTSXR_r_EVM_NbCalcEqnMtrx
      KaTSXR_r_EVM_Nc1CalcEqnMtrx: parameter-require-com-spec{init-value=KaTSXR_r_EVM_Nc1CalcEqnMtrx_KaTSXR_r_EVM_Nc1CalcEqnMtrx:[KaTSXR_r_EVM_Nc1CalcEqnMtrx_KaTSXR_r_EVM_Nc1CalcEqnMtrx_rt_Array_Float_27_1:0, KaTSXR_r_EVM_Nc1CalcEqnMtrx_KaTSXR_r_EVM_Nc1CalcEqnMtrx_rt_Array_Float_27_2:0, KaTSXR_r_EVM_Nc1CalcEqnMtrx_KaTSXR_r_EVM_Nc1CalcEqnMtrx_rt_Array_Float_27_3:0, KaTSXR_r_EVM_Nc1CalcEqnMtrx_KaTSXR_r_EVM_Nc1CalcEqnMtrx_rt_Array_Float_27_4:0, KaTSXR_r_EVM_Nc1CalcEqnMtrx_KaTSXR_r_EVM_Nc1CalcEqnMtrx_rt_Array_Float_27_5:0, KaTSXR_r_EVM_Nc1CalcEqnMtrx_KaTSXR_r_EVM_Nc1CalcEqnMtrx_rt_Array_Float_27_6:0, KaTSXR_r_EVM_Nc1CalcEqnMtrx_KaTSXR_r_EVM_Nc1CalcEqnMtrx_rt_Array_Float_27_7:0, KaTSXR_r_EVM_Nc1CalcEqnMtrx_KaTSXR_r_EVM_Nc1CalcEqnMtrx_rt_Array_Float_27_8:0, KaTSXR_r_EVM_Nc1CalcEqnMtrx_KaTSXR_r_EVM_Nc1CalcEqnMtrx_rt_Array_Float_27_9:0, KaTSXR_r_EVM_Nc1CalcEqnMtrx_KaTSXR_r_EVM_Nc1CalcEqnMtrx_rt_Array_Float_27_10:0, KaTSXR_r_EVM_Nc1CalcEqnMtrx_KaTSXR_r_EVM_Nc1CalcEqnMtrx_rt_Array_Float_27_11:0, KaTSXR_r_EVM_Nc1CalcEqnMtrx_KaTSXR_r_EVM_Nc1CalcEqnMtrx_rt_Array_Float_27_12:0, KaTSXR_r_EVM_Nc1CalcEqnMtrx_KaTSXR_r_EVM_Nc1CalcEqnMtrx_rt_Array_Float_27_13:0, KaTSXR_r_EVM_Nc1CalcEqnMtrx_KaTSXR_r_EVM_Nc1CalcEqnMtrx_rt_Array_Float_27_14:0, KaTSXR_r_EVM_Nc1CalcEqnMtrx_KaTSXR_r_EVM_Nc1CalcEqnMtrx_rt_Array_Float_27_15:0, KaTSXR_r_EVM_Nc1CalcEqnMtrx_KaTSXR_r_EVM_Nc1CalcEqnMtrx_rt_Array_Float_27_16:0, KaTSXR_r_EVM_Nc1CalcEqnMtrx_KaTSXR_r_EVM_Nc1CalcEqnMtrx_rt_Array_Float_27_17:0, KaTSXR_r_EVM_Nc1CalcEqnMtrx_KaTSXR_r_EVM_Nc1CalcEqnMtrx_rt_Array_Float_27_18:0, KaTSXR_r_EVM_Nc1CalcEqnMtrx_KaTSXR_r_EVM_Nc1CalcEqnMtrx_rt_Array_Float_27_19:0, KaTSXR_r_EVM_Nc1CalcEqnMtrx_KaTSXR_r_EVM_Nc1CalcEqnMtrx_rt_Array_Float_27_20:0, KaTSXR_r_EVM_Nc1CalcEqnMtrx_KaTSXR_r_EVM_Nc1CalcEqnMtrx_rt_Array_Float_27_21:0, KaTSXR_r_EVM_Nc1CalcEqnMtrx_KaTSXR_r_EVM_Nc1CalcEqnMtrx_rt_Array_Float_27_22:0, KaTSXR_r_EVM_Nc1CalcEqnMtrx_KaTSXR_r_EVM_Nc1CalcEqnMtrx_rt_Array_Float_27_23:0, KaTSXR_r_EVM_Nc1CalcEqnMtrx_KaTSXR_r_EVM_Nc1CalcEqnMtrx_rt_Array_Float_27_24:0, KaTSXR_r_EVM_Nc1CalcEqnMtrx_KaTSXR_r_EVM_Nc1CalcEqnMtrx_rt_Array_Float_27_25:0, KaTSXR_r_EVM_Nc1CalcEqnMtrx_KaTSXR_r_EVM_Nc1CalcEqnMtrx_rt_Array_Float_27_26:0, KaTSXR_r_EVM_Nc1CalcEqnMtrx_KaTSXR_r_EVM_Nc1CalcEqnMtrx_rt_Array_Float_27_27:0], parameter=KaTSXR_r_EVM_Nc1CalcEqnMtrx}, required-interface=KaTSXR_r_EVM_Nc1CalcEqnMtrx
      KaTSXR_r_EVM_Nc2CalcEqnMtrx: parameter-require-com-spec{init-value=KaTSXR_r_EVM_Nc2CalcEqnMtrx_KaTSXR_r_EVM_Nc2CalcEqnMtrx:[KaTSXR_r_EVM_Nc2CalcEqnMtrx_KaTSXR_r_EVM_Nc2CalcEqnMtrx_rt_Array_Float_27_1:0, KaTSXR_r_EVM_Nc2CalcEqnMtrx_KaTSXR_r_EVM_Nc2CalcEqnMtrx_rt_Array_Float_27_2:0, KaTSXR_r_EVM_Nc2CalcEqnMtrx_KaTSXR_r_EVM_Nc2CalcEqnMtrx_rt_Array_Float_27_3:0, KaTSXR_r_EVM_Nc2CalcEqnMtrx_KaTSXR_r_EVM_Nc2CalcEqnMtrx_rt_Array_Float_27_4:0, KaTSXR_r_EVM_Nc2CalcEqnMtrx_KaTSXR_r_EVM_Nc2CalcEqnMtrx_rt_Array_Float_27_5:0, KaTSXR_r_EVM_Nc2CalcEqnMtrx_KaTSXR_r_EVM_Nc2CalcEqnMtrx_rt_Array_Float_27_6:0, KaTSXR_r_EVM_Nc2CalcEqnMtrx_KaTSXR_r_EVM_Nc2CalcEqnMtrx_rt_Array_Float_27_7:0, KaTSXR_r_EVM_Nc2CalcEqnMtrx_KaTSXR_r_EVM_Nc2CalcEqnMtrx_rt_Array_Float_27_8:0, KaTSXR_r_EVM_Nc2CalcEqnMtrx_KaTSXR_r_EVM_Nc2CalcEqnMtrx_rt_Array_Float_27_9:0, KaTSXR_r_EVM_Nc2CalcEqnMtrx_KaTSXR_r_EVM_Nc2CalcEqnMtrx_rt_Array_Float_27_10:0, KaTSXR_r_EVM_Nc2CalcEqnMtrx_KaTSXR_r_EVM_Nc2CalcEqnMtrx_rt_Array_Float_27_11:0, KaTSXR_r_EVM_Nc2CalcEqnMtrx_KaTSXR_r_EVM_Nc2CalcEqnMtrx_rt_Array_Float_27_12:0, KaTSXR_r_EVM_Nc2CalcEqnMtrx_KaTSXR_r_EVM_Nc2CalcEqnMtrx_rt_Array_Float_27_13:0, KaTSXR_r_EVM_Nc2CalcEqnMtrx_KaTSXR_r_EVM_Nc2CalcEqnMtrx_rt_Array_Float_27_14:0, KaTSXR_r_EVM_Nc2CalcEqnMtrx_KaTSXR_r_EVM_Nc2CalcEqnMtrx_rt_Array_Float_27_15:0, KaTSXR_r_EVM_Nc2CalcEqnMtrx_KaTSXR_r_EVM_Nc2CalcEqnMtrx_rt_Array_Float_27_16:0, KaTSXR_r_EVM_Nc2CalcEqnMtrx_KaTSXR_r_EVM_Nc2CalcEqnMtrx_rt_Array_Float_27_17:0, KaTSXR_r_EVM_Nc2CalcEqnMtrx_KaTSXR_r_EVM_Nc2CalcEqnMtrx_rt_Array_Float_27_18:0, KaTSXR_r_EVM_Nc2CalcEqnMtrx_KaTSXR_r_EVM_Nc2CalcEqnMtrx_rt_Array_Float_27_19:0, KaTSXR_r_EVM_Nc2CalcEqnMtrx_KaTSXR_r_EVM_Nc2CalcEqnMtrx_rt_Array_Float_27_20:0, KaTSXR_r_EVM_Nc2CalcEqnMtrx_KaTSXR_r_EVM_Nc2CalcEqnMtrx_rt_Array_Float_27_21:0, KaTSXR_r_EVM_Nc2CalcEqnMtrx_KaTSXR_r_EVM_Nc2CalcEqnMtrx_rt_Array_Float_27_22:0, KaTSXR_r_EVM_Nc2CalcEqnMtrx_KaTSXR_r_EVM_Nc2CalcEqnMtrx_rt_Array_Float_27_23:0, KaTSXR_r_EVM_Nc2CalcEqnMtrx_KaTSXR_r_EVM_Nc2CalcEqnMtrx_rt_Array_Float_27_24:0, KaTSXR_r_EVM_Nc2CalcEqnMtrx_KaTSXR_r_EVM_Nc2CalcEqnMtrx_rt_Array_Float_27_25:0, KaTSXR_r_EVM_Nc2CalcEqnMtrx_KaTSXR_r_EVM_Nc2CalcEqnMtrx_rt_Array_Float_27_26:0, KaTSXR_r_EVM_Nc2CalcEqnMtrx_KaTSXR_r_EVM_Nc2CalcEqnMtrx_rt_Array_Float_27_27:0], parameter=KaTSXR_r_EVM_Nc2CalcEqnMtrx}, required-interface=KaTSXR_r_EVM_Nc2CalcEqnMtrx
      KaTSXR_r_EVM_NcCalcEqnMtrx: parameter-require-com-spec{init-value=KaTSXR_r_EVM_NcCalcEqnMtrx_KaTSXR_r_EVM_NcCalcEqnMtrx:[KaTSXR_r_EVM_NcCalcEqnMtrx_KaTSXR_r_EVM_NcCalcEqnMtrx_rt_Array_Float_27_1:0, KaTSXR_r_EVM_NcCalcEqnMtrx_KaTSXR_r_EVM_NcCalcEqnMtrx_rt_Array_Float_27_2:0, KaTSXR_r_EVM_NcCalcEqnMtrx_KaTSXR_r_EVM_NcCalcEqnMtrx_rt_Array_Float_27_3:0, KaTSXR_r_EVM_NcCalcEqnMtrx_KaTSXR_r_EVM_NcCalcEqnMtrx_rt_Array_Float_27_4:0, KaTSXR_r_EVM_NcCalcEqnMtrx_KaTSXR_r_EVM_NcCalcEqnMtrx_rt_Array_Float_27_5:0, KaTSXR_r_EVM_NcCalcEqnMtrx_KaTSXR_r_EVM_NcCalcEqnMtrx_rt_Array_Float_27_6:0, KaTSXR_r_EVM_NcCalcEqnMtrx_KaTSXR_r_EVM_NcCalcEqnMtrx_rt_Array_Float_27_7:0, KaTSXR_r_EVM_NcCalcEqnMtrx_KaTSXR_r_EVM_NcCalcEqnMtrx_rt_Array_Float_27_8:0, KaTSXR_r_EVM_NcCalcEqnMtrx_KaTSXR_r_EVM_NcCalcEqnMtrx_rt_Array_Float_27_9:0, KaTSXR_r_EVM_NcCalcEqnMtrx_KaTSXR_r_EVM_NcCalcEqnMtrx_rt_Array_Float_27_10:0, KaTSXR_r_EVM_NcCalcEqnMtrx_KaTSXR_r_EVM_NcCalcEqnMtrx_rt_Array_Float_27_11:0, KaTSXR_r_EVM_NcCalcEqnMtrx_KaTSXR_r_EVM_NcCalcEqnMtrx_rt_Array_Float_27_12:0, KaTSXR_r_EVM_NcCalcEqnMtrx_KaTSXR_r_EVM_NcCalcEqnMtrx_rt_Array_Float_27_13:0, KaTSXR_r_EVM_NcCalcEqnMtrx_KaTSXR_r_EVM_NcCalcEqnMtrx_rt_Array_Float_27_14:0, KaTSXR_r_EVM_NcCalcEqnMtrx_KaTSXR_r_EVM_NcCalcEqnMtrx_rt_Array_Float_27_15:0, KaTSXR_r_EVM_NcCalcEqnMtrx_KaTSXR_r_EVM_NcCalcEqnMtrx_rt_Array_Float_27_16:0, KaTSXR_r_EVM_NcCalcEqnMtrx_KaTSXR_r_EVM_NcCalcEqnMtrx_rt_Array_Float_27_17:0, KaTSXR_r_EVM_NcCalcEqnMtrx_KaTSXR_r_EVM_NcCalcEqnMtrx_rt_Array_Float_27_18:0, KaTSXR_r_EVM_NcCalcEqnMtrx_KaTSXR_r_EVM_NcCalcEqnMtrx_rt_Array_Float_27_19:0, KaTSXR_r_EVM_NcCalcEqnMtrx_KaTSXR_r_EVM_NcCalcEqnMtrx_rt_Array_Float_27_20:0, KaTSXR_r_EVM_NcCalcEqnMtrx_KaTSXR_r_EVM_NcCalcEqnMtrx_rt_Array_Float_27_21:0, KaTSXR_r_EVM_NcCalcEqnMtrx_KaTSXR_r_EVM_NcCalcEqnMtrx_rt_Array_Float_27_22:0, KaTSXR_r_EVM_NcCalcEqnMtrx_KaTSXR_r_EVM_NcCalcEqnMtrx_rt_Array_Float_27_23:0, KaTSXR_r_EVM_NcCalcEqnMtrx_KaTSXR_r_EVM_NcCalcEqnMtrx_rt_Array_Float_27_24:0, KaTSXR_r_EVM_NcCalcEqnMtrx_KaTSXR_r_EVM_NcCalcEqnMtrx_rt_Array_Float_27_25:0, KaTSXR_r_EVM_NcCalcEqnMtrx_KaTSXR_r_EVM_NcCalcEqnMtrx_rt_Array_Float_27_26:0, KaTSXR_r_EVM_NcCalcEqnMtrx_KaTSXR_r_EVM_NcCalcEqnMtrx_rt_Array_Float_27_27:0], parameter=KaTSXR_r_EVM_NcCalcEqnMtrx}, required-interface=KaTSXR_r_EVM_NcCalcEqnMtrx
      KaTSXR_r_EVM_TM1_DtrmnOptTms: parameter-require-com-spec{init-value=KaTSXR_r_EVM_TM1_DtrmnOptTms_KaTSXR_r_EVM_TM1_DtrmnOptTms:[KaTSXR_r_EVM_TM1_DtrmnOptTms_KaTSXR_r_EVM_TM1_DtrmnOptTms_rt_Array_Float_126_1:0, KaTSXR_r_EVM_TM1_DtrmnOptTms_KaTSXR_r_EVM_TM1_DtrmnOptTms_rt_Array_Float_126_2:0, KaTSXR_r_EVM_TM1_DtrmnOptTms_KaTSXR_r_EVM_TM1_DtrmnOptTms_rt_Array_Float_126_3:0, KaTSXR_r_EVM_TM1_DtrmnOptTms_KaTSXR_r_EVM_TM1_DtrmnOptTms_rt_Array_Float_126_4:0, KaTSXR_r_EVM_TM1_DtrmnOptTms_KaTSXR_r_EVM_TM1_DtrmnOptTms_rt_Array_Float_126_5:0, KaTSXR_r_EVM_TM1_DtrmnOptTms_KaTSXR_r_EVM_TM1_DtrmnOptTms_rt_Array_Float_126_6:0, KaTSXR_r_EVM_TM1_DtrmnOptTms_KaTSXR_r_EVM_TM1_DtrmnOptTms_rt_Array_Float_126_7:0, KaTSXR_r_EVM_TM1_DtrmnOptTms_KaTSXR_r_EVM_TM1_DtrmnOptTms_rt_Array_Float_126_8:0, KaTSXR_r_EVM_TM1_DtrmnOptTms_KaTSXR_r_EVM_TM1_DtrmnOptTms_rt_Array_Float_126_9:0, KaTSXR_r_EVM_TM1_DtrmnOptTms_KaTSXR_r_EVM_TM1_DtrmnOptTms_rt_Array_Float_126_10:0, KaTSXR_r_EVM_TM1_DtrmnOptTms_KaTSXR_r_EVM_TM1_DtrmnOptTms_rt_Array_Float_126_11:0, KaTSXR_r_EVM_TM1_DtrmnOptTms_KaTSXR_r_EVM_TM1_DtrmnOptTms_rt_Array_Float_126_12:0, KaTSXR_r_EVM_TM1_DtrmnOptTms_KaTSXR_r_EVM_TM1_DtrmnOptTms_rt_Array_Float_126_13:0, KaTSXR_r_EVM_TM1_DtrmnOptTms_KaTSXR_r_EVM_TM1_DtrmnOptTms_rt_Array_Float_126_14:0, KaTSXR_r_EVM_TM1_DtrmnOptTms_KaTSXR_r_EVM_TM1_DtrmnOptTms_rt_Array_Float_126_15:0, KaTSXR_r_EVM_TM1_DtrmnOptTms_KaTSXR_r_EVM_TM1_DtrmnOptTms_rt_Array_Float_126_16:0, KaTSXR_r_EVM_TM1_DtrmnOptTms_KaTSXR_r_EVM_TM1_DtrmnOptTms_rt_Array_Float_126_17:0, KaTSXR_r_EVM_TM1_DtrmnOptTms_KaTSXR_r_EVM_TM1_DtrmnOptTms_rt_Array_Float_126_18:0, KaTSXR_r_EVM_TM1_DtrmnOptTms_KaTSXR_r_EVM_TM1_DtrmnOptTms_rt_Array_Float_126_19:0, KaTSXR_r_EVM_TM1_DtrmnOptTms_KaTSXR_r_EVM_TM1_DtrmnOptTms_rt_Array_Float_126_20:0, KaTSXR_r_EVM_TM1_DtrmnOptTms_KaTSXR_r_EVM_TM1_DtrmnOptTms_rt_Array_Float_126_21:0, KaTSXR_r_EVM_TM1_DtrmnOptTms_KaTSXR_r_EVM_TM1_DtrmnOptTms_rt_Array_Float_126_22:0, KaTSXR_r_EVM_TM1_DtrmnOptTms_KaTSXR_r_EVM_TM1_DtrmnOptTms_rt_Array_Float_126_23:0, KaTSXR_r_EVM_TM1_DtrmnOptTms_KaTSXR_r_EVM_TM1_DtrmnOptTms_rt_Array_Float_126_24:0, KaTSXR_r_EVM_TM1_DtrmnOptTms_KaTSXR_r_EVM_TM1_DtrmnOptTms_rt_Array_Float_126_25:0, KaTSXR_r_EVM_TM1_DtrmnOptTms_KaTSXR_r_EVM_TM1_DtrmnOptTms_rt_Array_Float_126_26:0, KaTSXR_r_EVM_TM1_DtrmnOptTms_KaTSXR_r_EVM_TM1_DtrmnOptTms_rt_Array_Float_126_27:0, KaTSXR_r_EVM_TM1_DtrmnOptTms_KaTSXR_r_EVM_TM1_DtrmnOptTms_rt_Array_Float_126_28:0, KaTSXR_r_EVM_TM1_DtrmnOptTms_KaTSXR_r_EVM_TM1_DtrmnOptTms_rt_Array_Float_126_29:0, KaTSXR_r_EVM_TM1_DtrmnOptTms_KaTSXR_r_EVM_TM1_DtrmnOptTms_rt_Array_Float_126_30:0, KaTSXR_r_EVM_TM1_DtrmnOptTms_KaTSXR_r_EVM_TM1_DtrmnOptTms_rt_Array_Float_126_31:0, KaTSXR_r_EVM_TM1_DtrmnOptTms_KaTSXR_r_EVM_TM1_DtrmnOptTms_rt_Array_Float_126_32:0, KaTSXR_r_EVM_TM1_DtrmnOptTms_KaTSXR_r_EVM_TM1_DtrmnOptTms_rt_Array_Float_126_33:0, KaTSXR_r_EVM_TM1_DtrmnOptTms_KaTSXR_r_EVM_TM1_DtrmnOptTms_rt_Array_Float_126_34:0, KaTSXR_r_EVM_TM1_DtrmnOptTms_KaTSXR_r_EVM_TM1_DtrmnOptTms_rt_Array_Float_126_35:0, KaTSXR_r_EVM_TM1_DtrmnOptTms_KaTSXR_r_EVM_TM1_DtrmnOptTms_rt_Array_Float_126_36:0, KaTSXR_r_EVM_TM1_DtrmnOptTms_KaTSXR_r_EVM_TM1_DtrmnOptTms_rt_Array_Float_126_37:0, KaTSXR_r_EVM_TM1_DtrmnOptTms_KaTSXR_r_EVM_TM1_DtrmnOptTms_rt_Array_Float_126_38:0, KaTSXR_r_EVM_TM1_DtrmnOptTms_KaTSXR_r_EVM_TM1_DtrmnOptTms_rt_Array_Float_126_39:0, KaTSXR_r_EVM_TM1_DtrmnOptTms_KaTSXR_r_EVM_TM1_DtrmnOptTms_rt_Array_Float_126_40:0, KaTSXR_r_EVM_TM1_DtrmnOptTms_KaTSXR_r_EVM_TM1_DtrmnOptTms_rt_Array_Float_126_41:0, KaTSXR_r_EVM_TM1_DtrmnOptTms_KaTSXR_r_EVM_TM1_DtrmnOptTms_rt_Array_Float_126_42:0, KaTSXR_r_EVM_TM1_DtrmnOptTms_KaTSXR_r_EVM_TM1_DtrmnOptTms_rt_Array_Float_126_43:0, KaTSXR_r_EVM_TM1_DtrmnOptTms_KaTSXR_r_EVM_TM1_DtrmnOptTms_rt_Array_Float_126_44:0, KaTSXR_r_EVM_TM1_DtrmnOptTms_KaTSXR_r_EVM_TM1_DtrmnOptTms_rt_Array_Float_126_45:0, KaTSXR_r_EVM_TM1_DtrmnOptTms_KaTSXR_r_EVM_TM1_DtrmnOptTms_rt_Array_Float_126_46:0, KaTSXR_r_EVM_TM1_DtrmnOptTms_KaTSXR_r_EVM_TM1_DtrmnOptTms_rt_Array_Float_126_47:0, KaTSXR_r_EVM_TM1_DtrmnOptTms_KaTSXR_r_EVM_TM1_DtrmnOptTms_rt_Array_Float_126_48:0, KaTSXR_r_EVM_TM1_DtrmnOptTms_KaTSXR_r_EVM_TM1_DtrmnOptTms_rt_Array_Float_126_49:0, KaTSXR_r_EVM_TM1_DtrmnOptTms_KaTSXR_r_EVM_TM1_DtrmnOptTms_rt_Array_Float_126_50:0, KaTSXR_r_EVM_TM1_DtrmnOptTms_KaTSXR_r_EVM_TM1_DtrmnOptTms_rt_Array_Float_126_51:0, KaTSXR_r_EVM_TM1_DtrmnOptTms_KaTSXR_r_EVM_TM1_DtrmnOptTms_rt_Array_Float_126_52:0, KaTSXR_r_EVM_TM1_DtrmnOptTms_KaTSXR_r_EVM_TM1_DtrmnOptTms_rt_Array_Float_126_53:0, KaTSXR_r_EVM_TM1_DtrmnOptTms_KaTSXR_r_EVM_TM1_DtrmnOptTms_rt_Array_Float_126_54:0, KaTSXR_r_EVM_TM1_DtrmnOptTms_KaTSXR_r_EVM_TM1_DtrmnOptTms_rt_Array_Float_126_55:0, KaTSXR_r_EVM_TM1_DtrmnOptTms_KaTSXR_r_EVM_TM1_DtrmnOptTms_rt_Array_Float_126_56:0, KaTSXR_r_EVM_TM1_DtrmnOptTms_KaTSXR_r_EVM_TM1_DtrmnOptTms_rt_Array_Float_126_57:0, KaTSXR_r_EVM_TM1_DtrmnOptTms_KaTSXR_r_EVM_TM1_DtrmnOptTms_rt_Array_Float_126_58:0, KaTSXR_r_EVM_TM1_DtrmnOptTms_KaTSXR_r_EVM_TM1_DtrmnOptTms_rt_Array_Float_126_59:0, KaTSXR_r_EVM_TM1_DtrmnOptTms_KaTSXR_r_EVM_TM1_DtrmnOptTms_rt_Array_Float_126_60:0, KaTSXR_r_EVM_TM1_DtrmnOptTms_KaTSXR_r_EVM_TM1_DtrmnOptTms_rt_Array_Float_126_61:0, KaTSXR_r_EVM_TM1_DtrmnOptTms_KaTSXR_r_EVM_TM1_DtrmnOptTms_rt_Array_Float_126_62:0, KaTSXR_r_EVM_TM1_DtrmnOptTms_KaTSXR_r_EVM_TM1_DtrmnOptTms_rt_Array_Float_126_63:0, KaTSXR_r_EVM_TM1_DtrmnOptTms_KaTSXR_r_EVM_TM1_DtrmnOptTms_rt_Array_Float_126_64:0, KaTSXR_r_EVM_TM1_DtrmnOptTms_KaTSXR_r_EVM_TM1_DtrmnOptTms_rt_Array_Float_126_65:0, KaTSXR_r_EVM_TM1_DtrmnOptTms_KaTSXR_r_EVM_TM1_DtrmnOptTms_rt_Array_Float_126_66:0, KaTSXR_r_EVM_TM1_DtrmnOptTms_KaTSXR_r_EVM_TM1_DtrmnOptTms_rt_Array_Float_126_67:0, KaTSXR_r_EVM_TM1_DtrmnOptTms_KaTSXR_r_EVM_TM1_DtrmnOptTms_rt_Array_Float_126_68:0, KaTSXR_r_EVM_TM1_DtrmnOptTms_KaTSXR_r_EVM_TM1_DtrmnOptTms_rt_Array_Float_126_69:0, KaTSXR_r_EVM_TM1_DtrmnOptTms_KaTSXR_r_EVM_TM1_DtrmnOptTms_rt_Array_Float_126_70:0, KaTSXR_r_EVM_TM1_DtrmnOptTms_KaTSXR_r_EVM_TM1_DtrmnOptTms_rt_Array_Float_126_71:0, KaTSXR_r_EVM_TM1_DtrmnOptTms_KaTSXR_r_EVM_TM1_DtrmnOptTms_rt_Array_Float_126_72:0, KaTSXR_r_EVM_TM1_DtrmnOptTms_KaTSXR_r_EVM_TM1_DtrmnOptTms_rt_Array_Float_126_73:0, KaTSXR_r_EVM_TM1_DtrmnOptTms_KaTSXR_r_EVM_TM1_DtrmnOptTms_rt_Array_Float_126_74:0, KaTSXR_r_EVM_TM1_DtrmnOptTms_KaTSXR_r_EVM_TM1_DtrmnOptTms_rt_Array_Float_126_75:0, KaTSXR_r_EVM_TM1_DtrmnOptTms_KaTSXR_r_EVM_TM1_DtrmnOptTms_rt_Array_Float_126_76:0, KaTSXR_r_EVM_TM1_DtrmnOptTms_KaTSXR_r_EVM_TM1_DtrmnOptTms_rt_Array_Float_126_77:0, KaTSXR_r_EVM_TM1_DtrmnOptTms_KaTSXR_r_EVM_TM1_DtrmnOptTms_rt_Array_Float_126_78:0, KaTSXR_r_EVM_TM1_DtrmnOptTms_KaTSXR_r_EVM_TM1_DtrmnOptTms_rt_Array_Float_126_79:0, KaTSXR_r_EVM_TM1_DtrmnOptTms_KaTSXR_r_EVM_TM1_DtrmnOptTms_rt_Array_Float_126_80:0, KaTSXR_r_EVM_TM1_DtrmnOptTms_KaTSXR_r_EVM_TM1_DtrmnOptTms_rt_Array_Float_126_81:0, KaTSXR_r_EVM_TM1_DtrmnOptTms_KaTSXR_r_EVM_TM1_DtrmnOptTms_rt_Array_Float_126_82:0, KaTSXR_r_EVM_TM1_DtrmnOptTms_KaTSXR_r_EVM_TM1_DtrmnOptTms_rt_Array_Float_126_83:0, KaTSXR_r_EVM_TM1_DtrmnOptTms_KaTSXR_r_EVM_TM1_DtrmnOptTms_rt_Array_Float_126_84:0, KaTSXR_r_EVM_TM1_DtrmnOptTms_KaTSXR_r_EVM_TM1_DtrmnOptTms_rt_Array_Float_126_85:0, KaTSXR_r_EVM_TM1_DtrmnOptTms_KaTSXR_r_EVM_TM1_DtrmnOptTms_rt_Array_Float_126_86:0, KaTSXR_r_EVM_TM1_DtrmnOptTms_KaTSXR_r_EVM_TM1_DtrmnOptTms_rt_Array_Float_126_87:0, KaTSXR_r_EVM_TM1_DtrmnOptTms_KaTSXR_r_EVM_TM1_DtrmnOptTms_rt_Array_Float_126_88:0, KaTSXR_r_EVM_TM1_DtrmnOptTms_KaTSXR_r_EVM_TM1_DtrmnOptTms_rt_Array_Float_126_89:0, KaTSXR_r_EVM_TM1_DtrmnOptTms_KaTSXR_r_EVM_TM1_DtrmnOptTms_rt_Array_Float_126_90:0, KaTSXR_r_EVM_TM1_DtrmnOptTms_KaTSXR_r_EVM_TM1_DtrmnOptTms_rt_Array_Float_126_91:0, KaTSXR_r_EVM_TM1_DtrmnOptTms_KaTSXR_r_EVM_TM1_DtrmnOptTms_rt_Array_Float_126_92:0, KaTSXR_r_EVM_TM1_DtrmnOptTms_KaTSXR_r_EVM_TM1_DtrmnOptTms_rt_Array_Float_126_93:0, KaTSXR_r_EVM_TM1_DtrmnOptTms_KaTSXR_r_EVM_TM1_DtrmnOptTms_rt_Array_Float_126_94:0, KaTSXR_r_EVM_TM1_DtrmnOptTms_KaTSXR_r_EVM_TM1_DtrmnOptTms_rt_Array_Float_126_95:0, KaTSXR_r_EVM_TM1_DtrmnOptTms_KaTSXR_r_EVM_TM1_DtrmnOptTms_rt_Array_Float_126_96:0, KaTSXR_r_EVM_TM1_DtrmnOptTms_KaTSXR_r_EVM_TM1_DtrmnOptTms_rt_Array_Float_126_97:0, KaTSXR_r_EVM_TM1_DtrmnOptTms_KaTSXR_r_EVM_TM1_DtrmnOptTms_rt_Array_Float_126_98:0, KaTSXR_r_EVM_TM1_DtrmnOptTms_KaTSXR_r_EVM_TM1_DtrmnOptTms_rt_Array_Float_126_99:0, KaTSXR_r_EVM_TM1_DtrmnOptTms_KaTSXR_r_EVM_TM1_DtrmnOptTms_rt_Array_Float_126_100:0, KaTSXR_r_EVM_TM1_DtrmnOptTms_KaTSXR_r_EVM_TM1_DtrmnOptTms_rt_Array_Float_126_101:0, KaTSXR_r_EVM_TM1_DtrmnOptTms_KaTSXR_r_EVM_TM1_DtrmnOptTms_rt_Array_Float_126_102:0, KaTSXR_r_EVM_TM1_DtrmnOptTms_KaTSXR_r_EVM_TM1_DtrmnOptTms_rt_Array_Float_126_103:0, KaTSXR_r_EVM_TM1_DtrmnOptTms_KaTSXR_r_EVM_TM1_DtrmnOptTms_rt_Array_Float_126_104:0, KaTSXR_r_EVM_TM1_DtrmnOptTms_KaTSXR_r_EVM_TM1_DtrmnOptTms_rt_Array_Float_126_105:0, KaTSXR_r_EVM_TM1_DtrmnOptTms_KaTSXR_r_EVM_TM1_DtrmnOptTms_rt_Array_Float_126_106:0, KaTSXR_r_EVM_TM1_DtrmnOptTms_KaTSXR_r_EVM_TM1_DtrmnOptTms_rt_Array_Float_126_107:0, KaTSXR_r_EVM_TM1_DtrmnOptTms_KaTSXR_r_EVM_TM1_DtrmnOptTms_rt_Array_Float_126_108:0, KaTSXR_r_EVM_TM1_DtrmnOptTms_KaTSXR_r_EVM_TM1_DtrmnOptTms_rt_Array_Float_126_109:0, KaTSXR_r_EVM_TM1_DtrmnOptTms_KaTSXR_r_EVM_TM1_DtrmnOptTms_rt_Array_Float_126_110:0, KaTSXR_r_EVM_TM1_DtrmnOptTms_KaTSXR_r_EVM_TM1_DtrmnOptTms_rt_Array_Float_126_111:0, KaTSXR_r_EVM_TM1_DtrmnOptTms_KaTSXR_r_EVM_TM1_DtrmnOptTms_rt_Array_Float_126_112:0, KaTSXR_r_EVM_TM1_DtrmnOptTms_KaTSXR_r_EVM_TM1_DtrmnOptTms_rt_Array_Float_126_113:0, KaTSXR_r_EVM_TM1_DtrmnOptTms_KaTSXR_r_EVM_TM1_DtrmnOptTms_rt_Array_Float_126_114:0, KaTSXR_r_EVM_TM1_DtrmnOptTms_KaTSXR_r_EVM_TM1_DtrmnOptTms_rt_Array_Float_126_115:0, KaTSXR_r_EVM_TM1_DtrmnOptTms_KaTSXR_r_EVM_TM1_DtrmnOptTms_rt_Array_Float_126_116:0, KaTSXR_r_EVM_TM1_DtrmnOptTms_KaTSXR_r_EVM_TM1_DtrmnOptTms_rt_Array_Float_126_117:0, KaTSXR_r_EVM_TM1_DtrmnOptTms_KaTSXR_r_EVM_TM1_DtrmnOptTms_rt_Array_Float_126_118:0, KaTSXR_r_EVM_TM1_DtrmnOptTms_KaTSXR_r_EVM_TM1_DtrmnOptTms_rt_Array_Float_126_119:0, KaTSXR_r_EVM_TM1_DtrmnOptTms_KaTSXR_r_EVM_TM1_DtrmnOptTms_rt_Array_Float_126_120:0, KaTSXR_r_EVM_TM1_DtrmnOptTms_KaTSXR_r_EVM_TM1_DtrmnOptTms_rt_Array_Float_126_121:0, KaTSXR_r_EVM_TM1_DtrmnOptTms_KaTSXR_r_EVM_TM1_DtrmnOptTms_rt_Array_Float_126_122:0, KaTSXR_r_EVM_TM1_DtrmnOptTms_KaTSXR_r_EVM_TM1_DtrmnOptTms_rt_Array_Float_126_123:0, KaTSXR_r_EVM_TM1_DtrmnOptTms_KaTSXR_r_EVM_TM1_DtrmnOptTms_rt_Array_Float_126_124:0, KaTSXR_r_EVM_TM1_DtrmnOptTms_KaTSXR_r_EVM_TM1_DtrmnOptTms_rt_Array_Float_126_125:0, KaTSXR_r_EVM_TM1_DtrmnOptTms_KaTSXR_r_EVM_TM1_DtrmnOptTms_rt_Array_Float_126_126:0], parameter=KaTSXR_r_EVM_TM1_DtrmnOptTms}, required-interface=KaTSXR_r_EVM_TM1_DtrmnOptTms
      KaTSXR_r_EVM_TM1_TiConstrn: parameter-require-com-spec{init-value=KaTSXR_r_EVM_TM1_TiConstrn_KaTSXR_r_EVM_TM1_TiConstrn:[KaTSXR_r_EVM_TM1_TiConstrn_KaTSXR_r_EVM_TM1_TiConstrn_rt_Array_Float_126_1:0, KaTSXR_r_EVM_TM1_TiConstrn_KaTSXR_r_EVM_TM1_TiConstrn_rt_Array_Float_126_2:0, KaTSXR_r_EVM_TM1_TiConstrn_KaTSXR_r_EVM_TM1_TiConstrn_rt_Array_Float_126_3:0, KaTSXR_r_EVM_TM1_TiConstrn_KaTSXR_r_EVM_TM1_TiConstrn_rt_Array_Float_126_4:0, KaTSXR_r_EVM_TM1_TiConstrn_KaTSXR_r_EVM_TM1_TiConstrn_rt_Array_Float_126_5:0, KaTSXR_r_EVM_TM1_TiConstrn_KaTSXR_r_EVM_TM1_TiConstrn_rt_Array_Float_126_6:0, KaTSXR_r_EVM_TM1_TiConstrn_KaTSXR_r_EVM_TM1_TiConstrn_rt_Array_Float_126_7:0, KaTSXR_r_EVM_TM1_TiConstrn_KaTSXR_r_EVM_TM1_TiConstrn_rt_Array_Float_126_8:0, KaTSXR_r_EVM_TM1_TiConstrn_KaTSXR_r_EVM_TM1_TiConstrn_rt_Array_Float_126_9:0, KaTSXR_r_EVM_TM1_TiConstrn_KaTSXR_r_EVM_TM1_TiConstrn_rt_Array_Float_126_10:0, KaTSXR_r_EVM_TM1_TiConstrn_KaTSXR_r_EVM_TM1_TiConstrn_rt_Array_Float_126_11:0, KaTSXR_r_EVM_TM1_TiConstrn_KaTSXR_r_EVM_TM1_TiConstrn_rt_Array_Float_126_12:0, KaTSXR_r_EVM_TM1_TiConstrn_KaTSXR_r_EVM_TM1_TiConstrn_rt_Array_Float_126_13:0, KaTSXR_r_EVM_TM1_TiConstrn_KaTSXR_r_EVM_TM1_TiConstrn_rt_Array_Float_126_14:0, KaTSXR_r_EVM_TM1_TiConstrn_KaTSXR_r_EVM_TM1_TiConstrn_rt_Array_Float_126_15:0, KaTSXR_r_EVM_TM1_TiConstrn_KaTSXR_r_EVM_TM1_TiConstrn_rt_Array_Float_126_16:0, KaTSXR_r_EVM_TM1_TiConstrn_KaTSXR_r_EVM_TM1_TiConstrn_rt_Array_Float_126_17:0, KaTSXR_r_EVM_TM1_TiConstrn_KaTSXR_r_EVM_TM1_TiConstrn_rt_Array_Float_126_18:0, KaTSXR_r_EVM_TM1_TiConstrn_KaTSXR_r_EVM_TM1_TiConstrn_rt_Array_Float_126_19:0, KaTSXR_r_EVM_TM1_TiConstrn_KaTSXR_r_EVM_TM1_TiConstrn_rt_Array_Float_126_20:0, KaTSXR_r_EVM_TM1_TiConstrn_KaTSXR_r_EVM_TM1_TiConstrn_rt_Array_Float_126_21:0, KaTSXR_r_EVM_TM1_TiConstrn_KaTSXR_r_EVM_TM1_TiConstrn_rt_Array_Float_126_22:0, KaTSXR_r_EVM_TM1_TiConstrn_KaTSXR_r_EVM_TM1_TiConstrn_rt_Array_Float_126_23:0, KaTSXR_r_EVM_TM1_TiConstrn_KaTSXR_r_EVM_TM1_TiConstrn_rt_Array_Float_126_24:0, KaTSXR_r_EVM_TM1_TiConstrn_KaTSXR_r_EVM_TM1_TiConstrn_rt_Array_Float_126_25:0, KaTSXR_r_EVM_TM1_TiConstrn_KaTSXR_r_EVM_TM1_TiConstrn_rt_Array_Float_126_26:0, KaTSXR_r_EVM_TM1_TiConstrn_KaTSXR_r_EVM_TM1_TiConstrn_rt_Array_Float_126_27:0, KaTSXR_r_EVM_TM1_TiConstrn_KaTSXR_r_EVM_TM1_TiConstrn_rt_Array_Float_126_28:0, KaTSXR_r_EVM_TM1_TiConstrn_KaTSXR_r_EVM_TM1_TiConstrn_rt_Array_Float_126_29:0, KaTSXR_r_EVM_TM1_TiConstrn_KaTSXR_r_EVM_TM1_TiConstrn_rt_Array_Float_126_30:0, KaTSXR_r_EVM_TM1_TiConstrn_KaTSXR_r_EVM_TM1_TiConstrn_rt_Array_Float_126_31:0, KaTSXR_r_EVM_TM1_TiConstrn_KaTSXR_r_EVM_TM1_TiConstrn_rt_Array_Float_126_32:0, KaTSXR_r_EVM_TM1_TiConstrn_KaTSXR_r_EVM_TM1_TiConstrn_rt_Array_Float_126_33:0, KaTSXR_r_EVM_TM1_TiConstrn_KaTSXR_r_EVM_TM1_TiConstrn_rt_Array_Float_126_34:0, KaTSXR_r_EVM_TM1_TiConstrn_KaTSXR_r_EVM_TM1_TiConstrn_rt_Array_Float_126_35:0, KaTSXR_r_EVM_TM1_TiConstrn_KaTSXR_r_EVM_TM1_TiConstrn_rt_Array_Float_126_36:0, KaTSXR_r_EVM_TM1_TiConstrn_KaTSXR_r_EVM_TM1_TiConstrn_rt_Array_Float_126_37:0, KaTSXR_r_EVM_TM1_TiConstrn_KaTSXR_r_EVM_TM1_TiConstrn_rt_Array_Float_126_38:0, KaTSXR_r_EVM_TM1_TiConstrn_KaTSXR_r_EVM_TM1_TiConstrn_rt_Array_Float_126_39:0, KaTSXR_r_EVM_TM1_TiConstrn_KaTSXR_r_EVM_TM1_TiConstrn_rt_Array_Float_126_40:0, KaTSXR_r_EVM_TM1_TiConstrn_KaTSXR_r_EVM_TM1_TiConstrn_rt_Array_Float_126_41:0, KaTSXR_r_EVM_TM1_TiConstrn_KaTSXR_r_EVM_TM1_TiConstrn_rt_Array_Float_126_42:0, KaTSXR_r_EVM_TM1_TiConstrn_KaTSXR_r_EVM_TM1_TiConstrn_rt_Array_Float_126_43:0, KaTSXR_r_EVM_TM1_TiConstrn_KaTSXR_r_EVM_TM1_TiConstrn_rt_Array_Float_126_44:0, KaTSXR_r_EVM_TM1_TiConstrn_KaTSXR_r_EVM_TM1_TiConstrn_rt_Array_Float_126_45:0, KaTSXR_r_EVM_TM1_TiConstrn_KaTSXR_r_EVM_TM1_TiConstrn_rt_Array_Float_126_46:0, KaTSXR_r_EVM_TM1_TiConstrn_KaTSXR_r_EVM_TM1_TiConstrn_rt_Array_Float_126_47:0, KaTSXR_r_EVM_TM1_TiConstrn_KaTSXR_r_EVM_TM1_TiConstrn_rt_Array_Float_126_48:0, KaTSXR_r_EVM_TM1_TiConstrn_KaTSXR_r_EVM_TM1_TiConstrn_rt_Array_Float_126_49:0, KaTSXR_r_EVM_TM1_TiConstrn_KaTSXR_r_EVM_TM1_TiConstrn_rt_Array_Float_126_50:0, KaTSXR_r_EVM_TM1_TiConstrn_KaTSXR_r_EVM_TM1_TiConstrn_rt_Array_Float_126_51:0, KaTSXR_r_EVM_TM1_TiConstrn_KaTSXR_r_EVM_TM1_TiConstrn_rt_Array_Float_126_52:0, KaTSXR_r_EVM_TM1_TiConstrn_KaTSXR_r_EVM_TM1_TiConstrn_rt_Array_Float_126_53:0, KaTSXR_r_EVM_TM1_TiConstrn_KaTSXR_r_EVM_TM1_TiConstrn_rt_Array_Float_126_54:0, KaTSXR_r_EVM_TM1_TiConstrn_KaTSXR_r_EVM_TM1_TiConstrn_rt_Array_Float_126_55:0, KaTSXR_r_EVM_TM1_TiConstrn_KaTSXR_r_EVM_TM1_TiConstrn_rt_Array_Float_126_56:0, KaTSXR_r_EVM_TM1_TiConstrn_KaTSXR_r_EVM_TM1_TiConstrn_rt_Array_Float_126_57:0, KaTSXR_r_EVM_TM1_TiConstrn_KaTSXR_r_EVM_TM1_TiConstrn_rt_Array_Float_126_58:0, KaTSXR_r_EVM_TM1_TiConstrn_KaTSXR_r_EVM_TM1_TiConstrn_rt_Array_Float_126_59:0, KaTSXR_r_EVM_TM1_TiConstrn_KaTSXR_r_EVM_TM1_TiConstrn_rt_Array_Float_126_60:0, KaTSXR_r_EVM_TM1_TiConstrn_KaTSXR_r_EVM_TM1_TiConstrn_rt_Array_Float_126_61:0, KaTSXR_r_EVM_TM1_TiConstrn_KaTSXR_r_EVM_TM1_TiConstrn_rt_Array_Float_126_62:0, KaTSXR_r_EVM_TM1_TiConstrn_KaTSXR_r_EVM_TM1_TiConstrn_rt_Array_Float_126_63:0, KaTSXR_r_EVM_TM1_TiConstrn_KaTSXR_r_EVM_TM1_TiConstrn_rt_Array_Float_126_64:0, KaTSXR_r_EVM_TM1_TiConstrn_KaTSXR_r_EVM_TM1_TiConstrn_rt_Array_Float_126_65:0, KaTSXR_r_EVM_TM1_TiConstrn_KaTSXR_r_EVM_TM1_TiConstrn_rt_Array_Float_126_66:0, KaTSXR_r_EVM_TM1_TiConstrn_KaTSXR_r_EVM_TM1_TiConstrn_rt_Array_Float_126_67:0, KaTSXR_r_EVM_TM1_TiConstrn_KaTSXR_r_EVM_TM1_TiConstrn_rt_Array_Float_126_68:0, KaTSXR_r_EVM_TM1_TiConstrn_KaTSXR_r_EVM_TM1_TiConstrn_rt_Array_Float_126_69:0, KaTSXR_r_EVM_TM1_TiConstrn_KaTSXR_r_EVM_TM1_TiConstrn_rt_Array_Float_126_70:0, KaTSXR_r_EVM_TM1_TiConstrn_KaTSXR_r_EVM_TM1_TiConstrn_rt_Array_Float_126_71:0, KaTSXR_r_EVM_TM1_TiConstrn_KaTSXR_r_EVM_TM1_TiConstrn_rt_Array_Float_126_72:0, KaTSXR_r_EVM_TM1_TiConstrn_KaTSXR_r_EVM_TM1_TiConstrn_rt_Array_Float_126_73:0, KaTSXR_r_EVM_TM1_TiConstrn_KaTSXR_r_EVM_TM1_TiConstrn_rt_Array_Float_126_74:0, KaTSXR_r_EVM_TM1_TiConstrn_KaTSXR_r_EVM_TM1_TiConstrn_rt_Array_Float_126_75:0, KaTSXR_r_EVM_TM1_TiConstrn_KaTSXR_r_EVM_TM1_TiConstrn_rt_Array_Float_126_76:0, KaTSXR_r_EVM_TM1_TiConstrn_KaTSXR_r_EVM_TM1_TiConstrn_rt_Array_Float_126_77:0, KaTSXR_r_EVM_TM1_TiConstrn_KaTSXR_r_EVM_TM1_TiConstrn_rt_Array_Float_126_78:0, KaTSXR_r_EVM_TM1_TiConstrn_KaTSXR_r_EVM_TM1_TiConstrn_rt_Array_Float_126_79:0, KaTSXR_r_EVM_TM1_TiConstrn_KaTSXR_r_EVM_TM1_TiConstrn_rt_Array_Float_126_80:0, KaTSXR_r_EVM_TM1_TiConstrn_KaTSXR_r_EVM_TM1_TiConstrn_rt_Array_Float_126_81:0, KaTSXR_r_EVM_TM1_TiConstrn_KaTSXR_r_EVM_TM1_TiConstrn_rt_Array_Float_126_82:0, KaTSXR_r_EVM_TM1_TiConstrn_KaTSXR_r_EVM_TM1_TiConstrn_rt_Array_Float_126_83:0, KaTSXR_r_EVM_TM1_TiConstrn_KaTSXR_r_EVM_TM1_TiConstrn_rt_Array_Float_126_84:0, KaTSXR_r_EVM_TM1_TiConstrn_KaTSXR_r_EVM_TM1_TiConstrn_rt_Array_Float_126_85:0, KaTSXR_r_EVM_TM1_TiConstrn_KaTSXR_r_EVM_TM1_TiConstrn_rt_Array_Float_126_86:0, KaTSXR_r_EVM_TM1_TiConstrn_KaTSXR_r_EVM_TM1_TiConstrn_rt_Array_Float_126_87:0, KaTSXR_r_EVM_TM1_TiConstrn_KaTSXR_r_EVM_TM1_TiConstrn_rt_Array_Float_126_88:0, KaTSXR_r_EVM_TM1_TiConstrn_KaTSXR_r_EVM_TM1_TiConstrn_rt_Array_Float_126_89:0, KaTSXR_r_EVM_TM1_TiConstrn_KaTSXR_r_EVM_TM1_TiConstrn_rt_Array_Float_126_90:0, KaTSXR_r_EVM_TM1_TiConstrn_KaTSXR_r_EVM_TM1_TiConstrn_rt_Array_Float_126_91:0, KaTSXR_r_EVM_TM1_TiConstrn_KaTSXR_r_EVM_TM1_TiConstrn_rt_Array_Float_126_92:0, KaTSXR_r_EVM_TM1_TiConstrn_KaTSXR_r_EVM_TM1_TiConstrn_rt_Array_Float_126_93:0, KaTSXR_r_EVM_TM1_TiConstrn_KaTSXR_r_EVM_TM1_TiConstrn_rt_Array_Float_126_94:0, KaTSXR_r_EVM_TM1_TiConstrn_KaTSXR_r_EVM_TM1_TiConstrn_rt_Array_Float_126_95:0, KaTSXR_r_EVM_TM1_TiConstrn_KaTSXR_r_EVM_TM1_TiConstrn_rt_Array_Float_126_96:0, KaTSXR_r_EVM_TM1_TiConstrn_KaTSXR_r_EVM_TM1_TiConstrn_rt_Array_Float_126_97:0, KaTSXR_r_EVM_TM1_TiConstrn_KaTSXR_r_EVM_TM1_TiConstrn_rt_Array_Float_126_98:0, KaTSXR_r_EVM_TM1_TiConstrn_KaTSXR_r_EVM_TM1_TiConstrn_rt_Array_Float_126_99:0, KaTSXR_r_EVM_TM1_TiConstrn_KaTSXR_r_EVM_TM1_TiConstrn_rt_Array_Float_126_100:0, KaTSXR_r_EVM_TM1_TiConstrn_KaTSXR_r_EVM_TM1_TiConstrn_rt_Array_Float_126_101:0, KaTSXR_r_EVM_TM1_TiConstrn_KaTSXR_r_EVM_TM1_TiConstrn_rt_Array_Float_126_102:0, KaTSXR_r_EVM_TM1_TiConstrn_KaTSXR_r_EVM_TM1_TiConstrn_rt_Array_Float_126_103:0, KaTSXR_r_EVM_TM1_TiConstrn_KaTSXR_r_EVM_TM1_TiConstrn_rt_Array_Float_126_104:0, KaTSXR_r_EVM_TM1_TiConstrn_KaTSXR_r_EVM_TM1_TiConstrn_rt_Array_Float_126_105:0, KaTSXR_r_EVM_TM1_TiConstrn_KaTSXR_r_EVM_TM1_TiConstrn_rt_Array_Float_126_106:0, KaTSXR_r_EVM_TM1_TiConstrn_KaTSXR_r_EVM_TM1_TiConstrn_rt_Array_Float_126_107:0, KaTSXR_r_EVM_TM1_TiConstrn_KaTSXR_r_EVM_TM1_TiConstrn_rt_Array_Float_126_108:0, KaTSXR_r_EVM_TM1_TiConstrn_KaTSXR_r_EVM_TM1_TiConstrn_rt_Array_Float_126_109:0, KaTSXR_r_EVM_TM1_TiConstrn_KaTSXR_r_EVM_TM1_TiConstrn_rt_Array_Float_126_110:0, KaTSXR_r_EVM_TM1_TiConstrn_KaTSXR_r_EVM_TM1_TiConstrn_rt_Array_Float_126_111:0, KaTSXR_r_EVM_TM1_TiConstrn_KaTSXR_r_EVM_TM1_TiConstrn_rt_Array_Float_126_112:0, KaTSXR_r_EVM_TM1_TiConstrn_KaTSXR_r_EVM_TM1_TiConstrn_rt_Array_Float_126_113:0, KaTSXR_r_EVM_TM1_TiConstrn_KaTSXR_r_EVM_TM1_TiConstrn_rt_Array_Float_126_114:0, KaTSXR_r_EVM_TM1_TiConstrn_KaTSXR_r_EVM_TM1_TiConstrn_rt_Array_Float_126_115:0, KaTSXR_r_EVM_TM1_TiConstrn_KaTSXR_r_EVM_TM1_TiConstrn_rt_Array_Float_126_116:0, KaTSXR_r_EVM_TM1_TiConstrn_KaTSXR_r_EVM_TM1_TiConstrn_rt_Array_Float_126_117:0, KaTSXR_r_EVM_TM1_TiConstrn_KaTSXR_r_EVM_TM1_TiConstrn_rt_Array_Float_126_118:0, KaTSXR_r_EVM_TM1_TiConstrn_KaTSXR_r_EVM_TM1_TiConstrn_rt_Array_Float_126_119:0, KaTSXR_r_EVM_TM1_TiConstrn_KaTSXR_r_EVM_TM1_TiConstrn_rt_Array_Float_126_120:0, KaTSXR_r_EVM_TM1_TiConstrn_KaTSXR_r_EVM_TM1_TiConstrn_rt_Array_Float_126_121:0, KaTSXR_r_EVM_TM1_TiConstrn_KaTSXR_r_EVM_TM1_TiConstrn_rt_Array_Float_126_122:0, KaTSXR_r_EVM_TM1_TiConstrn_KaTSXR_r_EVM_TM1_TiConstrn_rt_Array_Float_126_123:0, KaTSXR_r_EVM_TM1_TiConstrn_KaTSXR_r_EVM_TM1_TiConstrn_rt_Array_Float_126_124:0, KaTSXR_r_EVM_TM1_TiConstrn_KaTSXR_r_EVM_TM1_TiConstrn_rt_Array_Float_126_125:0, KaTSXR_r_EVM_TM1_TiConstrn_KaTSXR_r_EVM_TM1_TiConstrn_rt_Array_Float_126_126:0], parameter=KaTSXR_r_EVM_TM1_TiConstrn}, required-interface=KaTSXR_r_EVM_TM1_TiConstrn
      KaTSXR_r_EVM_TM1_ToConstrn: parameter-require-com-spec{init-value=KaTSXR_r_EVM_TM1_ToConstrn_KaTSXR_r_EVM_TM1_ToConstrn:[KaTSXR_r_EVM_TM1_ToConstrn_KaTSXR_r_EVM_TM1_ToConstrn_rt_Array_Float_126_1:0, KaTSXR_r_EVM_TM1_ToConstrn_KaTSXR_r_EVM_TM1_ToConstrn_rt_Array_Float_126_2:0, KaTSXR_r_EVM_TM1_ToConstrn_KaTSXR_r_EVM_TM1_ToConstrn_rt_Array_Float_126_3:0, KaTSXR_r_EVM_TM1_ToConstrn_KaTSXR_r_EVM_TM1_ToConstrn_rt_Array_Float_126_4:0, KaTSXR_r_EVM_TM1_ToConstrn_KaTSXR_r_EVM_TM1_ToConstrn_rt_Array_Float_126_5:0, KaTSXR_r_EVM_TM1_ToConstrn_KaTSXR_r_EVM_TM1_ToConstrn_rt_Array_Float_126_6:0, KaTSXR_r_EVM_TM1_ToConstrn_KaTSXR_r_EVM_TM1_ToConstrn_rt_Array_Float_126_7:0, KaTSXR_r_EVM_TM1_ToConstrn_KaTSXR_r_EVM_TM1_ToConstrn_rt_Array_Float_126_8:0, KaTSXR_r_EVM_TM1_ToConstrn_KaTSXR_r_EVM_TM1_ToConstrn_rt_Array_Float_126_9:0, KaTSXR_r_EVM_TM1_ToConstrn_KaTSXR_r_EVM_TM1_ToConstrn_rt_Array_Float_126_10:0, KaTSXR_r_EVM_TM1_ToConstrn_KaTSXR_r_EVM_TM1_ToConstrn_rt_Array_Float_126_11:0, KaTSXR_r_EVM_TM1_ToConstrn_KaTSXR_r_EVM_TM1_ToConstrn_rt_Array_Float_126_12:0, KaTSXR_r_EVM_TM1_ToConstrn_KaTSXR_r_EVM_TM1_ToConstrn_rt_Array_Float_126_13:0, KaTSXR_r_EVM_TM1_ToConstrn_KaTSXR_r_EVM_TM1_ToConstrn_rt_Array_Float_126_14:0, KaTSXR_r_EVM_TM1_ToConstrn_KaTSXR_r_EVM_TM1_ToConstrn_rt_Array_Float_126_15:0, KaTSXR_r_EVM_TM1_ToConstrn_KaTSXR_r_EVM_TM1_ToConstrn_rt_Array_Float_126_16:0, KaTSXR_r_EVM_TM1_ToConstrn_KaTSXR_r_EVM_TM1_ToConstrn_rt_Array_Float_126_17:0, KaTSXR_r_EVM_TM1_ToConstrn_KaTSXR_r_EVM_TM1_ToConstrn_rt_Array_Float_126_18:0, KaTSXR_r_EVM_TM1_ToConstrn_KaTSXR_r_EVM_TM1_ToConstrn_rt_Array_Float_126_19:0, KaTSXR_r_EVM_TM1_ToConstrn_KaTSXR_r_EVM_TM1_ToConstrn_rt_Array_Float_126_20:0, KaTSXR_r_EVM_TM1_ToConstrn_KaTSXR_r_EVM_TM1_ToConstrn_rt_Array_Float_126_21:0, KaTSXR_r_EVM_TM1_ToConstrn_KaTSXR_r_EVM_TM1_ToConstrn_rt_Array_Float_126_22:0, KaTSXR_r_EVM_TM1_ToConstrn_KaTSXR_r_EVM_TM1_ToConstrn_rt_Array_Float_126_23:0, KaTSXR_r_EVM_TM1_ToConstrn_KaTSXR_r_EVM_TM1_ToConstrn_rt_Array_Float_126_24:0, KaTSXR_r_EVM_TM1_ToConstrn_KaTSXR_r_EVM_TM1_ToConstrn_rt_Array_Float_126_25:0, KaTSXR_r_EVM_TM1_ToConstrn_KaTSXR_r_EVM_TM1_ToConstrn_rt_Array_Float_126_26:0, KaTSXR_r_EVM_TM1_ToConstrn_KaTSXR_r_EVM_TM1_ToConstrn_rt_Array_Float_126_27:0, KaTSXR_r_EVM_TM1_ToConstrn_KaTSXR_r_EVM_TM1_ToConstrn_rt_Array_Float_126_28:0, KaTSXR_r_EVM_TM1_ToConstrn_KaTSXR_r_EVM_TM1_ToConstrn_rt_Array_Float_126_29:0, KaTSXR_r_EVM_TM1_ToConstrn_KaTSXR_r_EVM_TM1_ToConstrn_rt_Array_Float_126_30:0, KaTSXR_r_EVM_TM1_ToConstrn_KaTSXR_r_EVM_TM1_ToConstrn_rt_Array_Float_126_31:0, KaTSXR_r_EVM_TM1_ToConstrn_KaTSXR_r_EVM_TM1_ToConstrn_rt_Array_Float_126_32:0, KaTSXR_r_EVM_TM1_ToConstrn_KaTSXR_r_EVM_TM1_ToConstrn_rt_Array_Float_126_33:0, KaTSXR_r_EVM_TM1_ToConstrn_KaTSXR_r_EVM_TM1_ToConstrn_rt_Array_Float_126_34:0, KaTSXR_r_EVM_TM1_ToConstrn_KaTSXR_r_EVM_TM1_ToConstrn_rt_Array_Float_126_35:0, KaTSXR_r_EVM_TM1_ToConstrn_KaTSXR_r_EVM_TM1_ToConstrn_rt_Array_Float_126_36:0, KaTSXR_r_EVM_TM1_ToConstrn_KaTSXR_r_EVM_TM1_ToConstrn_rt_Array_Float_126_37:0, KaTSXR_r_EVM_TM1_ToConstrn_KaTSXR_r_EVM_TM1_ToConstrn_rt_Array_Float_126_38:0, KaTSXR_r_EVM_TM1_ToConstrn_KaTSXR_r_EVM_TM1_ToConstrn_rt_Array_Float_126_39:0, KaTSXR_r_EVM_TM1_ToConstrn_KaTSXR_r_EVM_TM1_ToConstrn_rt_Array_Float_126_40:0, KaTSXR_r_EVM_TM1_ToConstrn_KaTSXR_r_EVM_TM1_ToConstrn_rt_Array_Float_126_41:0, KaTSXR_r_EVM_TM1_ToConstrn_KaTSXR_r_EVM_TM1_ToConstrn_rt_Array_Float_126_42:0, KaTSXR_r_EVM_TM1_ToConstrn_KaTSXR_r_EVM_TM1_ToConstrn_rt_Array_Float_126_43:0, KaTSXR_r_EVM_TM1_ToConstrn_KaTSXR_r_EVM_TM1_ToConstrn_rt_Array_Float_126_44:0, KaTSXR_r_EVM_TM1_ToConstrn_KaTSXR_r_EVM_TM1_ToConstrn_rt_Array_Float_126_45:0, KaTSXR_r_EVM_TM1_ToConstrn_KaTSXR_r_EVM_TM1_ToConstrn_rt_Array_Float_126_46:0, KaTSXR_r_EVM_TM1_ToConstrn_KaTSXR_r_EVM_TM1_ToConstrn_rt_Array_Float_126_47:0, KaTSXR_r_EVM_TM1_ToConstrn_KaTSXR_r_EVM_TM1_ToConstrn_rt_Array_Float_126_48:0, KaTSXR_r_EVM_TM1_ToConstrn_KaTSXR_r_EVM_TM1_ToConstrn_rt_Array_Float_126_49:0, KaTSXR_r_EVM_TM1_ToConstrn_KaTSXR_r_EVM_TM1_ToConstrn_rt_Array_Float_126_50:0, KaTSXR_r_EVM_TM1_ToConstrn_KaTSXR_r_EVM_TM1_ToConstrn_rt_Array_Float_126_51:0, KaTSXR_r_EVM_TM1_ToConstrn_KaTSXR_r_EVM_TM1_ToConstrn_rt_Array_Float_126_52:0, KaTSXR_r_EVM_TM1_ToConstrn_KaTSXR_r_EVM_TM1_ToConstrn_rt_Array_Float_126_53:0, KaTSXR_r_EVM_TM1_ToConstrn_KaTSXR_r_EVM_TM1_ToConstrn_rt_Array_Float_126_54:0, KaTSXR_r_EVM_TM1_ToConstrn_KaTSXR_r_EVM_TM1_ToConstrn_rt_Array_Float_126_55:0, KaTSXR_r_EVM_TM1_ToConstrn_KaTSXR_r_EVM_TM1_ToConstrn_rt_Array_Float_126_56:0, KaTSXR_r_EVM_TM1_ToConstrn_KaTSXR_r_EVM_TM1_ToConstrn_rt_Array_Float_126_57:0, KaTSXR_r_EVM_TM1_ToConstrn_KaTSXR_r_EVM_TM1_ToConstrn_rt_Array_Float_126_58:0, KaTSXR_r_EVM_TM1_ToConstrn_KaTSXR_r_EVM_TM1_ToConstrn_rt_Array_Float_126_59:0, KaTSXR_r_EVM_TM1_ToConstrn_KaTSXR_r_EVM_TM1_ToConstrn_rt_Array_Float_126_60:0, KaTSXR_r_EVM_TM1_ToConstrn_KaTSXR_r_EVM_TM1_ToConstrn_rt_Array_Float_126_61:0, KaTSXR_r_EVM_TM1_ToConstrn_KaTSXR_r_EVM_TM1_ToConstrn_rt_Array_Float_126_62:0, KaTSXR_r_EVM_TM1_ToConstrn_KaTSXR_r_EVM_TM1_ToConstrn_rt_Array_Float_126_63:0, KaTSXR_r_EVM_TM1_ToConstrn_KaTSXR_r_EVM_TM1_ToConstrn_rt_Array_Float_126_64:0, KaTSXR_r_EVM_TM1_ToConstrn_KaTSXR_r_EVM_TM1_ToConstrn_rt_Array_Float_126_65:0, KaTSXR_r_EVM_TM1_ToConstrn_KaTSXR_r_EVM_TM1_ToConstrn_rt_Array_Float_126_66:0, KaTSXR_r_EVM_TM1_ToConstrn_KaTSXR_r_EVM_TM1_ToConstrn_rt_Array_Float_126_67:0, KaTSXR_r_EVM_TM1_ToConstrn_KaTSXR_r_EVM_TM1_ToConstrn_rt_Array_Float_126_68:0, KaTSXR_r_EVM_TM1_ToConstrn_KaTSXR_r_EVM_TM1_ToConstrn_rt_Array_Float_126_69:0, KaTSXR_r_EVM_TM1_ToConstrn_KaTSXR_r_EVM_TM1_ToConstrn_rt_Array_Float_126_70:0, KaTSXR_r_EVM_TM1_ToConstrn_KaTSXR_r_EVM_TM1_ToConstrn_rt_Array_Float_126_71:0, KaTSXR_r_EVM_TM1_ToConstrn_KaTSXR_r_EVM_TM1_ToConstrn_rt_Array_Float_126_72:0, KaTSXR_r_EVM_TM1_ToConstrn_KaTSXR_r_EVM_TM1_ToConstrn_rt_Array_Float_126_73:0, KaTSXR_r_EVM_TM1_ToConstrn_KaTSXR_r_EVM_TM1_ToConstrn_rt_Array_Float_126_74:0, KaTSXR_r_EVM_TM1_ToConstrn_KaTSXR_r_EVM_TM1_ToConstrn_rt_Array_Float_126_75:0, KaTSXR_r_EVM_TM1_ToConstrn_KaTSXR_r_EVM_TM1_ToConstrn_rt_Array_Float_126_76:0, KaTSXR_r_EVM_TM1_ToConstrn_KaTSXR_r_EVM_TM1_ToConstrn_rt_Array_Float_126_77:0, KaTSXR_r_EVM_TM1_ToConstrn_KaTSXR_r_EVM_TM1_ToConstrn_rt_Array_Float_126_78:0, KaTSXR_r_EVM_TM1_ToConstrn_KaTSXR_r_EVM_TM1_ToConstrn_rt_Array_Float_126_79:0, KaTSXR_r_EVM_TM1_ToConstrn_KaTSXR_r_EVM_TM1_ToConstrn_rt_Array_Float_126_80:0, KaTSXR_r_EVM_TM1_ToConstrn_KaTSXR_r_EVM_TM1_ToConstrn_rt_Array_Float_126_81:0, KaTSXR_r_EVM_TM1_ToConstrn_KaTSXR_r_EVM_TM1_ToConstrn_rt_Array_Float_126_82:0, KaTSXR_r_EVM_TM1_ToConstrn_KaTSXR_r_EVM_TM1_ToConstrn_rt_Array_Float_126_83:0, KaTSXR_r_EVM_TM1_ToConstrn_KaTSXR_r_EVM_TM1_ToConstrn_rt_Array_Float_126_84:0, KaTSXR_r_EVM_TM1_ToConstrn_KaTSXR_r_EVM_TM1_ToConstrn_rt_Array_Float_126_85:0, KaTSXR_r_EVM_TM1_ToConstrn_KaTSXR_r_EVM_TM1_ToConstrn_rt_Array_Float_126_86:0, KaTSXR_r_EVM_TM1_ToConstrn_KaTSXR_r_EVM_TM1_ToConstrn_rt_Array_Float_126_87:0, KaTSXR_r_EVM_TM1_ToConstrn_KaTSXR_r_EVM_TM1_ToConstrn_rt_Array_Float_126_88:0, KaTSXR_r_EVM_TM1_ToConstrn_KaTSXR_r_EVM_TM1_ToConstrn_rt_Array_Float_126_89:0, KaTSXR_r_EVM_TM1_ToConstrn_KaTSXR_r_EVM_TM1_ToConstrn_rt_Array_Float_126_90:0, KaTSXR_r_EVM_TM1_ToConstrn_KaTSXR_r_EVM_TM1_ToConstrn_rt_Array_Float_126_91:0, KaTSXR_r_EVM_TM1_ToConstrn_KaTSXR_r_EVM_TM1_ToConstrn_rt_Array_Float_126_92:0, KaTSXR_r_EVM_TM1_ToConstrn_KaTSXR_r_EVM_TM1_ToConstrn_rt_Array_Float_126_93:0, KaTSXR_r_EVM_TM1_ToConstrn_KaTSXR_r_EVM_TM1_ToConstrn_rt_Array_Float_126_94:0, KaTSXR_r_EVM_TM1_ToConstrn_KaTSXR_r_EVM_TM1_ToConstrn_rt_Array_Float_126_95:0, KaTSXR_r_EVM_TM1_ToConstrn_KaTSXR_r_EVM_TM1_ToConstrn_rt_Array_Float_126_96:0, KaTSXR_r_EVM_TM1_ToConstrn_KaTSXR_r_EVM_TM1_ToConstrn_rt_Array_Float_126_97:0, KaTSXR_r_EVM_TM1_ToConstrn_KaTSXR_r_EVM_TM1_ToConstrn_rt_Array_Float_126_98:0, KaTSXR_r_EVM_TM1_ToConstrn_KaTSXR_r_EVM_TM1_ToConstrn_rt_Array_Float_126_99:0, KaTSXR_r_EVM_TM1_ToConstrn_KaTSXR_r_EVM_TM1_ToConstrn_rt_Array_Float_126_100:0, KaTSXR_r_EVM_TM1_ToConstrn_KaTSXR_r_EVM_TM1_ToConstrn_rt_Array_Float_126_101:0, KaTSXR_r_EVM_TM1_ToConstrn_KaTSXR_r_EVM_TM1_ToConstrn_rt_Array_Float_126_102:0, KaTSXR_r_EVM_TM1_ToConstrn_KaTSXR_r_EVM_TM1_ToConstrn_rt_Array_Float_126_103:0, KaTSXR_r_EVM_TM1_ToConstrn_KaTSXR_r_EVM_TM1_ToConstrn_rt_Array_Float_126_104:0, KaTSXR_r_EVM_TM1_ToConstrn_KaTSXR_r_EVM_TM1_ToConstrn_rt_Array_Float_126_105:0, KaTSXR_r_EVM_TM1_ToConstrn_KaTSXR_r_EVM_TM1_ToConstrn_rt_Array_Float_126_106:0, KaTSXR_r_EVM_TM1_ToConstrn_KaTSXR_r_EVM_TM1_ToConstrn_rt_Array_Float_126_107:0, KaTSXR_r_EVM_TM1_ToConstrn_KaTSXR_r_EVM_TM1_ToConstrn_rt_Array_Float_126_108:0, KaTSXR_r_EVM_TM1_ToConstrn_KaTSXR_r_EVM_TM1_ToConstrn_rt_Array_Float_126_109:0, KaTSXR_r_EVM_TM1_ToConstrn_KaTSXR_r_EVM_TM1_ToConstrn_rt_Array_Float_126_110:0, KaTSXR_r_EVM_TM1_ToConstrn_KaTSXR_r_EVM_TM1_ToConstrn_rt_Array_Float_126_111:0, KaTSXR_r_EVM_TM1_ToConstrn_KaTSXR_r_EVM_TM1_ToConstrn_rt_Array_Float_126_112:0, KaTSXR_r_EVM_TM1_ToConstrn_KaTSXR_r_EVM_TM1_ToConstrn_rt_Array_Float_126_113:0, KaTSXR_r_EVM_TM1_ToConstrn_KaTSXR_r_EVM_TM1_ToConstrn_rt_Array_Float_126_114:0, KaTSXR_r_EVM_TM1_ToConstrn_KaTSXR_r_EVM_TM1_ToConstrn_rt_Array_Float_126_115:0, KaTSXR_r_EVM_TM1_ToConstrn_KaTSXR_r_EVM_TM1_ToConstrn_rt_Array_Float_126_116:0, KaTSXR_r_EVM_TM1_ToConstrn_KaTSXR_r_EVM_TM1_ToConstrn_rt_Array_Float_126_117:0, KaTSXR_r_EVM_TM1_ToConstrn_KaTSXR_r_EVM_TM1_ToConstrn_rt_Array_Float_126_118:0, KaTSXR_r_EVM_TM1_ToConstrn_KaTSXR_r_EVM_TM1_ToConstrn_rt_Array_Float_126_119:0, KaTSXR_r_EVM_TM1_ToConstrn_KaTSXR_r_EVM_TM1_ToConstrn_rt_Array_Float_126_120:0, KaTSXR_r_EVM_TM1_ToConstrn_KaTSXR_r_EVM_TM1_ToConstrn_rt_Array_Float_126_121:0, KaTSXR_r_EVM_TM1_ToConstrn_KaTSXR_r_EVM_TM1_ToConstrn_rt_Array_Float_126_122:0, KaTSXR_r_EVM_TM1_ToConstrn_KaTSXR_r_EVM_TM1_ToConstrn_rt_Array_Float_126_123:0, KaTSXR_r_EVM_TM1_ToConstrn_KaTSXR_r_EVM_TM1_ToConstrn_rt_Array_Float_126_124:0, KaTSXR_r_EVM_TM1_ToConstrn_KaTSXR_r_EVM_TM1_ToConstrn_rt_Array_Float_126_125:0, KaTSXR_r_EVM_TM1_ToConstrn_KaTSXR_r_EVM_TM1_ToConstrn_rt_Array_Float_126_126:0], parameter=KaTSXR_r_EVM_TM1_ToConstrn}, required-interface=KaTSXR_r_EVM_TM1_ToConstrn
